VERSION "HINBNNNYNNNNNNNNNNNNNNNNNNNNNNNNNNNYYNNNNN/4>%%%/4/'%**4NNN///"

NS_ :

BS_:

BU_: Traffic Tester CGW ADU
BO_ 2564550625 Functional_Diag_RequestOn_bo: 8 CGW
 SG_ Sig_Functional_Diag_RequestOn_bo : 7|64@0+ (1,0) [0|0] ""  ADU

BO_ 2564481413 FLR_Diag_Tx_E1: 32 ADU
 SG_ Sig_FLR_Diag_Tx_E1 : 7|256@0+ (1,0) [0|0] ""  CGW

BO_ 2564457953 FLR_Diag_Rx_E1: 32 CGW
 SG_ Sig_FLR_Diag_Rx_E1 : 7|256@0+ (1,0) [0|0] ""  ADU

BO_ 2564481412 FRR_Diag_Tx_E1: 32 ADU
 SG_ Sig_FRR_Diag_Tx_E1 : 7|256@0+ (1,0) [0|0] ""  CGW

BO_ 2564457697 FRR_Diag_Rx_E1: 32 CGW
 SG_ Sig_FRR_Diag_Rx_E1 : 7|256@0+ (1,0) [0|0] ""  ADU

BO_ 2564481411 RLR_Diag_Tx_E1: 32 ADU
 SG_ Sig_RLR_Diag_Tx_E1 : 7|256@0+ (1,0) [0|0] ""  CGW

BO_ 2564457441 RLR_Diag_Rx_E1: 32 CGW
 SG_ Sig_RLR_Diag_Rx_E1 : 7|256@0+ (1,0) [0|0] ""  ADU

BO_ 2564481410 RRR_Diag_Tx_E1: 32 ADU
 SG_ Sig_RRR_Diag_Tx_E1 : 7|256@0+ (1,0) [0|0] ""  CGW

BO_ 2564457185 RRR_Diag_Rx_E1: 32 CGW
 SG_ Sig_RRR_Diag_Rx_E1 : 7|256@0+ (1,0) [0|0] ""  ADU

BO_ 2564481397 ADU_Diag_Tx_E1: 32 ADU
 SG_ Sig_ADU_Diag_Tx_E1 : 7|256@0+ (1,0) [0|0] ""  CGW

BO_ 2564453857 ADU_Diag_Rx_E1: 32 CGW
 SG_ Sig_ADU_Diag_Rx_E1 : 7|256@0+ (1,0) [0|0] ""  ADU

BO_ 2564481392 FRD_Diag_Tx_E1: 32 ADU
 SG_ Sig_FRD_Diag_Tx_E1 : 7|256@0+ (1,0) [0|0] ""  CGW

BO_ 2564452577 FRD_Diag_Rx_E1: 32 CGW
 SG_ Sig_FRD_Diag_Rx_E1 : 7|256@0+ (1,0) [0|0] ""  ADU

BO_ 2564550624 Functional_Diag_RequestOff_b: 8 CGW
 SG_ Sig_Functional_Diag_RequestOff_b : 7|64@0+ (1,0) [0|0] ""  ADU

BO_ 2564481157 FLR_Diag_Tx_E0: 32 ADU
 SG_ Sig_FLR_Diag_Tx_E0 : 7|256@0+ (1,0) [0|0] ""  CGW

BO_ 2564457952 FLR_Diag_Rx_E0: 32 CGW
 SG_ Sig_FLR_Diag_Rx_E0 : 7|256@0+ (1,0) [0|0] ""  ADU

BO_ 2564481156 FRR_Diag_Tx_E0: 32 ADU
 SG_ Sig_FRR_Diag_Tx_E0 : 7|256@0+ (1,0) [0|0] ""  CGW

BO_ 2564457696 FRR_Diag_Rx_E0: 32 CGW
 SG_ Sig_FRR_Diag_Rx_E0 : 7|256@0+ (1,0) [0|0] ""  ADU

BO_ 2564481155 RLR_Diag_Tx_E0: 32 ADU
 SG_ Sig_RLR_Diag_Tx_E0 : 7|256@0+ (1,0) [0|0] ""  CGW

BO_ 2564457440 RLR_Diag_Rx_E0: 32 CGW
 SG_ Sig_RLR_Diag_Rx_E0 : 7|256@0+ (1,0) [0|0] ""  ADU

BO_ 2564481154 RRR_Diag_Tx_E0: 32 ADU
 SG_ Sig_RRR_Diag_Tx_E0 : 7|256@0+ (1,0) [0|0] ""  CGW

BO_ 2564457184 RRR_Diag_Rx_E0: 32 CGW
 SG_ Sig_RRR_Diag_Rx_E0 : 7|256@0+ (1,0) [0|0] ""  ADU

BO_ 2564481141 ADU_Diag_Tx_E0: 32 ADU
 SG_ Sig_ADU_Diag_Tx_E0 : 7|256@0+ (1,0) [0|0] ""  CGW

BO_ 2564453856 ADU_Diag_Rx_E0: 32 CGW
 SG_ Sig_ADU_Diag_Rx_E0 : 7|256@0+ (1,0) [0|0] ""  ADU

BO_ 2564481136 FRD_Diag_Tx_E0: 32 ADU
 SG_ Sig_FRD_Diag_Tx_E0 : 7|256@0+ (1,0) [0|0] ""  CGW

BO_ 2564452576 FRD_Diag_Rx_E0: 32 CGW
 SG_ Sig_FRD_Diag_Rx_E0 : 7|256@0+ (1,0) [0|0] ""  ADU

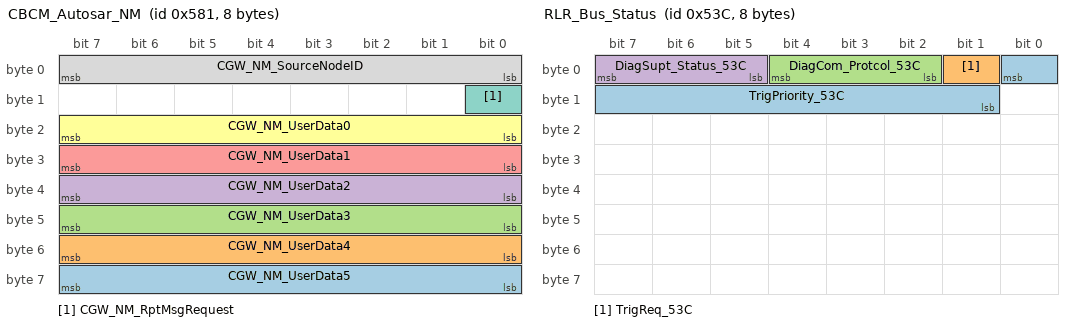
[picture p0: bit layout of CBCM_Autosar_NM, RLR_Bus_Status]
BO_ 1409 CBCM_Autosar_NM: 8 CGW
 SG_ CGW_NM_UserData5 : 63|8@0+ (1,0) [0|255] "" Vector__XXX
 SG_ CGW_NM_UserData4 : 55|8@0+ (1,0) [0|255] "" Vector__XXX
 SG_ CGW_NM_UserData3 : 47|8@0+ (1,0) [0|255] "" Vector__XXX
 SG_ CGW_NM_UserData2 : 39|8@0+ (1,0) [0|255] "" Vector__XXX
 SG_ CGW_NM_UserData1 : 31|8@0+ (1,0) [0|255] "" Vector__XXX
 SG_ CGW_NM_UserData0 : 23|8@0+ (1,0) [0|255] "" Vector__XXX
 SG_ CGW_NM_RptMsgRequest : 8|1@0+ (1,0) [0|1] ""  ADU
 SG_ CGW_NM_SourceNodeID : 7|8@0+ (1,0) [0|255] ""  ADU

BO_ 1340 RLR_Bus_Status: 8 ADU
 SG_ TrigPriority_53C : 0|8@0+ (1,0) [0|255] "HEX"  CGW
 SG_ TrigReq_53C : 1|1@0+ (1,0) [0|0] ""  CGW
 SG_ DiagCom_Protcol_53C : 4|3@0+ (1,0) [0|0] ""  CGW
 SG_ DiagSupt_Status_53C : 7|3@0+ (1,0) [0|0] ""  CGW

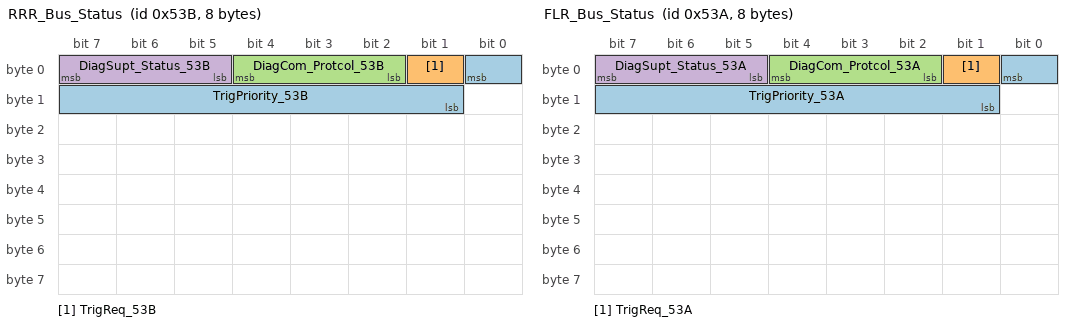
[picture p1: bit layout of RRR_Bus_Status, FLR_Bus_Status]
BO_ 1339 RRR_Bus_Status: 8 ADU
 SG_ TrigPriority_53B : 0|8@0+ (1,0) [0|255] "HEX"  CGW
 SG_ TrigReq_53B : 1|1@0+ (1,0) [0|0] ""  CGW
 SG_ DiagCom_Protcol_53B : 4|3@0+ (1,0) [0|0] ""  CGW
 SG_ DiagSupt_Status_53B : 7|3@0+ (1,0) [0|0] ""  CGW

BO_ 1338 FLR_Bus_Status: 8 ADU
 SG_ TrigPriority_53A : 0|8@0+ (1,0) [0|255] "HEX"  CGW
 SG_ TrigReq_53A : 1|1@0+ (1,0) [0|0] ""  CGW
 SG_ DiagCom_Protcol_53A : 4|3@0+ (1,0) [0|0] ""  CGW
 SG_ DiagSupt_Status_53A : 7|3@0+ (1,0) [0|0] ""  CGW

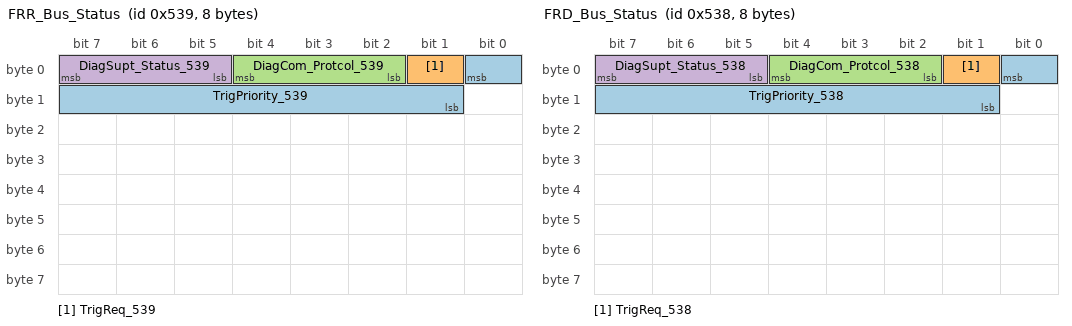
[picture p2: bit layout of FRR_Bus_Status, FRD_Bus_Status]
BO_ 1337 FRR_Bus_Status: 8 ADU
 SG_ TrigPriority_539 : 0|8@0+ (1,0) [0|255] "HEX"  CGW
 SG_ TrigReq_539 : 1|1@0+ (1,0) [0|0] ""  CGW
 SG_ DiagCom_Protcol_539 : 4|3@0+ (1,0) [0|0] ""  CGW
 SG_ DiagSupt_Status_539 : 7|3@0+ (1,0) [0|0] ""  CGW

BO_ 1336 FRD_Bus_Status: 8 ADU
 SG_ TrigPriority_538 : 0|8@0+ (1,0) [0|255] "HEX"  CGW
 SG_ TrigReq_538 : 1|1@0+ (1,0) [0|0] ""  CGW
 SG_ DiagCom_Protcol_538 : 4|3@0+ (1,0) [0|0] ""  CGW
 SG_ DiagSupt_Status_538 : 7|3@0+ (1,0) [0|0] ""  CGW

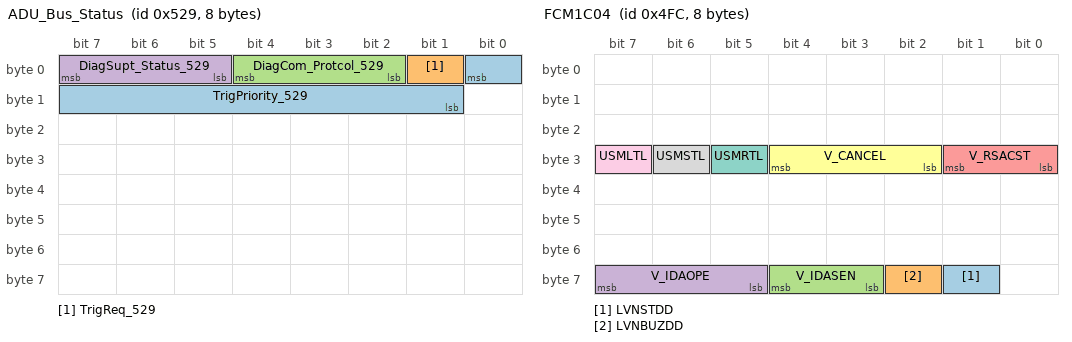
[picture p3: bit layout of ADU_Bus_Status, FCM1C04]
BO_ 1321 ADU_Bus_Status: 8 ADU
 SG_ TrigPriority_529 : 0|8@0+ (1,0) [0|255] "HEX"  CGW
 SG_ TrigReq_529 : 1|1@0+ (1,0) [0|0] ""  CGW
 SG_ DiagCom_Protcol_529 : 4|3@0+ (1,0) [0|0] ""  CGW
 SG_ DiagSupt_Status_529 : 7|3@0+ (1,0) [0|0] ""  CGW

BO_ 1276 FCM1C04: 8 ADU
 SG_ LVNSTDD : 57|1@0+ (1,0) [0|1] ""  CGW
 SG_ LVNBUZDD : 58|1@0+ (1,0) [0|1] ""  CGW
 SG_ V_IDASEN : 60|2@0+ (1,0) [0|0] ""  CGW
 SG_ V_IDAOPE : 63|3@0+ (1,0) [0|0] ""  CGW
 SG_ V_RSACST : 25|2@0+ (1,0) [0|3] ""  CGW
 SG_ V_CANCEL : 28|3@0+ (1,0) [0|7] ""  CGW
 SG_ USMRTL : 29|1@0+ (1,0) [0|0] ""  CGW
 SG_ USMSTL : 30|1@0+ (1,0) [0|0] ""  CGW
 SG_ USMLTL : 31|1@0+ (1,0) [0|0] ""  CGW

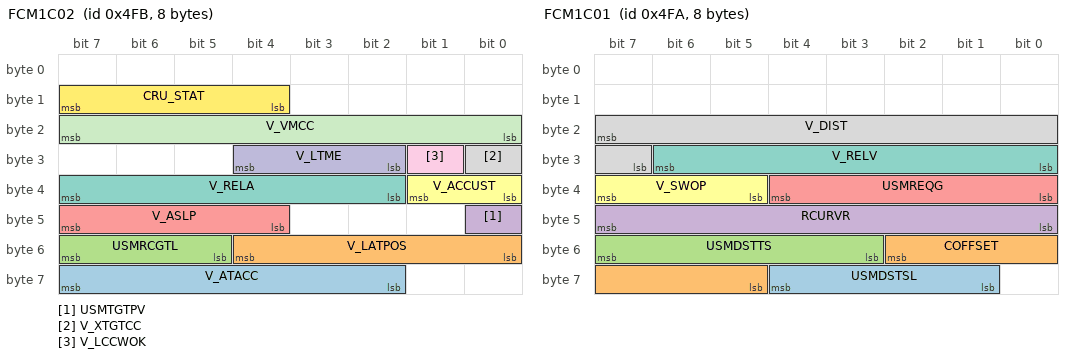
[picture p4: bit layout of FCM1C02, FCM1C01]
BO_ 1275 FCM1C02: 8 ADU
 SG_ V_ATACC : 63|6@0- (0.2,0) [-6.4|6.2] "m/s^2"  CGW
 SG_ V_LATPOS : 52|5@0- (0.4,0) [-6.4|6] "m/s2"  CGW
 SG_ USMRCGTL : 55|3@0+ (1,0) [0|0] ""  CGW
 SG_ USMTGTPV : 40|1@0+ (1,0) [0|0] ""  CGW
 SG_ V_ASLP : 47|4@0- (1,0) [-8|7] "deg"  CGW
 SG_ V_ACCUST : 33|2@0+ (1,0) [0|3] ""  CGW
 SG_ V_RELA : 39|6@0- (0.4,0) [-12.8|12.4] "m/s2"  CGW
 SG_ V_XTGTCC : 24|1@0+ (1,0) [0|1] ""  CGW
 SG_ V_LCCWOK : 25|1@0+ (1,0) [0|1] ""  CGW
 SG_ V_LTME : 28|3@0+ (1,0) [0|7] ""  CGW
 SG_ V_VMCC : 23|8@0+ (1,0) [0|255] "km/h"  CGW
 SG_ CRU_STAT : 15|4@0+ (1,0) [0|15] ""  CGW

BO_ 1274 FCM1C01: 8 ADU
 SG_ USMDSTSL : 60|4@0+ (4,0) [0|60] "m"  CGW
 SG_ COFFSET : 50|6@0- (0.03,0) [-0.96|0.93] "m"  CGW
 SG_ USMDSTTS : 55|5@0+ (5,0) [0|155] "m"  CGW
 SG_ RCURVR : 47|8@0- (10,0) [-1280|1270] "m"  CGW
 SG_ USMREQG : 36|5@0+ (0.1,-3.1) [-3.1|0] "m/s^2"  CGW
 SG_ V_SWOP : 39|3@0+ (1,0) [0|7] ""  CGW
 SG_ V_RELV : 30|7@0- (0.2,0) [-12.8|12.4] "m/s"  CGW
 SG_ V_DIST : 23|9@0+ (0.5,0) [0|255.5] "m"  CGW

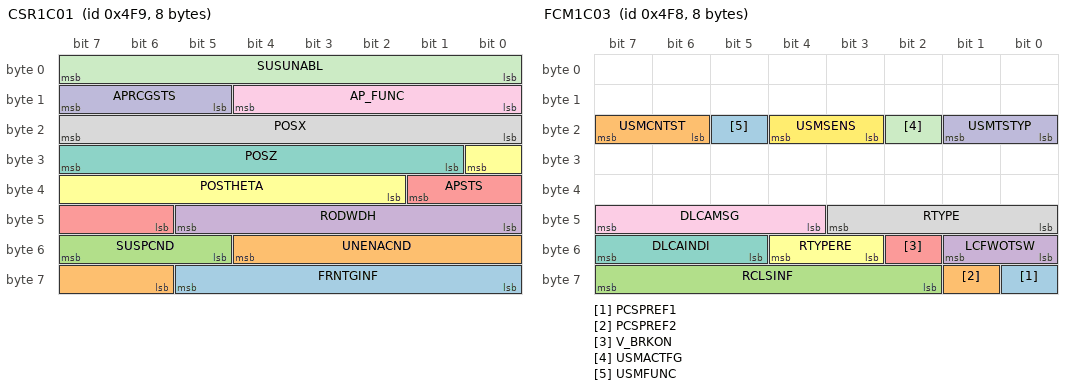
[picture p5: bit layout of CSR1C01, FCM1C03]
BO_ 1273 CSR1C01: 8 ADU
 SG_ FRNTGINF : 61|6@0+ (0.2,0) [0|12.6] "m"  CGW
 SG_ UNENACND : 52|7@0+ (1,0) [0|127] ""  CGW
 SG_ SUSPCND : 55|3@0+ (1,0) [0|7] ""  CGW
 SG_ RODWDH : 45|6@0+ (0.2,0) [0|12.6] "m"  CGW
 SG_ APSTS : 33|4@0+ (1,0) [0|15] ""  CGW
 SG_ POSTHETA : 24|7@0- (1.5,90) [-6|184.5] "deg"  CGW
 SG_ POSZ : 31|7@0- (0.1,5) [-1.4|11.3] "m"  CGW
 SG_ POSX : 23|8@0- (0.1,0) [-12.8|12.6] "m"  CGW
 SG_ AP_FUNC : 12|5@0+ (1,0) [0|31] ""  CGW
 SG_ APRCGSTS : 15|3@0+ (1,0) [0|7] ""  CGW
 SG_ SUSUNABL : 7|8@0+ (1,0) [0|255] ""  CGW

BO_ 1272 FCM1C03: 8 ADU
 SG_ PCSPREF1 : 56|1@0+ (1,0) [0|1] ""  CGW
 SG_ PCSPREF2 : 57|1@0+ (1,0) [0|1] ""  CGW
 SG_ RCLSINF : 63|6@0+ (1,0) [0|63] ""  CGW
 SG_ LCFWOTSW : 49|2@0+ (1,0) [0|3] ""  CGW
 SG_ V_BRKON : 50|1@0+ (1,0) [0|1] ""  CGW
 SG_ RTYPERE : 52|2@0+ (1,0) [0|3] ""  CGW
 SG_ DLCAINDI : 55|3@0+ (1,0) [0|7] ""  CGW
 SG_ RTYPE : 43|4@0+ (1,0) [0|15] ""  CGW
 SG_ DLCAMSG : 47|4@0+ (1,0) [0|15] ""  CGW
 SG_ USMTSTYP : 17|2@0+ (1,0) [0|0] ""  CGW
 SG_ USMACTFG : 18|1@0+ (1,0) [0|0] ""  CGW
 SG_ USMSENS : 20|2@0+ (1,0) [0|0] ""  CGW
 SG_ USMFUNC : 21|1@0+ (1,0) [0|0] ""  CGW
 SG_ USMCNTST : 23|2@0+ (1,0) [0|0] ""  CGW

BO_ 1269 CSR1D80: 32 ADU
 SG_ EDRAP : 250|3@0+ (1,0) [0|7] ""  CGW
 SG_ EDRRCP : 253|3@0+ (1,0) [0|7] ""  CGW

BO_ 1268 ADU1N01: 8 ADU
 SG_ ADUREV : 7|8@0+ (1,0) [0|255] ""  CGW

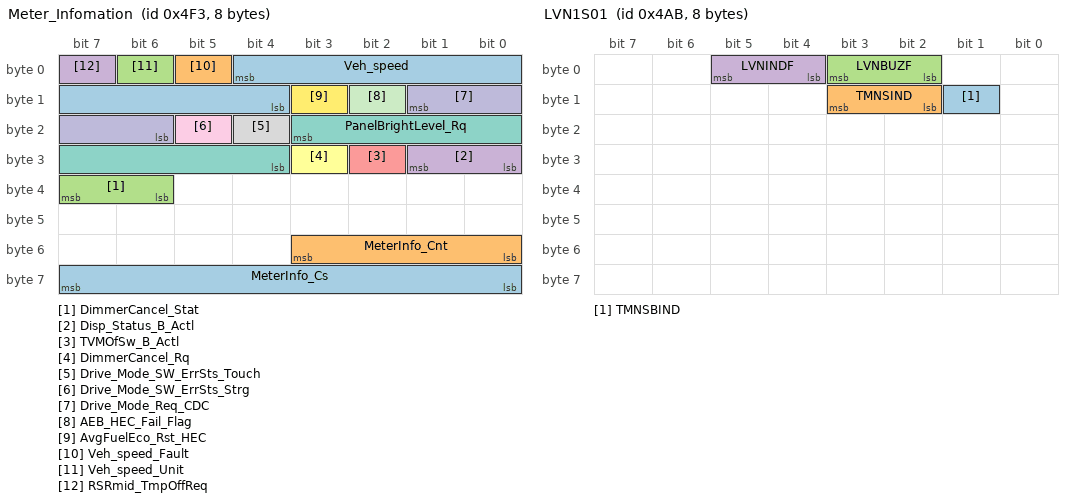
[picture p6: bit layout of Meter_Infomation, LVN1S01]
BO_ 1267 Meter_Infomation: 8 CGW
 SG_ MeterInfo_Cs : 63|8@0+ (1,0) [0|255] ""  ADU
 SG_ MeterInfo_Cnt : 51|4@0+ (1,0) [0|15] ""  ADU
 SG_ DimmerCancel_Stat : 39|2@0+ (1,0) [0|0] "" Vector__XXX
 SG_ Disp_Status_B_Actl : 25|2@0+ (1,0) [0|0] ""  ADU
 SG_ TVMOfSw_B_Actl : 26|1@0+ (1,0) [0|0] ""  ADU
 SG_ DimmerCancel_Rq : 27|1@0+ (1,0) [0|0] "" Vector__XXX
 SG_ PanelBrightLevel_Rq : 19|8@0+ (1,0) [0|100] "%" Vector__XXX
 SG_ Drive_Mode_SW_ErrSts_Touch : 20|1@0+ (1,0) [0|0] "" Vector__XXX
 SG_ Drive_Mode_SW_ErrSts_Strg : 21|1@0+ (1,0) [0|0] "" Vector__XXX
 SG_ Drive_Mode_Req_CDC : 9|4@0+ (1,0) [0|0] "" Vector__XXX
 SG_ AEB_HEC_Fail_Flag : 10|1@0+ (1,0) [0|0] ""  ADU
 SG_ AvgFuelEco_Rst_HEC : 11|1@0+ (1,0) [0|0] "" Vector__XXX
 SG_ Veh_speed : 4|9@0+ (1,0) [0|511] ""  ADU
 SG_ Veh_speed_Fault : 5|1@0+ (1,0) [0|0] ""  ADU
 SG_ Veh_speed_Unit : 6|1@0+ (1,0) [0|0] ""  ADU
 SG_ RSRmid_TmpOffReq : 7|1@0+ (1,0) [0|0] "" Vector__XXX

BO_ 1259 DS11S40: 8 ADU
 SG_ CTACANC : 19|1@0+ (1,0) [0|1] ""  CGW

BO_ 1258 DS11S27: 8 ADU
 SG_ HELPREQ : 43|1@0+ (1,0) [0|0] ""  CGW

BO_ 1256 RSE1S02: 8 CGW
 SG_ RSCYCL16 : 63|8@0+ (1,0) [0|255] ""  ADU
 SG_ RSCYCL15 : 55|8@0+ (1,0) [0|255] ""  ADU

BO_ 1195 LVN1S01: 8 ADU
 SG_ TMNSBIND : 9|1@0+ (1,0) [0|1] ""  CGW
 SG_ TMNSIND : 11|2@0+ (1,0) [0|3] ""  CGW
 SG_ LVNBUZF : 3|2@0+ (1,0) [0|3] ""  CGW
 SG_ LVNINDF : 5|2@0+ (1,0) [0|3] ""  CGW

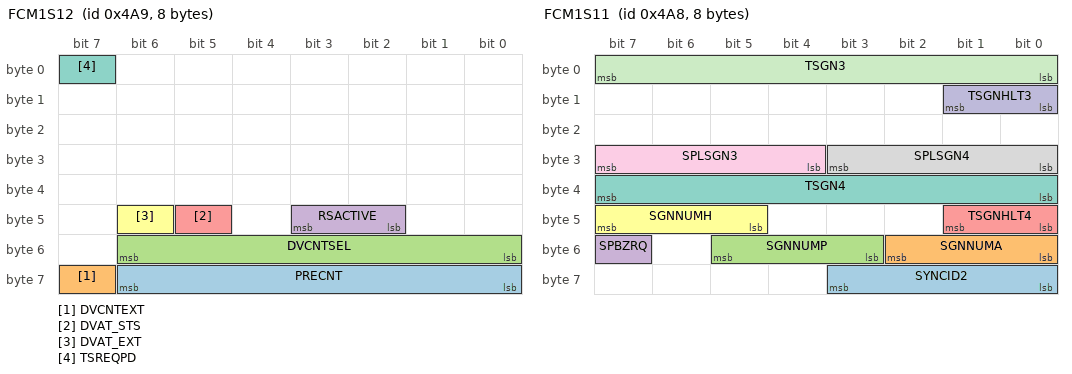
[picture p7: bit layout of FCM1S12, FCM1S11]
BO_ 1193 FCM1S12: 8 ADU
 SG_ PRECNT : 62|7@0+ (1,0) [0|127] ""  CGW
 SG_ DVCNTEXT : 63|1@0+ (1,0) [0|1] ""  CGW
 SG_ DVCNTSEL : 54|7@0+ (1,0) [0|127] ""  CGW
 SG_ RSACTIVE : 43|2@0+ (1,0) [0|3] ""  CGW
 SG_ DVAT_STS : 45|1@0+ (1,0) [0|1] ""  CGW
 SG_ DVAT_EXT : 46|1@0+ (1,0) [0|1] ""  CGW
 SG_ TSREQPD : 7|1@0+ (1,0) [0|1] ""  CGW

BO_ 1192 FCM1S11: 8 ADU
 SG_ SYNCID2 : 59|4@0+ (1,0) [0|15] ""  CGW
 SG_ SGNNUMA : 50|3@0+ (1,0) [0|7] ""  CGW
 SG_ SGNNUMP : 53|3@0+ (1,0) [0|7] ""  CGW
 SG_ SPBZRQ : 55|1@0+ (1,0) [0|1] ""  CGW
 SG_ TSGNHLT4 : 41|2@0+ (1,0) [0|3] ""  CGW
 SG_ SGNNUMH : 47|3@0+ (1,0) [0|7] ""  CGW
 SG_ TSGN4 : 39|8@0+ (1,0) [0|255] ""  CGW
 SG_ SPLSGN4 : 27|4@0+ (1,0) [0|15] ""  CGW
 SG_ SPLSGN3 : 31|4@0+ (1,0) [0|15] ""  CGW
 SG_ TSGNHLT3 : 9|2@0+ (1,0) [0|3] ""  CGW
 SG_ TSGN3 : 7|8@0+ (1,0) [0|255] ""  CGW

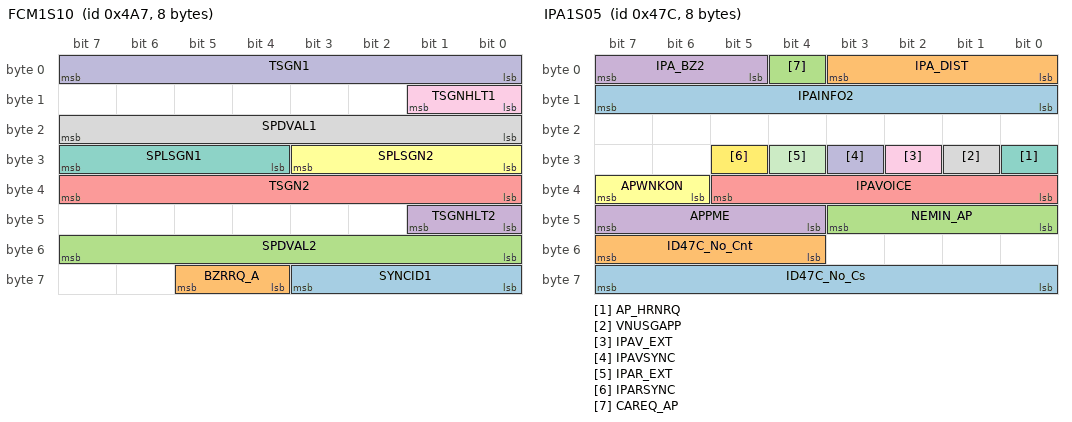
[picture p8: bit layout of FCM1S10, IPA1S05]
BO_ 1191 FCM1S10: 8 ADU
 SG_ SYNCID1 : 59|4@0+ (1,0) [0|15] ""  CGW
 SG_ BZRRQ_A : 61|2@0+ (1,0) [0|3] ""  CGW
 SG_ SPDVAL2 : 55|8@0+ (1,0) [0|255] ""  CGW
 SG_ TSGNHLT2 : 41|2@0+ (1,0) [0|3] ""  CGW
 SG_ TSGN2 : 39|8@0+ (1,0) [0|255] ""  CGW
 SG_ SPLSGN2 : 27|4@0+ (1,0) [0|15] ""  CGW
 SG_ SPLSGN1 : 31|4@0+ (1,0) [0|15] ""  CGW
 SG_ SPDVAL1 : 23|8@0+ (1,0) [0|255] ""  CGW
 SG_ TSGNHLT1 : 9|2@0+ (1,0) [0|3] ""  CGW
 SG_ TSGN1 : 7|8@0+ (1,0) [0|255] ""  CGW

BO_ 1182 ADU_Customize_Status_GUI_01: 32 ADU
 SG_ CstmzStat_RCD_ONOFF_GUI : 229|2@0+ (1,0) [0|0] ""  CGW
 SG_ CstmzStat_TAP_ALERT_ONOFF_GUI : 231|2@0+ (1,0) [0|0] ""  CGW
 SG_ CstmzStat_APS_RPC_DISTANCE_GUI : 217|2@0+ (1,0) [0|0] ""  CGW
 SG_ CstmzStat_PK_TrvB_EndP_GUI : 223|2@0+ (1,0) [0|0] ""  CGW
 SG_ CstmzStat_PK_TrvF_EndP_GUI : 209|2@0+ (1,0) [0|0] ""  CGW
 SG_ CstmzStat_PK_VehBLen_GUI : 211|2@0+ (1,0) [0|0] ""  CGW
 SG_ CstmzStat_PKout_View_GUI : 213|2@0+ (1,0) [0|0] ""  CGW
 SG_ CstmzStat_PKin_View_GUI : 215|2@0+ (1,0) [0|0] ""  CGW
 SG_ CstmzStat_PKout_PallalelDir_GUI : 201|2@0+ (1,0) [0|0] ""  CGW
 SG_ CstmzStat_PKout_CrossDir_GUI : 203|2@0+ (1,0) [0|0] ""  CGW
 SG_ CstmzStat_PK_Rd_Wid_GUI : 205|2@0+ (1,0) [0|0] ""  CGW
 SG_ CstmzStat_PK_Trv_Line_GUI : 207|2@0+ (1,0) [0|0] ""  CGW
 SG_ CstmzStat_PK_Veh_Dir_GUI : 193|2@0+ (1,0) [0|0] ""  CGW
 SG_ CstmzStat_APVSPD_LVL_GUI : 195|2@0+ (1,0) [0|0] ""  CGW
 SG_ CstmzStat_GUIDE_ONOFF_GUI : 197|2@0+ (1,0) [0|0] ""  CGW
 SG_ CstmzStat_RPC_ONOFF_GUI : 199|2@0+ (1,0) [0|0] ""  CGW
 SG_ CstmzStat_ACC_GDMS_ONOFF_GUI : 173|2@0+ (1,0) [0|0] ""  CGW
 SG_ CstmzStat_ACC_ACCL_Sens_GUI : 175|2@0+ (1,0) [0|0] ""  CGW
 SG_ CstmzStat_ACC_CURVE_Sens_GUI : 161|2@0+ (1,0) [0|0] ""  CGW
 SG_ CstmzStat_ACC_OVTK_ONOFF_GUI : 163|2@0+ (1,0) [0|0] ""  CGW
 SG_ CstmzStat_TMN_LV_Sens_GUI : 165|2@0+ (1,0) [0|0] ""  CGW
 SG_ CstmzStat_TMN_TS_Sens_GUI : 167|2@0+ (1,0) [0|0] ""  CGW
 SG_ CstmzStat_LCA_ONOFF_GUI : 157|2@0+ (1,0) [0|0] ""  CGW
 SG_ CstmzStat_HOF_REC_ONOFF_GUI : 159|2@0+ (1,0) [0|0] ""  CGW
 SG_ CstmzStat_HOF_ONOFF_GUI : 145|2@0+ (1,0) [0|0] ""  CGW
 SG_ CstmzStat_ESA_AES_ONOFF_GUI : 147|2@0+ (1,0) [0|0] ""  CGW
 SG_ CstmzStat_PDA_Sens_GUI : 149|2@0+ (1,0) [0|0] ""  CGW
 SG_ CstmzStat_PDA_ONOFF_GUI : 151|2@0+ (1,0) [0|0] ""  CGW
 SG_ CstmzStat_TVM_MOAAuto_ONOFF_GUI : 139|2@0+ (1,0) [0|0] ""  CGW
 SG_ CstmzStat_TVM_MOA_ONOFF_GUI : 141|2@0+ (1,0) [0|0] ""  CGW
 SG_ CstmzStat_TVM_AutoOFF_ONOFF_GUI : 143|2@0+ (1,0) [0|0] ""  CGW
 SG_ CstmzStat_TVM_PASRear_Sens_GUI : 131|2@0+ (1,0) [0|0] ""  CGW
 SG_ CstmzStat_TVM_PASFront_Sens_GUI : 133|2@0+ (1,0) [0|0] ""  CGW
 SG_ CstmzStat_TVM_PAS_ONOFF_GUI : 135|2@0+ (1,0) [0|0] ""  CGW
 SG_ CstmzStat_PAS_Vol_GUI : 111|2@0+ (1,0) [0|0] ""  CGW
 SG_ CstmzStat_PAS_ONOFF_GUI : 99|2@0+ (1,0) [0|0] ""  CGW
 SG_ CstmzStat_EDA_ONOFF_GUI : 101|2@0+ (1,0) [0|0] ""  CGW
 SG_ CstmzStat_EDA_Sleep_ONOFF_GUI : 103|2@0+ (1,0) [0|0] ""  CGW
 SG_ CstmzStat_DM_ONOFF_GUI : 89|2@0+ (1,0) [0|0] ""  CGW
 SG_ CstmzStat_OCP_ONOFF_GUI : 91|2@0+ (1,0) [0|0] ""  CGW
 SG_ CstmzStat_BSP_ONOFF_GUI : 93|2@0+ (1,0) [0|0] ""  CGW
 SG_ CstmzStat_RDP_ONOFF_GUI : 95|2@0+ (1,0) [0|0] ""  CGW
 SG_ CstmzStat_ELK_ONOFF_GUI : 81|2@0+ (1,0) [0|0] ""  CGW
 SG_ CstmzStat_RAEB_ONOFF_GUI : 87|2@0+ (1,0) [0|0] ""  CGW
 SG_ CstmzStat_HeadOn_ONOFF_GUI : 73|2@0+ (1,0) [0|0] ""  CGW
 SG_ CstmzStat_TAP_ONOFF_GUI : 75|2@0+ (1,0) [0|0] ""  CGW
 SG_ CstmzStat_CTB_ONOFF_GUI : 77|2@0+ (1,0) [0|0] ""  CGW
 SG_ CstmzStat_AEB_Vol_GUI : 79|2@0+ (1,0) [0|0] ""  CGW
 SG_ CstmzStat_FAEB_ONOFF_GUI : 65|2@0+ (1,0) [0|0] ""  CGW
 SG_ CstmzStat_LDP_ONOFF_GUI : 67|2@0+ (1,0) [0|0] ""  CGW
 SG_ CstmzStat_CBDA_Sens_GUI : 69|2@0+ (1,0) [0|0] ""  CGW
 SG_ CstmzStat_CBDA_ONOFF_GUI : 71|2@0+ (1,0) [0|0] ""  CGW
 SG_ CstmzStat_TSR_Warn_GUI_SignBz : 63|2@0+ (1,0) [0|0] ""  CGW
 SG_ CstmzStat_TSR_Warn_GUI_Sign : 49|2@0+ (1,0) [0|0] ""  CGW
 SG_ CstmzStat_TSR_Warn_GUI_OFF : 51|2@0+ (1,0) [0|0] ""  CGW
 SG_ CstmzStat_LDW_ELK_Warn_GUI : 53|2@0+ (1,0) [0|0] ""  CGW
 SG_ CstmzStat_BSM_Sens_GUI : 55|2@0+ (1,0) [0|0] ""  CGW
 SG_ CstmzStat_BSM_ONOFF_GUI : 41|2@0+ (1,0) [0|0] ""  CGW
 SG_ CstmzStat_LDW_ONOFF_GUI : 43|2@0+ (1,0) [0|0] ""  CGW
 SG_ CstmzStat_RCTA_ONOFF_GUI : 45|2@0+ (1,0) [0|0] ""  CGW
 SG_ CstmzStat_FCTA_Sens_GUI : 47|2@0+ (1,0) [0|0] ""  CGW
 SG_ CstmzStat_FCTA_ONOFF_GUI : 33|2@0+ (1,0) [0|0] ""  CGW
 SG_ CstmzStat_TSRWarnThres_GUI_10 : 31|2@0+ (1,0) [0|0] ""  CGW
 SG_ CstmzStat_TSRWarnThres_GUI_5 : 17|2@0+ (1,0) [0|0] ""  CGW
 SG_ CstmzStat_TSRWarnThres_GUI_3 : 19|2@0+ (1,0) [0|0] ""  CGW
 SG_ CstmzStat_TSRWarnThres_GUI_0 : 21|2@0+ (1,0) [0|0] ""  CGW
 SG_ CstmzStat_TSR_Change_GUI : 9|2@0+ (1,0) [0|0] ""  CGW
 SG_ CstmzStat_TSR_NextInfo_GUI : 11|2@0+ (1,0) [0|0] ""  CGW
 SG_ CstmzStat_TSR_ONOFF_GUI : 13|2@0+ (1,0) [0|0] ""  CGW
 SG_ CstmzStat_ISA_TSR_ADJST_GUI : 15|2@0+ (1,0) [0|0] ""  CGW
 SG_ CstmzStat_IACC_TSR_ADJST_GUI : 1|2@0+ (1,0) [0|0] ""  CGW
 SG_ CstmzStat_MRCC_TSR_Mode_GUI : 3|2@0+ (1,0) [0|0] ""  CGW
 SG_ CstmzStat_MRCC_ASC_Mode_GUI : 5|2@0+ (1,0) [0|0] ""  CGW

BO_ 1170 ADU_Customize_Status_01: 32 ADU
 SG_ CstmzStat_RCD_ONOFF : 247|2@0+ (1,0) [0|0] ""  CGW
 SG_ CstmzStat_TAP_ALERT_ONOFF : 233|2@0+ (1,0) [0|0] ""  CGW
 SG_ CstmzStat_APS_RPC_DISTANCE : 235|2@0+ (1,0) [0|0] ""  CGW
 SG_ CstmzStat_PK_TrvB_EndP : 225|4@0+ (1,0) [0|0] ""  CGW
 SG_ CstmzStat_PK_TrvF_EndP : 229|4@0+ (1,0) [0|0] ""  CGW
 SG_ CstmzStat_PK_VehBLen : 217|4@0+ (1,0) [0|0] ""  CGW
 SG_ CstmzStat_PKout_View : 219|2@0+ (1,0) [0|0] ""  CGW
 SG_ CstmzStat_PKin_View : 221|2@0+ (1,0) [0|0] ""  CGW
 SG_ CstmzStat_PKout_PallalelDir : 223|2@0+ (1,0) [0|0] ""  CGW
 SG_ CstmzStat_PKout_CrossDir : 209|2@0+ (1,0) [0|0] ""  CGW
 SG_ CstmzStat_PK_Rd_Wid : 211|2@0+ (1,0) [0|0] ""  CGW
 SG_ CstmzStat_PK_Trv_Line : 215|4@0+ (1,0) [0|0] ""  CGW
 SG_ CstmzStat_PK_Veh_Dir : 201|2@0+ (1,0) [0|0] ""  CGW
 SG_ CstmzStat_APVSPD_LVL : 203|2@0+ (1,0) [0|0] ""  CGW
 SG_ CstmzStat_GUIDE_ONOFF : 205|2@0+ (1,0) [0|0] ""  CGW
 SG_ CstmzStat_RPC_ONOFF : 207|2@0+ (1,0) [0|0] ""  CGW
 SG_ CstmzStat_ACC_GCR_ONOFF : 190|2@0+ (1,0) [0|0] ""  CGW
 SG_ CstmzStat_ACC_ACCL_Sens : 177|3@0+ (1,0) [0|0] ""  CGW
 SG_ CstmzStat_ACC_CURVE_Sens : 180|3@0+ (1,0) [0|0] ""  CGW
 SG_ CstmzStat_ACC_OVTK_ONOFF : 182|2@0+ (1,0) [0|0] ""  CGW
 SG_ CstmzStat_TMN_LV_Sens : 169|3@0+ (1,0) [0|0] ""  CGW
 SG_ CstmzStat_TMN_TS_Sens : 172|3@0+ (1,0) [0|0] ""  CGW
 SG_ CstmzStat_LCA_ONOFF : 162|2@0+ (1,0) [0|0] ""  CGW
 SG_ CstmzStat_HOF_REC_ONOFF : 164|2@0+ (1,0) [0|0] ""  CGW
 SG_ CstmzStat_HOF_ONOFF : 166|2@0+ (1,0) [0|0] ""  CGW
 SG_ CstmzStat_ESA_AES_ONOFF : 152|2@0+ (1,0) [0|0] ""  CGW
 SG_ CstmzStat_PDA_Sens : 155|3@0+ (1,0) [0|0] ""  CGW
 SG_ CstmzStat_PDA_ONOFF : 157|2@0+ (1,0) [0|0] ""  CGW
 SG_ CstmzStat_TVM_MOAAuto_ONOFF : 145|2@0+ (1,0) [0|0] ""  CGW
 SG_ CstmzStat_TVM_MOA_ONOFF : 147|2@0+ (1,0) [0|0] ""  CGW
 SG_ CstmzStat_TVM_AutoOFF_ONOFF : 149|2@0+ (1,0) [0|0] ""  CGW
 SG_ CstmzStat_TVM_PASRear_Sens : 139|2@0+ (1,0) [0|0] ""  CGW
 SG_ CstmzStat_TVM_PASFront_Sens : 141|2@0+ (1,0) [0|0] ""  CGW
 SG_ CstmzStat_TVM_PAS_ONOFF : 143|2@0+ (1,0) [0|0] ""  CGW
 SG_ PrsnlSys_Switch_ID_ADU_Res : 120|1@0+ (1,0) [0|0] ""  CGW
 SG_ CstmzStat_PAS_Vol : 119|3@0+ (1,0) [0|0] ""  CGW
 SG_ CstmzStat_PAS_ONOFF : 107|2@0+ (1,0) [0|0] ""  CGW
 SG_ CstmzStat_EDA_ONOFF : 109|2@0+ (1,0) [0|0] ""  CGW
 SG_ CstmzStat_EDA_Sleep_ONOFF : 111|2@0+ (1,0) [0|0] ""  CGW
 SG_ CstmzStat_DM_ONOFF : 97|2@0+ (1,0) [0|0] ""  CGW
 SG_ CstmzStat_OCP_ONOFF : 99|2@0+ (1,0) [0|0] ""  CGW
 SG_ CstmzStat_BSP_ONOFF : 101|2@0+ (1,0) [0|0] ""  CGW
 SG_ CstmzStat_RDP_ONOFF : 103|2@0+ (1,0) [0|0] ""  CGW
 SG_ CstmzStat_ELK_ONOFF : 89|2@0+ (1,0) [0|0] ""  CGW
 SG_ CstmzStat_RAEB_ONOFF : 95|2@0+ (1,0) [0|0] ""  CGW
 SG_ CstmzStat_HeadOn_ONOFF : 81|2@0+ (1,0) [0|0] ""  CGW
 SG_ CstmzStat_TAP_ONOFF : 83|2@0+ (1,0) [0|0] ""  CGW
 SG_ CstmzStat_CTB_ONOFF : 85|2@0+ (1,0) [0|0] ""  CGW
 SG_ CstmzStat_AEB_Vol : 87|2@0+ (1,0) [0|0] ""  CGW
 SG_ CstmzStat_FAEB_ONOFF : 73|2@0+ (1,0) [0|0] ""  CGW
 SG_ CstmzStat_LDP_ONOFF : 75|2@0+ (1,0) [0|0] ""  CGW
 SG_ CstmzStat_CBDA_Sens : 77|2@0+ (1,0) [0|0] ""  CGW
 SG_ CstmzStat_CBDA_ONOFF : 79|2@0+ (1,0) [0|0] ""  CGW
 SG_ CstmzStat_LDW_ELK_Warn : 48|3@0+ (1,0) [0|0] ""  CGW
 SG_ CstmzStat_BSM_Sens : 50|2@0+ (1,0) [0|0] ""  CGW
 SG_ CstmzStat_BSM_ONOFF : 53|3@0+ (1,0) [0|0] ""  CGW
 SG_ CstmzStat_LDW_ONOFF : 55|2@0+ (1,0) [0|0] ""  CGW
 SG_ CstmzStat_RCTA_ONOFF : 41|2@0+ (1,0) [0|0] ""  CGW
 SG_ CstmzStat_FCTA_Sens : 43|2@0+ (1,0) [0|0] ""  CGW
 SG_ CstmzStat_FCTA_ONOFF : 45|2@0+ (1,0) [0|0] ""  CGW
 SG_ CstmzStat_TSRWarnThres : 39|3@0+ (1,0) [0|0] ""  CGW
 SG_ CstmzStat_TSR_Warn : 25|2@0+ (1,0) [0|0] ""  CGW
 SG_ CstmzStat_TSR_Change : 27|2@0+ (1,0) [0|0] ""  CGW
 SG_ CstmzStat_TSR_NextInfo : 29|2@0+ (1,0) [0|0] ""  CGW
 SG_ CstmzStat_TSR_ONOFF : 31|2@0+ (1,0) [0|0] ""  CGW
 SG_ CstmzStat_ISA_TSR_ADJST : 20|5@0+ (1,0) [0|0] ""  CGW
 SG_ CstmzStat_IACC_TSR_ADJST : 9|5@0+ (1,0) [0|0] ""  CGW
 SG_ CstmzStat_MRCC_TSR_Mode : 11|2@0+ (1,0) [0|0] ""  CGW
 SG_ CstmzStat_MRCC_ASC_Mode : 13|2@0+ (1,0) [0|0] ""  CGW

BO_ 1169 ADU_Customize_Response_01: 32 ADU
 SG_ CstmzRsp_RCD_ONOFF : 247|2@0+ (1,0) [0|0] ""  CGW
 SG_ CstmzRsp_TAP_ALERT_ONOFF : 233|2@0+ (1,0) [0|0] ""  CGW
 SG_ CstmzRsp_APS_RPC_DISTANCE : 235|2@0+ (1,0) [0|0] ""  CGW
 SG_ CstmzRsp_PK_TrvB_EndP : 225|4@0+ (1,0) [0|0] ""  CGW
 SG_ CstmzRsp_PK_TrvF_EndP : 229|4@0+ (1,0) [0|0] ""  CGW
 SG_ CstmzRsp_PK_VehBLen : 217|4@0+ (1,0) [0|0] ""  CGW
 SG_ CstmzRsp_PKout_View : 219|2@0+ (1,0) [0|0] ""  CGW
 SG_ CstmzRsp_PKin_View : 221|2@0+ (1,0) [0|0] ""  CGW
 SG_ CstmzRsp_PKout_PallalelDir : 223|2@0+ (1,0) [0|0] ""  CGW
 SG_ CstmzRsp_PKout_CrossDir : 209|2@0+ (1,0) [0|0] ""  CGW
 SG_ CstmzRsp_PK_Rd_Wid : 211|2@0+ (1,0) [0|0] ""  CGW
 SG_ CstmzRsp_PK_Trv_Line : 215|4@0+ (1,0) [0|0] ""  CGW
 SG_ CstmzRsp_PK_Veh_Dir : 201|2@0+ (1,0) [0|0] ""  CGW
 SG_ CstmzRsp_APVSPD_LVL : 203|2@0+ (1,0) [0|0] ""  CGW
 SG_ CstmzRsp_GUIDE_ONOFF : 205|2@0+ (1,0) [0|0] ""  CGW
 SG_ CstmzRsp_RPC_ONOFF : 207|2@0+ (1,0) [0|0] ""  CGW
 SG_ CstmzRsp_Status_VRsp04 : 193|2@0+ (1,0) [0|0] ""  CGW
 SG_ CstmzRsp_Contents_VRsp04 : 195|2@0+ (1,0) [0|0] ""  CGW
 SG_ CstmzRsp_ACC_GCR_ONOFF : 190|2@0+ (1,0) [0|0] ""  CGW
 SG_ CstmzRsp_ACC_ACCL_Sens : 177|3@0+ (1,0) [0|0] ""  CGW
 SG_ CstmzRsp_ACC_CURVE_Sens : 180|3@0+ (1,0) [0|0] ""  CGW
 SG_ CstmzRsp_ACC_OVTK_ONOFF : 182|2@0+ (1,0) [0|0] ""  CGW
 SG_ CstmzRsp_TMN_LV_Sens : 169|3@0+ (1,0) [0|0] ""  CGW
 SG_ CstmzRsp_TMN_TS_Sens : 172|3@0+ (1,0) [0|0] ""  CGW
 SG_ CstmzRsp_LCA_ONOFF : 162|2@0+ (1,0) [0|0] ""  CGW
 SG_ CstmzRsp_HOF_REC_ONOFF : 164|2@0+ (1,0) [0|0] ""  CGW
 SG_ CstmzRsp_HOF_ONOFF : 166|2@0+ (1,0) [0|0] ""  CGW
 SG_ CstmzRsp_ESA_AES_ONOFF : 152|2@0+ (1,0) [0|0] ""  CGW
 SG_ CstmzRsp_PDA_Sens : 155|3@0+ (1,0) [0|0] ""  CGW
 SG_ CstmzRsp_PDA_ONOFF : 157|2@0+ (1,0) [0|0] ""  CGW
 SG_ CstmzRsp_TVM_MOAAuto_ONOFF : 145|2@0+ (1,0) [0|0] ""  CGW
 SG_ CstmzRsp_TVM_MOA_ONOFF : 147|2@0+ (1,0) [0|0] ""  CGW
 SG_ CstmzRsp_TVM_AutoOFF_ONOFF : 149|2@0+ (1,0) [0|0] ""  CGW
 SG_ CstmzRsp_TVM_PASRear_Sens : 139|2@0+ (1,0) [0|0] ""  CGW
 SG_ CstmzRsp_TVM_PASFront_Sens : 141|2@0+ (1,0) [0|0] ""  CGW
 SG_ CstmzRsp_TVM_PAS_ONOFF : 143|2@0+ (1,0) [0|0] ""  CGW
 SG_ CstmzRsp_Status_VRsp03 : 129|2@0+ (1,0) [0|0] ""  CGW
 SG_ CstmzRsp_Contents_VRsp03 : 131|2@0+ (1,0) [0|0] ""  CGW
 SG_ CstmzRsp_Init_ALL_ADAS_Prsnl : 124|5@0+ (1,0) [0|0] ""  CGW
 SG_ CstmzRsp_PAS_Vol : 119|3@0+ (1,0) [0|0] ""  CGW
 SG_ CstmzRsp_PAS_ONOFF : 107|2@0+ (1,0) [0|0] ""  CGW
 SG_ CstmzRsp_EDA_ONOFF : 109|2@0+ (1,0) [0|0] ""  CGW
 SG_ CstmzRsp_EDA_Sleep_ONOFF : 111|2@0+ (1,0) [0|0] ""  CGW
 SG_ CstmzRsp_DM_ONOFF : 97|2@0+ (1,0) [0|0] ""  CGW
 SG_ CstmzRsp_OCP_ONOFF : 99|2@0+ (1,0) [0|0] ""  CGW
 SG_ CstmzRsp_BSP_ONOFF : 101|2@0+ (1,0) [0|0] ""  CGW
 SG_ CstmzRsp_RDP_ONOFF : 103|2@0+ (1,0) [0|0] ""  CGW
 SG_ CstmzRsp_ELK_ONOFF : 89|2@0+ (1,0) [0|0] ""  CGW
 SG_ CstmzRsp_RAEB_ONOFF : 95|2@0+ (1,0) [0|0] ""  CGW
 SG_ CstmzRsp_HeadOn_ONOFF : 81|2@0+ (1,0) [0|0] ""  CGW
 SG_ CstmzRsp_TAP_ONOFF : 83|2@0+ (1,0) [0|0] ""  CGW
 SG_ CstmzRsp_CTB_ONOFF : 85|2@0+ (1,0) [0|0] ""  CGW
 SG_ CstmzRsp_AEB_Vol : 87|2@0+ (1,0) [0|0] ""  CGW
 SG_ CstmzRsp_FAEB_ONOFF : 73|2@0+ (1,0) [0|0] ""  CGW
 SG_ CstmzRsp_LDP_ONOFF : 75|2@0+ (1,0) [0|0] ""  CGW
 SG_ CstmzRsp_CBDA_Sens : 77|2@0+ (1,0) [0|0] ""  CGW
 SG_ CstmzRsp_CBDA_ONOFF : 79|2@0+ (1,0) [0|0] ""  CGW
 SG_ CstmzRsp_Status_VRsp02 : 65|2@0+ (1,0) [0|0] ""  CGW
 SG_ CstmzRsp_Contents_VRsp02 : 67|2@0+ (1,0) [0|0] ""  CGW
 SG_ CstmzRsp_Init_ALL_ADAS : 57|2@0+ (1,0) [0|0] ""  CGW
 SG_ CstmzRsp_LDW_ELK_Warn : 48|3@0+ (1,0) [0|0] ""  CGW
 SG_ CstmzRsp_BSM_Sens : 50|2@0+ (1,0) [0|0] ""  CGW
 SG_ CstmzRsp_BSM_ONOFF : 53|3@0+ (1,0) [0|0] ""  CGW
 SG_ CstmzRsp_LDW_ONOFF : 55|2@0+ (1,0) [0|0] ""  CGW
 SG_ CstmzRsp_RCTA_ONOFF : 41|2@0+ (1,0) [0|0] ""  CGW
 SG_ CstmzRsp_FCTA_Sens : 43|2@0+ (1,0) [0|0] ""  CGW
 SG_ CstmzRsp_FCTA_ONOFF : 45|2@0+ (1,0) [0|0] ""  CGW
 SG_ CstmzRsp_TSRWarnThres : 39|3@0+ (1,0) [0|0] ""  CGW
 SG_ CstmzRsp_TSR_Warn : 25|2@0+ (1,0) [0|0] ""  CGW
 SG_ CstmzRsp_TSR_Change : 27|2@0+ (1,0) [0|0] ""  CGW
 SG_ CstmzRsp_TSR_NextInfo : 29|2@0+ (1,0) [0|0] ""  CGW
 SG_ CstmzRsp_TSR_ONOFF : 31|2@0+ (1,0) [0|0] ""  CGW
 SG_ CstmzRsp_ISA_TSR_ADJST : 20|5@0+ (1,0) [0|0] ""  CGW
 SG_ CstmzRsp_IACC_TSR_ADJST : 9|5@0+ (1,0) [0|0] ""  CGW
 SG_ CstmzRsp_MRCC_TSR_Mode : 11|2@0+ (1,0) [0|0] ""  CGW
 SG_ CstmzRsp_MRCC_ASC_Mode : 13|2@0+ (1,0) [0|0] ""  CGW
 SG_ CstmzRsp_Status_VRsp01 : 1|2@0+ (1,0) [0|0] ""  CGW
 SG_ CstmzRsp_Contents_VRsp01 : 3|2@0+ (1,0) [0|0] ""  CGW

BO_ 1168 ADU_Customize_Request_01: 32 CGW
 SG_ CstmzRq_RCD_ONOFF : 247|2@0+ (1,0) [0|0] ""  ADU
 SG_ CstmzRq_TAP_ALERT_ONOFF : 233|2@0+ (1,0) [0|0] ""  ADU
 SG_ CstmzRq_APS_RPC_DISTANCE : 235|2@0+ (1,0) [0|0] ""  ADU
 SG_ CstmzRq_PK_TrvB_EndP : 225|4@0+ (1,0) [0|0] ""  ADU
 SG_ CstmzRq_PK_TrvF_EndP : 229|4@0+ (1,0) [0|0] ""  ADU
 SG_ CstmzRq_PK_VehBLen : 217|4@0+ (1,0) [0|0] ""  ADU
 SG_ CstmzRq_PKout_View : 219|2@0+ (1,0) [0|0] ""  ADU
 SG_ CstmzRq_PKin_View : 221|2@0+ (1,0) [0|0] ""  ADU
 SG_ CstmzRq_PKout_PallalelDir : 223|2@0+ (1,0) [0|0] ""  ADU
 SG_ CstmzRq_PKout_CrossDir : 209|2@0+ (1,0) [0|0] ""  ADU
 SG_ CstmzRq_PK_Rd_Wid : 211|2@0+ (1,0) [0|0] ""  ADU
 SG_ CstmzRq_PK_Trv_Line : 215|4@0+ (1,0) [0|0] ""  ADU
 SG_ CstmzRq_PK_Veh_Dir : 201|2@0+ (1,0) [0|0] ""  ADU
 SG_ CstmzRq_APVSPD_LVL : 203|2@0+ (1,0) [0|0] ""  ADU
 SG_ CstmzRq_GUIDE_ONOFF : 205|2@0+ (1,0) [0|0] ""  ADU
 SG_ CstmzRq_RPC_ONOFF : 207|2@0+ (1,0) [0|0] ""  ADU
 SG_ CstmzRq_Contents_VRq04 : 195|2@0+ (1,0) [0|0] ""  ADU
 SG_ CstmzRq_ACC_GCR_ONOFF : 190|2@0+ (1,0) [0|0] ""  ADU
 SG_ CstmzRq_ACC_ACCL_Sens : 177|3@0+ (1,0) [0|0] ""  ADU
 SG_ CstmzRq_ACC_CURVE_Sens : 180|3@0+ (1,0) [0|0] ""  ADU
 SG_ CstmzRq_ACC_OVTK_ONOFF : 182|2@0+ (1,0) [0|0] ""  ADU
 SG_ CstmzRq_TMN_LV_Sens : 169|3@0+ (1,0) [0|0] ""  ADU
 SG_ CstmzRq_TMN_TS_Sens : 172|3@0+ (1,0) [0|0] ""  ADU
 SG_ CstmzRq_LCA_ONOFF : 162|2@0+ (1,0) [0|0] ""  ADU
 SG_ CstmzRq_HOF_REC_ONOFF : 164|2@0+ (1,0) [0|0] ""  ADU
 SG_ CstmzRq_HOF_ONOFF : 166|2@0+ (1,0) [0|0] ""  ADU
 SG_ CstmzRq_ESA_AES_ONOFF : 152|2@0+ (1,0) [0|0] ""  ADU
 SG_ CstmzRq_PDA_Sens : 155|3@0+ (1,0) [0|0] ""  ADU
 SG_ CstmzRq_PDA_ONOFF : 157|2@0+ (1,0) [0|0] ""  ADU
 SG_ CstmzRq_TVM_MOAAuto_ONOFF : 145|2@0+ (1,0) [0|0] ""  ADU
 SG_ CstmzRq_TVM_MOA_ONOFF : 147|2@0+ (1,0) [0|0] ""  ADU
 SG_ CstmzRq_TVM_AutoOFF_ONOFF : 149|2@0+ (1,0) [0|0] ""  ADU
 SG_ CstmzRq_TVM_PASRear_Sens : 139|2@0+ (1,0) [0|0] ""  ADU
 SG_ CstmzRq_TVM_PASFront_Sens : 141|2@0+ (1,0) [0|0] ""  ADU
 SG_ CstmzRq_TVM_PAS_ONOFF : 143|2@0+ (1,0) [0|0] ""  ADU
 SG_ CstmzRq_Contents_VRq03 : 131|2@0+ (1,0) [0|0] ""  ADU
 SG_ CstmzRq_Init_ALL_ADAS_Prsnl : 124|5@0+ (1,0) [0|0] ""  ADU
 SG_ CstmzRq_PAS_Vol : 119|3@0+ (1,0) [0|0] ""  ADU
 SG_ CstmzRq_PAS_ONOFF : 107|2@0+ (1,0) [0|0] ""  ADU
 SG_ CstmzRq_EDA_ONOFF : 109|2@0+ (1,0) [0|0] ""  ADU
 SG_ CstmzRq_EDA_Sleep_ONOFF : 111|2@0+ (1,0) [0|0] ""  ADU
 SG_ CstmzRq_DM_ONOFF : 97|2@0+ (1,0) [0|0] ""  ADU
 SG_ CstmzRq_OCP_ONOFF : 99|2@0+ (1,0) [0|0] ""  ADU
 SG_ CstmzRq_BSP_ONOFF : 101|2@0+ (1,0) [0|0] ""  ADU
 SG_ CstmzRq_RDP_ONOFF : 103|2@0+ (1,0) [0|0] ""  ADU
 SG_ CstmzRq_ELK_ONOFF : 89|2@0+ (1,0) [0|0] ""  ADU
 SG_ CstmzRq_RAEB_ONOFF : 95|2@0+ (1,0) [0|0] ""  ADU
 SG_ CstmzRq_HeadOn_ONOFF : 81|2@0+ (1,0) [0|0] ""  ADU
 SG_ CstmzRq_TAP_ONOFF : 83|2@0+ (1,0) [0|0] ""  ADU
 SG_ CstmzRq_CTB_ONOFF : 85|2@0+ (1,0) [0|0] ""  ADU
 SG_ CstmzRq_AEB_Vol : 87|2@0+ (1,0) [0|0] ""  ADU
 SG_ CstmzRq_FAEB_ONOFF : 73|2@0+ (1,0) [0|0] ""  ADU
 SG_ CstmzRq_LDP_ONOFF : 75|2@0+ (1,0) [0|0] ""  ADU
 SG_ CstmzRq_CBDA_Sens : 77|2@0+ (1,0) [0|0] ""  ADU
 SG_ CstmzRq_CBDA_ONOFF : 79|2@0+ (1,0) [0|0] ""  ADU
 SG_ CstmzRq_Contents_VRq02 : 67|2@0+ (1,0) [0|0] ""  ADU
 SG_ CstmzRq_Init_ALL_ADAS : 57|2@0+ (1,0) [0|0] ""  ADU
 SG_ CstmzRq_LDW_ELK_Warn : 49|3@0+ (1,0) [0|0] ""  ADU
 SG_ CstmzRq_BSM_Sens : 51|2@0+ (1,0) [0|0] ""  ADU
 SG_ CstmzRq_BSM_ONOFF : 54|3@0+ (1,0) [0|0] ""  ADU
 SG_ CstmzRq_LDW_ONOFF : 40|2@0+ (1,0) [0|0] ""  ADU
 SG_ CstmzRq_RCTA_ONOFF : 42|2@0+ (1,0) [0|0] ""  ADU
 SG_ CstmzRq_FCTA_Sens : 44|2@0+ (1,0) [0|0] ""  ADU
 SG_ CstmzRq_FCTA_ONOFF : 46|2@0+ (1,0) [0|0] ""  ADU
 SG_ CstmzRq_TSRWarnThres : 24|3@0+ (1,0) [0|0] ""  ADU
 SG_ CstmzRq_TSR_Warn : 26|2@0+ (1,0) [0|0] ""  ADU
 SG_ CstmzRq_TSR_Change : 28|2@0+ (1,0) [0|0] ""  ADU
 SG_ CstmzRq_TSR_NextInfo : 30|2@0+ (1,0) [0|0] ""  ADU
 SG_ CstmzRq_TSR_ONOFF : 16|2@0+ (1,0) [0|0] ""  ADU
 SG_ CstmzRq_ISA_TSR_ADJST : 21|5@0+ (1,0) [0|0] ""  ADU
 SG_ CstmzRq_IACC_TSR_ADJST : 10|5@0+ (1,0) [0|0] ""  ADU
 SG_ CstmzRq_MRCC_TSR_Mode : 12|2@0+ (1,0) [0|0] ""  ADU
 SG_ CstmzRq_MRCC_ASC_Mode : 14|2@0+ (1,0) [0|0] ""  ADU
 SG_ CstmzRq_Contents_VRq01 : 5|2@0+ (1,0) [0|0] ""  ADU

BO_ 1166 PrsnlSys_BCM_Status_Comm: 8 CGW
 SG_ Delete_KeyfobDpos_State : 50|2@0+ (1,0) [0|0] "" Vector__XXX
 SG_ Record_KeyfobDpos_State : 52|2@0+ (1,0) [0|0] "" Vector__XXX
 SG_ PrsnlDpos_StorageState : 53|1@0+ (1,0) [0|0] "" Vector__XXX
 SG_ KeyfobDpos_StorageState : 54|1@0+ (1,0) [0|0] "" Vector__XXX
 SG_ Mem2Dpos_StorageState : 55|1@0+ (1,0) [0|0] "" Vector__XXX
 SG_ Mem1Dpos_StorageState : 40|1@0+ (1,0) [0|0] "" Vector__XXX
 SG_ PrsnlSys_Switch_ID_ADU_Req : 41|1@0+ (1,0) [0|0] ""  ADU
 SG_ PrsnlSys_State3 : 45|4@0+ (1,0) [0|0] ""  ADU
 SG_ PrsnlSys_IDDB_State : 32|3@0+ (1,0) [0|0] "" Vector__XXX
 SG_ Recall_Dpos_State : 35|3@0+ (1,0) [0|0] "" Vector__XXX
 SG_ AutoDpos_State : 38|3@0+ (1,0) [0|0] "" Vector__XXX
 SG_ Key_Variants : 25|3@0+ (1,0) [0|0] ""  ADU
 SG_ PrsnlSys_Transition_Prohibit : 26|1@0+ (1,0) [0|0] "" Vector__XXX
 SG_ PrsnlSys_Switch_ID_CDC_Req : 27|1@0+ (1,0) [0|0] "" Vector__XXX
 SG_ PrsnlSys_ID_State : 31|4@0+ (1,0) [0|0] ""  ADU
 SG_ PrsnlSys_ID6_Regist_State : 18|3@0+ (1,0) [0|0] "" Vector__XXX
 SG_ PrsnlSys_ID5_Regist_State : 21|3@0+ (1,0) [0|0] "" Vector__XXX
 SG_ PrsnlSys_ID4_Regist_State : 8|3@0+ (1,0) [0|0] "" Vector__XXX
 SG_ PrsnlSys_ID3_Regist_State : 11|3@0+ (1,0) [0|0] "" Vector__XXX
 SG_ PrsnlSys_ID2_Regist_State : 14|3@0+ (1,0) [0|0] "" Vector__XXX
 SG_ PrsnlSys_ID1_Regist_State : 1|3@0+ (1,0) [0|0] "" Vector__XXX
 SG_ PrsnlSys_State2 : 4|3@0+ (1,0) [0|0] ""  ADU
 SG_ PrsnlSys_State1 : 7|3@0+ (1,0) [0|0] ""  ADU

BO_ 1157 BCM_Customize_Status_02: 32 CGW
 SG_ TotalISTime : 224|24@0+ (1,0) [0|16777215] "second" Vector__XXX
 SG_ Drv1IstpTm : 209|17@0+ (1,0) [0|131071] "second" Vector__XXX
 SG_ Set_Prsnl_DriverNo : 212|3@0+ (1,0) [0|0] "" Vector__XXX
 SG_ Set_Prsnl_Enable : 215|3@0+ (1,0) [0|0] "" Vector__XXX
 SG_ Set_TPMSUnit : 202|3@0+ (1,0) [0|0] "" Vector__XXX
 SG_ Set_FuelUnit : 205|3@0+ (1,0) [0|0] "" Vector__XXX
 SG_ Set_DistncUnit : 207|2@0+ (1,0) [0|0] ""  ADU
 SG_ Set_TempUnit : 193|2@0+ (1,0) [0|0] "" Vector__XXX
 SG_ Set_DispChrt : 199|6@0+ (1,0) [0|0] "" Vector__XXX

BO_ 1154 BCM_Customize_Status_01: 32 CGW
 SG_ CstmzStat_DimmerCancel : 177|2@0+ (1,0) [0|0] "" Vector__XXX
 SG_ CstmzStat_PanelBrightLevel : 181|4@0+ (1,0) [0|0] "" Vector__XXX
 SG_ CstmzStat_Facial_Iden_OnOff : 183|2@0+ (1,0) [0|0] ""  ADU
 SG_ CstmzStat_Towing_Wt : 170|3@0+ (1,0) [0|0] "" Vector__XXX
 SG_ CstmzStat_AirCon_Auto_AImode_CO2 : 172|2@0+ (1,0) [0|0] "" Vector__XXX
 SG_ CstmzStat_AirCon_Auto_AImode : 174|2@0+ (1,0) [0|0] "" Vector__XXX
 SG_ CstmzStat_AirCon_Auto_BlwLv : 160|2@0+ (1,0) [0|0] "" Vector__XXX
 SG_ CstmzStat_AC_Auto_wStrHeatLv : 162|2@0+ (1,0) [0|0] "" Vector__XXX
 SG_ CstmzStat_AC_Auto_wSeatVentLv_Ps : 164|2@0+ (1,0) [0|0] "" Vector__XXX
 SG_ CstmzStat_AC_Auto_wSeatHeatLv_Ps : 166|2@0+ (1,0) [0|0] "" Vector__XXX
 SG_ CstmzStat_AC_Auto_wSeatVentLv_Dr : 152|2@0+ (1,0) [0|0] "" Vector__XXX
 SG_ CstmzStat_AC_Auto_wSeatHeatLv_Dr : 154|2@0+ (1,0) [0|0] "" Vector__XXX
 SG_ CstmzStat_RSRmid_GUI_InandEx : 156|2@0+ (1,0) [0|0] "" Vector__XXX
 SG_ CstmzStat_RSRmid_GUI_In : 158|2@0+ (1,0) [0|0] "" Vector__XXX
 SG_ CstmzStat_RSRmid_GUI_Off : 144|2@0+ (1,0) [0|0] "" Vector__XXX
 SG_ CstmzStat_RSRmid : 146|2@0+ (1,0) [0|0] "" Vector__XXX
 SG_ CstmzStat_Regen_Select_Rq : 148|2@0+ (1,0) [0|0] "" Vector__XXX
 SG_ CstmzStat_Charge_TgtSoc_Rq : 136|4@0+ (1,0) [0|0] "" Vector__XXX
 SG_ CstmzStat_Ev_Default_Rq : 138|2@0+ (1,0) [0|0] "" Vector__XXX
 SG_ CstmzStat_FullSOC_AC : 142|4@0+ (1,0) [0|0] "" Vector__XXX
 SG_ CstmzStat_FullSOC_QBC : 130|4@0+ (1,0) [0|0] "" Vector__XXX
 SG_ CstmzStat_SupplyStopSOC : 134|4@0+ (1,0) [0|0] "" Vector__XXX
 SG_ CstmzStat_ConnectorLockReq : 120|2@0+ (1,0) [0|0] "" Vector__XXX
 SG_ CstmzStat_BatHeat_AutoSW : 122|2@0+ (1,0) [0|0] "" Vector__XXX
 SG_ CstmzStat_AirCon_Auto_wStrHeat : 124|2@0+ (1,0) [0|0] "" Vector__XXX
 SG_ CstmzStat_AirCon_Auto_wSeat_Ps : 126|2@0+ (1,0) [0|0] "" Vector__XXX
 SG_ CstmzStat_AirCon_Auto_wSeat_Dr : 112|2@0+ (1,0) [0|0] "" Vector__XXX
 SG_ CstmzStat_Prsnl_OnOff : 114|2@0+ (1,0) [0|0] "" Vector__XXX
 SG_ CstmzStat_CHG_W_FreqShiftOnOff : 116|2@0+ (1,0) [0|0] "" Vector__XXX
 SG_ CstmzStat_CHG_W_OnOff : 118|2@0+ (1,0) [0|0] "" Vector__XXX
 SG_ CstmzStat_Hud_RotatLvl : 107|5@0+ (1,0) [0|0] "" Vector__XXX
 SG_ CstmzStat_Hud_TiltLvl : 96|5@0+ (1,0) [0|0] "" Vector__XXX
 SG_ CstmzStat_Hud_OnOff : 98|2@0+ (1,0) [0|0] "" Vector__XXX
 SG_ CstmzStat_ALH_ONOFF_GUI_ON_w_M : 100|2@0+ (1,0) [0|0] "" Vector__XXX
 SG_ CstmzStat_Paddle_Mde : 103|3@0+ (1,0) [0|0] "" Vector__XXX
 SG_ CstmzStat_PLG_Handsfree_OnOff : 89|2@0+ (1,0) [0|0] "" Vector__XXX
 SG_ CstmzStat_PLG_Open_Keylock_Mde : 92|3@0+ (1,0) [0|0] "" Vector__XXX
 SG_ CstmzStat_FuelLckDelay_T : 95|3@0+ (1,0) [0|0] "" Vector__XXX
 SG_ CstmzStat_Ind_Clr_OnOff : 81|2@0+ (1,0) [0|0] "" Vector__XXX
 SG_ CstmzStat_Trip_Rst_Mde : 83|2@0+ (1,0) [0|0] "" Vector__XXX
 SG_ CstmzStat_PedalWarning : 85|2@0+ (1,0) [0|0] "" Vector__XXX
 SG_ CstmzStat_RidePos_Lvl : 87|2@0+ (1,0) [0|0] "" Vector__XXX
 SG_ CstmzStat_DrvPos_OnOff : 73|2@0+ (1,0) [0|0] "" Vector__XXX
 SG_ CstmzStat_Indrctillmntin_Lvl : 76|3@0+ (1,0) [0|0] "" Vector__XXX
 SG_ CstmzStat_RmLmpOffDrClose_T : 79|3@0+ (1,0) [0|0] "" Vector__XXX
 SG_ CstmzStat_LHL_OnOff : 65|2@0+ (1,0) [0|0] "" Vector__XXX
 SG_ CstmzStat_CHL_T : 68|3@0+ (1,0) [0|0] "" Vector__XXX
 SG_ CstmzStat_LightLeveling : 56|4@0+ (1,0) [0|0] "" Vector__XXX
 SG_ CstmzStat_AFS_ONOFF : 58|2@0+ (1,0) [0|0] "" Vector__XXX
 SG_ CstmzStat_HBC_ONOFF : 60|2@0+ (1,0) [0|0] "" Vector__XXX
 SG_ CstmzStat_ALH_ONOFF : 62|2@0+ (1,0) [0|0] "" Vector__XXX
 SG_ CstmzStat_DRL_OnOff : 48|2@0+ (1,0) [0|0] "" Vector__XXX
 SG_ CstmzStat_AtLtOff_T : 51|3@0+ (1,0) [0|0] "" Vector__XXX
 SG_ CstmzStat_AutoLight_Sens : 54|3@0+ (1,0) [0|0] "" Vector__XXX
 SG_ CstmzStat_AB_R_OnOff : 40|2@0+ (1,0) [0|0] "" Vector__XXX
 SG_ CstmzStat_AB_P_OnOff : 42|2@0+ (1,0) [0|0] "" Vector__XXX
 SG_ CstmzStat_AirCon_Cooperation : 44|2@0+ (1,0) [0|0] "" Vector__XXX
 SG_ CstmzStat_RearDef_T : 46|2@0+ (1,0) [0|0] "" Vector__XXX
 SG_ CstmzStat_SmtTrn_OnOff : 32|2@0+ (1,0) [0|0] "" Vector__XXX
 SG_ CstmzStat_AtStorageMirror_OnOff : 34|2@0+ (1,0) [0|0] "" Vector__XXX
 SG_ CstmzStat_AtWpr_OnOff : 36|2@0+ (1,0) [0|0] "" Vector__XXX
 SG_ CstmzStat_KylssChm_Vol : 39|3@0+ (1,0) [0|0] "" Vector__XXX
 SG_ CstmzStat_KylssWal_OnOff : 25|2@0+ (1,0) [0|0] "" Vector__XXX
 SG_ CstmzStat_KylssUnlck_Mde : 27|2@0+ (1,0) [0|0] "" Vector__XXX
 SG_ CstmzStat_KylssAtLck_T : 29|2@0+ (1,0) [0|0] "" Vector__XXX
 SG_ CstmzStat_AtDrLck_Mde_MT : 31|2@0+ (1,0) [0|0] "" Vector__XXX
 SG_ CstmzStat_AtDrLck_Mde_AT : 18|3@0+ (1,0) [0|0] "" Vector__XXX
 SG_ CstmzStat_Prsnl_DriverNo : 21|3@0+ (1,0) [0|0] "" Vector__XXX
 SG_ CstmzStat_Prsnl_Enable : 23|2@0+ (1,0) [0|0] "" Vector__XXX
 SG_ CstmzStat_TPMSUnit : 10|3@0+ (1,0) [0|0] "" Vector__XXX
 SG_ CstmzStat_FuelUnit : 13|3@0+ (1,0) [0|0] "" Vector__XXX
 SG_ CstmzStat_DistncUnit : 15|2@0+ (1,0) [0|0] "" Vector__XXX
 SG_ CstmzStat_TempUnit : 1|2@0+ (1,0) [0|0] "" Vector__XXX
 SG_ CstmzStat_DispChrt : 7|6@0+ (1,0) [0|0] "" Vector__XXX

BO_ 1148 IPA1S05: 8 ADU
 SG_ ID47C_No_Cs : 63|8@0+ (1,0) [0|255] ""  CGW
 SG_ ID47C_No_Cnt : 55|4@0+ (1,0) [0|15] "counter"  CGW
 SG_ NEMIN_AP : 43|4@0+ (50,400) [400|1150] "rpm"  CGW
 SG_ APPME : 47|4@0+ (1,0) [0|15] ""  CGW
 SG_ IPAVOICE : 37|6@0+ (1,0) [0|0] ""  CGW
 SG_ APWNKON : 39|2@0+ (1,0) [0|3] ""  CGW
 SG_ AP_HRNRQ : 24|1@0+ (1,0) [0|1] ""  CGW
 SG_ VNUSGAPP : 25|1@0+ (1,0) [0|1] ""  CGW
 SG_ IPAV_EXT : 26|1@0+ (1,0) [0|1] ""  CGW
 SG_ IPAVSYNC : 27|1@0+ (1,0) [0|1] ""  CGW
 SG_ IPAR_EXT : 28|1@0+ (1,0) [0|0] ""  CGW
 SG_ IPARSYNC : 29|1@0+ (1,0) [0|1] ""  CGW
 SG_ IPAINFO2 : 15|8@0+ (1,0) [0|255] ""  CGW
 SG_ IPA_DIST : 3|4@0+ (1,0) [0|15] ""  CGW
 SG_ CAREQ_AP : 4|1@0+ (1,0) [0|1] ""  CGW
 SG_ IPA_BZ2 : 7|3@0+ (1,0) [0|7] ""  CGW

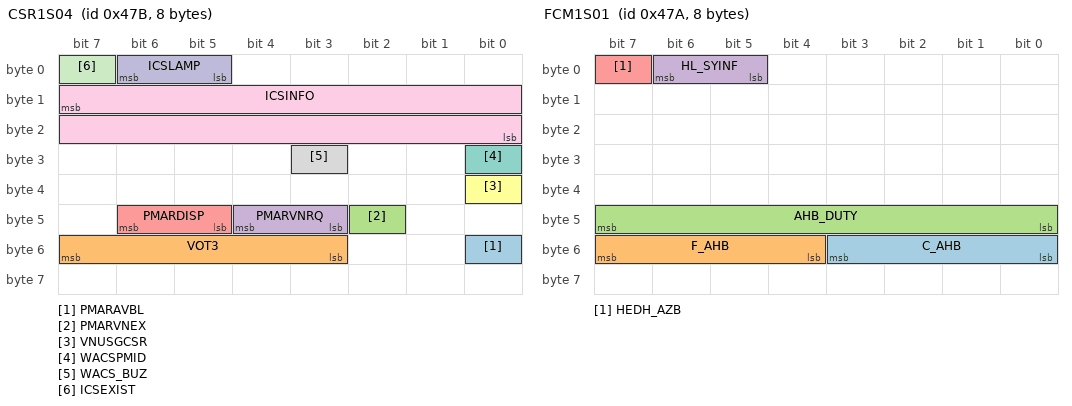
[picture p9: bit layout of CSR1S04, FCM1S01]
BO_ 1147 CSR1S04: 8 ADU
 SG_ PMARAVBL : 48|1@0+ (1,0) [0|1] ""  CGW
 SG_ VOT3 : 55|5@0+ (1,0) [0|31] ""  CGW
 SG_ PMARVNEX : 42|1@0+ (1,0) [0|1] ""  CGW
 SG_ PMARVNRQ : 44|2@0+ (1,0) [0|3] ""  CGW
 SG_ PMARDISP : 46|2@0+ (1,0) [0|3] ""  CGW
 SG_ VNUSGCSR : 32|1@0+ (1,0) [0|1] ""  CGW
 SG_ WACSPMID : 24|1@0+ (1,0) [0|1] ""  CGW
 SG_ WACS_BUZ : 27|1@0+ (1,0) [0|1] ""  CGW
 SG_ ICSINFO : 15|16@0+ (1,0) [0|65535] ""  CGW
 SG_ ICSLAMP : 6|2@0+ (1,0) [0|3] ""  CGW
 SG_ ICSEXIST : 7|1@0+ (1,0) [0|1] ""  CGW

BO_ 1146 FCM1S01: 8 ADU
 SG_ C_AHB : 51|4@0+ (1,0) [0|15] ""  CGW
 SG_ F_AHB : 55|4@0+ (1,0) [0|15] ""  CGW
 SG_ AHB_DUTY : 47|8@0+ (0.5,0) [0|127.5] "%"  CGW
 SG_ HL_SYINF : 6|2@0+ (1,0) [0|3] ""  CGW
 SG_ HEDH_AZB : 7|1@0+ (1,0) [0|1] ""  CGW

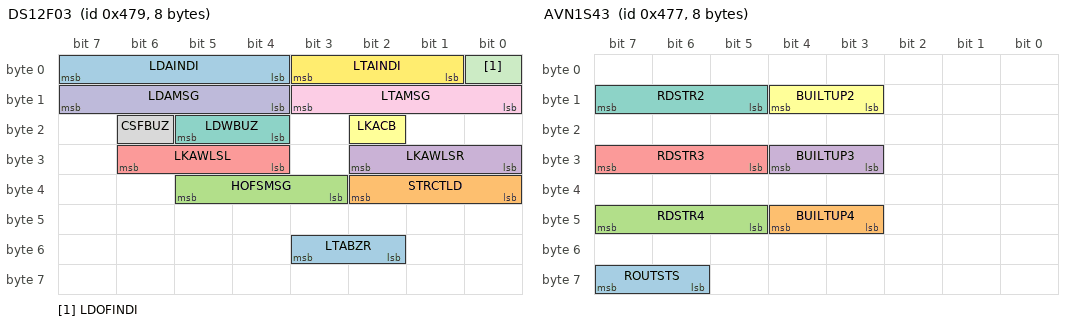
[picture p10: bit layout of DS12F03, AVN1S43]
BO_ 1145 DS12F03: 8 ADU
 SG_ LTABZR : 51|2@0+ (1,0) [0|3] ""  CGW
 SG_ STRCTLD : 34|3@0+ (1,0) [0|7] ""  CGW
 SG_ HOFSMSG : 37|3@0+ (1,0) [0|7] ""  CGW
 SG_ LKAWLSR : 26|3@0+ (1,0) [0|7] ""  CGW
 SG_ LKAWLSL : 30|3@0+ (1,0) [0|7] ""  CGW
 SG_ LKACB : 18|1@0+ (1,0) [0|1] ""  CGW
 SG_ LDWBUZ : 21|2@0+ (1,0) [0|3] ""  CGW
 SG_ CSFBUZ : 22|1@0+ (1,0) [0|1] ""  CGW
 SG_ LTAMSG : 11|4@0+ (1,0) [0|15] ""  CGW
 SG_ LDAMSG : 15|4@0+ (1,0) [0|15] ""  CGW
 SG_ LDOFINDI : 0|1@0+ (1,0) [0|1] ""  CGW
 SG_ LTAINDI : 3|3@0+ (1,0) [0|7] ""  CGW
 SG_ LDAINDI : 7|4@0+ (1,0) [0|15] ""  CGW

BO_ 1144 DS12F02: 8 ADU
 SG_ PCSSWM : 56|1@0+ (1,0) [0|1] ""  CGW
 SG_ PCSRTWM : 58|2@0+ (1,0) [0|3] ""  CGW
 SG_ PCSBDM : 59|1@0+ (1,0) [0|1] ""  CGW
 SG_ FSSINFO : 62|3@0+ (1,0) [0|7] ""  CGW
 SG_ PCSPWUCT : 63|1@0+ (1,0) [0|1] ""  CGW
 SG_ PCSCAUST : 48|1@0+ (1,0) [0|1] ""  CGW
 SG_ TSS_TS : 49|1@0+ (1,0) [0|1] ""  CGW
 SG_ PCSTUNA2 : 50|1@0+ (1,0) [0|1] ""  CGW
 SG_ PCSDUST2 : 41|1@0+ (1,0) [0|1] ""  CGW
 SG_ PCTEMP2 : 42|1@0+ (1,0) [0|1] ""  CGW
 SG_ PCSLCCK : 33|2@0+ (1,0) [0|3] ""  CGW
 SG_ PCSDUST : 34|1@0+ (1,0) [0|1] ""  CGW
 SG_ PCSTEMP : 35|1@0+ (1,0) [0|1] ""  CGW
 SG_ PCSDSRF : 36|1@0+ (1,0) [0|1] ""  CGW
 SG_ PCSDW : 39|3@0+ (1,0) [0|7] ""  CGW
 SG_ PCSMTBZ2 : 27|4@0+ (1,0) [0|15] ""  CGW
 SG_ PCSWD : 9|2@0+ (1,0) [0|3] ""  CGW
 SG_ PCSWDUCT : 11|1@0+ (1,0) [0|1] ""  CGW
 SG_ PCSTUNA : 12|1@0+ (1,0) [0|1] ""  CGW
 SG_ PBTUCT : 14|1@0+ (1,0) [0|1] ""  CGW
 SG_ DS1LCCK : 1|2@0+ (1,0) [0|3] ""  CGW
 SG_ PCSTUCT : 2|1@0+ (1,0) [0|1] ""  CGW
 SG_ PCSFCT : 3|1@0+ (1,0) [0|1] ""  CGW
 SG_ PCSWM : 5|2@0+ (1,0) [0|3] ""  CGW
 SG_ PCSINDI : 7|2@0+ (1,0) [0|3] ""  CGW

BO_ 1143 AVN1S43: 8 CGW
 SG_ ROUTSTS : 63|2@0+ (1,0) [0|3] ""  ADU
 SG_ BUILTUP4 : 44|2@0+ (1,0) [0|3] ""  ADU
 SG_ RDSTR4 : 47|3@0+ (1,0) [0|7] ""  ADU
 SG_ BUILTUP3 : 28|2@0+ (1,0) [0|3] ""  ADU
 SG_ RDSTR3 : 31|3@0+ (1,0) [0|7] ""  ADU
 SG_ BUILTUP2 : 12|2@0+ (1,0) [0|3] ""  ADU
 SG_ RDSTR2 : 15|3@0+ (1,0) [0|7] ""  ADU

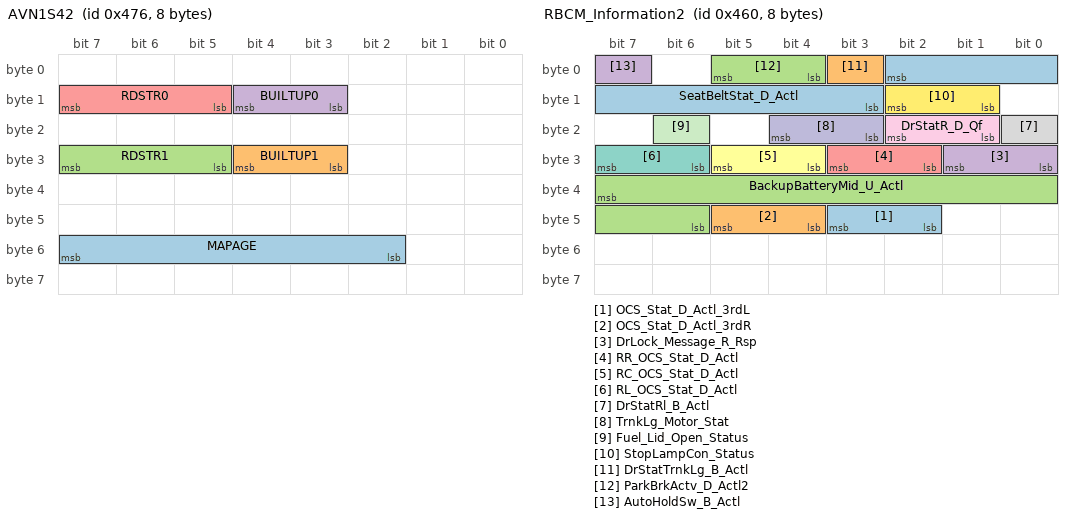
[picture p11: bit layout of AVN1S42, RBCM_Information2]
BO_ 1142 AVN1S42: 8 CGW
 SG_ MAPAGE : 55|6@0+ (1,2000) [2000|2063] "Year"  ADU
 SG_ BUILTUP1 : 28|2@0+ (1,0) [0|3] ""  ADU
 SG_ RDSTR1 : 31|3@0+ (1,0) [0|7] ""  ADU
 SG_ BUILTUP0 : 12|2@0+ (1,0) [0|3] ""  ADU
 SG_ RDSTR0 : 15|3@0+ (1,0) [0|7] ""  ADU

BO_ 1130 TSR_Market_Data5: 32 ADU
 SG_ Spd_Cntrl_on_time : 71|32@0+ (1,0) [0|4294967295] "sec"  CGW
 SG_ Spd_Cntrl_onoff_cnt : 30|16@0+ (1,0) [0|65535] "cnt"  CGW
 SG_ Spd_Cntrl_Warn_dist : 7|25@0+ (0.02,0) [0|671088.62] "km"  CGW

BO_ 1129 TSR_Market_Data1: 32 ADU
 SG_ Over_Ride_dist : 222|25@0+ (0.02,0) [0|671088.62] "km"  CGW
 SG_ Spd_Cntrl_off_dist : 199|25@0+ (0.02,0) [0|671088.62] "km"  CGW
 SG_ TSR_Total_IGON_time : 167|32@0+ (1,0) [0|4294967295] "sec"  CGW
 SG_ Sound_Warn_on_time : 135|32@0+ (1,0) [0|4294967295] "sec"  CGW
 SG_ Sound_Warn_onoff_cnt : 94|16@0+ (1,0) [0|65535] "cnt"  CGW
 SG_ Sound_Warn_dist : 71|25@0+ (0.02,0) [0|671088.62] "km"  CGW
 SG_ Disp_Warn_dist : 30|25@0+ (0.02,0) [0|671088.62] "km"  CGW
 SG_ Sound_Warn_off_dist : 7|25@0+ (0.02,0) [0|671088.62] "km"  CGW

BO_ 1125 LocateTime_Info: 8 CGW
 SG_ GMT_Second_ByGPS m3 : 55|8@0+ (1,0) [0|60] "Second"  ADU
 SG_ GMT_Minutes_ByGPS m3 : 47|8@0+ (1,0) [0|60] "Minute"  ADU
 SG_ GMT_Hour_ByGPS m3 : 39|8@0+ (1,0) [0|24] "Hour"  ADU
 SG_ GMT_Date_ByGPS m3 : 31|8@0+ (1,0) [1|31] "day"  ADU
 SG_ GMT_Month_ByGPS m3 : 23|8@0+ (1,0) [1|12] "month"  ADU
 SG_ GMT_Year_ByGPS m3 : 15|8@0+ (1,2018) [2018|2272] "year"  ADU
 SG_ HorizonByGPS m2 : 15|32@0+ (0.01,-10000) [-10000|10000] "meter"  ADU
 SG_ Curnt_Second_ByGPS m1 : 63|8@0+ (1,0) [0|60] "Second"  ADU
 SG_ Curnt_Minutes_ByGPS m1 : 55|8@0+ (1,0) [0|60] "Minute"  ADU
 SG_ Curnt_Hour_ByGPS m1 : 47|8@0+ (1,0) [0|24] "Hour"  ADU
 SG_ LongitudeByGPS m1 : 15|32@0+ (0.0000001,-180) [-180|180] "degree"  ADU
 SG_ Curnt_Date_ByGPS m0 : 63|8@0+ (1,0) [1|31] "day"  ADU
 SG_ Curnt_Month_ByGPS m0 : 55|8@0+ (1,0) [1|12] "month"  ADU
 SG_ Curnt_Year_ByGPS m0 : 47|8@0+ (1,2018) [2018|2272] "year"  ADU
 SG_ LatitudeByGPS m0 : 15|32@0+ (0.0000001,-90) [-90|90] "degree"  ADU
 SG_ LocateTime_Info_Data_Number M : 7|8@0+ (1,0) [0|0] ""  ADU

BO_ 1120 RBCM_Information2: 8 CGW
 SG_ OCS_Stat_D_Actl_3rdL : 43|2@0+ (1,0) [0|0] "" Vector__XXX
 SG_ OCS_Stat_D_Actl_3rdR : 45|2@0+ (1,0) [0|0] "" Vector__XXX
 SG_ BackupBatteryMid_U_Actl : 39|10@0+ (0.02,0) [0|20.44] "V" Vector__XXX
 SG_ DrLock_Message_R_Rsp : 25|2@0+ (1,0) [0|0] "" Vector__XXX
 SG_ RR_OCS_Stat_D_Actl : 27|2@0+ (1,0) [0|0] "" Vector__XXX
 SG_ RC_OCS_Stat_D_Actl : 29|2@0+ (1,0) [0|0] "" Vector__XXX
 SG_ RL_OCS_Stat_D_Actl : 31|2@0+ (1,0) [0|0] "" Vector__XXX
 SG_ DrStatRl_B_Actl : 16|1@0+ (1,0) [0|0] ""  ADU
 SG_ DrStatR_D_Qf : 18|2@0+ (1,0) [0|0] ""  ADU
 SG_ TrnkLg_Motor_Stat : 20|2@0+ (1,0) [0|0] "" Vector__XXX
 SG_ Fuel_Lid_Open_Status : 22|1@0+ (1,0) [0|0] "" Vector__XXX
 SG_ StopLampCon_Status : 10|2@0+ (1,0) [0|0] ""  ADU
 SG_ SeatBeltStat_D_Actl : 2|8@0+ (1,0) [0|255] "" Vector__XXX
 SG_ DrStatTrnkLg_B_Actl : 3|1@0+ (1,0) [0|0] ""  ADU
 SG_ ParkBrkActv_D_Actl2 : 5|2@0+ (1,0) [0|0] ""  ADU
 SG_ AutoHoldSw_B_Actl : 7|1@0+ (1,0) [0|0] "" Vector__XXX

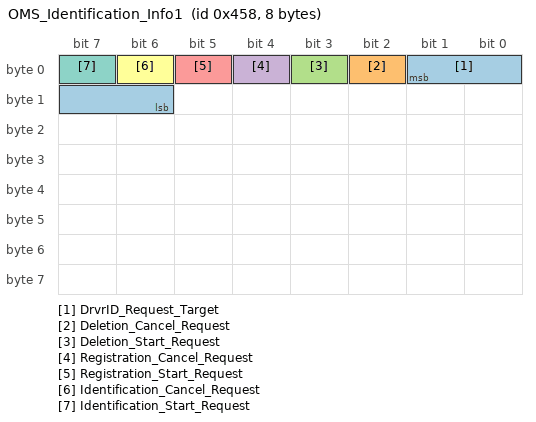
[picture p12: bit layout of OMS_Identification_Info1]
BO_ 1112 OMS_Identification_Info1: 8 CGW
 SG_ DrvrID_Request_Target : 1|4@0+ (1,0) [0|0] ""  ADU
 SG_ Deletion_Cancel_Request : 2|1@0+ (1,0) [0|0] ""  ADU
 SG_ Deletion_Start_Request : 3|1@0+ (1,0) [0|0] ""  ADU
 SG_ Registration_Cancel_Request : 4|1@0+ (1,0) [0|0] ""  ADU
 SG_ Registration_Start_Request : 5|1@0+ (1,0) [0|0] ""  ADU
 SG_ Identification_Cancel_Request : 6|1@0+ (1,0) [0|0] ""  ADU
 SG_ Identification_Start_Request : 7|1@0+ (1,0) [0|0] ""  ADU

BO_ 1109 ADU_HMI_Information_8: 32 ADU
 SG_ VCU_rear : 119|6@0+ (1,0) [0|0] ""  CGW
 SG_ VCU_rearside : 109|6@0+ (1,0) [0|0] ""  CGW
 SG_ VCU_side : 99|6@0+ (1,0) [0|0] ""  CGW
 SG_ VCU_frontside : 89|6@0+ (1,0) [0|0] ""  CGW
 SG_ VCU_front : 95|6@0+ (1,0) [0|0] ""  CGW
 SG_ VCU_state : 85|6@0+ (1,0) [0|0] ""  CGW
 SG_ VCU_mute_State : 77|4@0+ (1,0) [0|0] ""  CGW
 SG_ DAS_state : 65|4@0+ (1,0) [0|0] ""  CGW
 SG_ OMC_Sensing_State : 71|4@0+ (1,0) [0|0] ""  CGW
 SG_ OMC_state : 59|4@0+ (1,0) [0|0] ""  CGW
 SG_ AMAP_state : 63|4@0+ (1,0) [0|0] ""  CGW
 SG_ V2X_state : 51|4@0+ (1,0) [0|0] ""  CGW
 SG_ VMC4_state : 52|1@0+ (1,0) [0|0] ""  CGW
 SG_ VMC3_state : 53|1@0+ (1,0) [0|0] ""  CGW
 SG_ VMC2_state : 54|1@0+ (1,0) [0|0] ""  CGW
 SG_ VMC1_state : 55|1@0+ (1,0) [0|0] ""  CGW
 SG_ VMC_state : 43|4@0+ (1,0) [0|0] ""  CGW
 SG_ SONAR_state12 : 46|1@0+ (1,0) [0|0] ""  CGW
 SG_ SONAR_state11 : 47|1@0+ (1,0) [0|0] ""  CGW
 SG_ SONAR_state10 : 32|1@0+ (1,0) [0|0] ""  CGW
 SG_ SONAR_state9 : 33|1@0+ (1,0) [0|0] ""  CGW
 SG_ SONAR_state8 : 34|1@0+ (1,0) [0|0] ""  CGW
 SG_ SONAR_state7 : 35|1@0+ (1,0) [0|0] ""  CGW
 SG_ SONAR_state6 : 36|1@0+ (1,0) [0|0] ""  CGW
 SG_ SONAR_state5 : 37|1@0+ (1,0) [0|0] ""  CGW
 SG_ SONAR_state4 : 38|1@0+ (1,0) [0|0] ""  CGW
 SG_ SONAR_state3 : 39|1@0+ (1,0) [0|0] ""  CGW
 SG_ SONAR_state2 : 24|1@0+ (1,0) [0|0] ""  CGW
 SG_ SONAR_state1 : 25|1@0+ (1,0) [0|0] ""  CGW
 SG_ SONAR_state : 29|4@0+ (1,0) [0|0] ""  CGW
 SG_ RSRDR_state : 19|4@0+ (1,0) [0|0] ""  CGW
 SG_ FSRDR_state : 23|4@0+ (1,0) [0|0] ""  CGW
 SG_ FRDR_state : 11|4@0+ (1,0) [0|0] ""  CGW
 SG_ FSC_state : 1|4@0+ (1,0) [0|0] ""  CGW
 SG_ REDKEY_state : 7|4@0+ (1,0) [0|0] ""  CGW

BO_ 1108 ADU_HMI_Information_7N: 32 ADU
 SG_ LKA_handsfree : 254|5@0+ (1,0) [0|0] ""  CGW
 SG_ RMF_CMU_disp_select : 242|4@0+ (1,0) [0|0] ""  CGW
 SG_ EDA_cancel_timer : 247|5@0+ (1,0) [0|0] ""  CGW
 SG_ LKA_EV_RMF_cancel : 232|1@0+ (1,0) [0|0] ""  CGW
 SG_ EDA_EV_cancel : 233|1@0+ (1,0) [0|0] ""  CGW
 SG_ EDA_state : 238|5@0+ (1,0) [0|0] ""  CGW
 SG_ TVM_state : 218|4@0+ (1,0) [0|0] ""  CGW
 SG_ APS_RPC_state : 222|4@0+ (1,0) [0|0] ""  CGW
 SG_ HBC_high : 204|2@0+ (1,0) [0|0] ""  CGW
 SG_ HBC_state : 192|4@0+ (1,0) [0|0] ""  CGW
 SG_ ALH_high : 189|2@0+ (1,0) [0|0] ""  CGW
 SG_ ALH_state : 177|4@0+ (1,0) [0|0] ""  CGW
 SG_ DAA_state : 181|4@0+ (1,0) [0|0] ""  CGW
 SG_ DM_EV_time_intrvl_drowsy : 162|1@0+ (1,0) [0|0] ""  CGW
 SG_ DM_EV_engage_awake : 163|1@0+ (1,0) [0|0] ""  CGW
 SG_ DM_state : 167|4@0+ (1,0) [0|0] ""  CGW
 SG_ PAOBJ_BSM_rear_R_side_rel : 143|8@0+ (1,0) [0|255] "Unitless"  CGW
 SG_ PAOBJ_BSM_rear_R_side_Y : 135|8@0+ (0.2,-12.6) [-12.6|12.6] "Unitless"  CGW
 SG_ PAOBJ_BSM_rear_R_side_X : 127|8@0+ (1,0) [0|255] "Unitless"  CGW
 SG_ PAOBJ_BSM_R_side_rel : 103|8@0+ (1,0) [0|255] "Unitless"  CGW
 SG_ PAOBJ_BSM_R_side_Y : 95|8@0+ (0.2,-12.6) [-12.6|12.6] "Unitless"  CGW
 SG_ PAOBJ_BSM_R_side_X : 87|8@0+ (1,0) [0|255] "Unitless"  CGW
 SG_ PAOBJ_BSM_rear_L_side_rel : 63|8@0+ (1,0) [0|255] "Unitless"  CGW
 SG_ PAOBJ_BSM_rear_L_side_Y : 55|8@0+ (0.2,-12.6) [-12.6|12.6] "Unitless"  CGW
 SG_ PAOBJ_BSM_rear_L_side_X : 47|8@0+ (1,0) [0|255] "Unitless"  CGW
 SG_ PAOBJ_BSM_L_side_rel : 23|8@0+ (1,0) [0|255] "Unitless"  CGW
 SG_ PAOBJ_BSM_L_side_Y : 15|8@0+ (0.2,-12.6) [-12.6|12.6] "Unitless"  CGW
 SG_ PAOBJ_BSM_L_side_X : 7|8@0+ (1,0) [0|255] "Unitless"  CGW

BO_ 1107 ADU_HMI_Information_7J: 32 ADU
 SG_ PAOBJ_LCA_rear_R_side_rel : 229|8@0+ (1,0) [0|255] "Unitless"  CGW
 SG_ PAOBJ_LCA_rear_R_side_Y : 221|8@0+ (0.2,-12.6) [-12.6|12.6] "Unitless"  CGW
 SG_ PAOBJ_LCA_rear_R_side_X : 213|8@0+ (1,0) [0|255] "Unitless"  CGW
 SG_ PAOBJ_LCA_R_side_rel : 191|8@0+ (1,0) [0|255] "Unitless"  CGW
 SG_ PAOBJ_LCA_R_side_Y : 183|8@0+ (0.2,-12.6) [-12.6|12.6] "Unitless"  CGW
 SG_ PAOBJ_LCA_R_side_X : 175|8@0+ (1,0) [0|255] "Unitless"  CGW
 SG_ PAOBJ_LCA_rear_L_side_rel : 137|8@0+ (1,0) [0|255] "Unitless"  CGW
 SG_ PAOBJ_LCA_rear_L_side_Y : 129|8@0+ (0.2,-12.6) [-12.6|12.6] "Unitless"  CGW
 SG_ PAOBJ_LCA_rear_L_side_X : 121|8@0+ (1,0) [0|255] "Unitless"  CGW
 SG_ PAOBJ_LCA_L_side_rel : 99|8@0+ (1,0) [0|255] "Unitless"  CGW
 SG_ PAOBJ_LCA_L_side_Y : 91|8@0+ (0.2,-12.6) [-12.6|12.6] "Unitless"  CGW
 SG_ PAOBJ_LCA_L_side_X : 83|8@0+ (1,0) [0|255] "Unitless"  CGW
 SG_ PAOBJ_LCA_rear_rel : 61|8@0+ (1,0) [0|255] "Unitless"  CGW
 SG_ PAOBJ_LCA_rear_Y : 53|8@0+ (0.2,-12.6) [-12.6|12.6] "Unitless"  CGW
 SG_ PAOBJ_LCA_rear_X : 45|8@0+ (1,0) [0|255] "Unitless"  CGW
 SG_ PAOBJ_LCA_front_rel : 23|8@0+ (1,0) [0|255] "Unitless"  CGW
 SG_ PAOBJ_LCA_front_Y : 15|8@0+ (0.2,-12.6) [-12.6|12.6] "Unitless"  CGW
 SG_ PAOBJ_LCA_front_X : 7|8@0+ (1,0) [0|255] "Unitless"  CGW

BO_ 1106 ADU_HMI_Information_7F: 32 ADU
 SG_ PALNMID2 : 243|2@0+ (1,0) [0|0] ""  CGW
 SG_ PALDAL : 244|1@0+ (1,0) [0|0] ""  CGW
 SG_ PALNTYL : 246|2@0+ (1,0) [0|0] ""  CGW
 SG_ PALN2Y7 : 237|7@0+ (0.2,-12.6) [-12.6|12.6] "Unitless"  CGW
 SG_ PALN2Y6 : 228|7@0+ (0.2,-12.6) [-12.6|12.6] "Unitless"  CGW
 SG_ PALN2Y5 : 219|7@0+ (0.2,-12.6) [-12.6|12.6] "Unitless"  CGW
 SG_ PALN2Y4 : 210|7@0+ (0.2,-12.6) [-12.6|12.6] "Unitless"  CGW
 SG_ PALN2Y3 : 201|7@0+ (0.2,-12.6) [-12.6|12.6] "Unitless"  CGW
 SG_ PALN2Y2 : 192|7@0+ (0.2,-12.6) [-12.6|12.6] "Unitless"  CGW
 SG_ PALN2Y1 : 199|7@0+ (0.2,-12.6) [-12.6|12.6] "Unitless"  CGW
 SG_ PALNMID1 : 179|2@0+ (1,0) [0|0] ""  CGW
 SG_ PALDAR : 180|1@0+ (1,0) [0|0] ""  CGW
 SG_ PALNTYR : 182|2@0+ (1,0) [0|0] ""  CGW
 SG_ PALN1Y7 : 173|7@0+ (0.2,-12.6) [-12.6|12.6] "Unitless"  CGW
 SG_ PALN1Y6 : 164|7@0+ (0.2,-12.6) [-12.6|12.6] "Unitless"  CGW
 SG_ PALN1Y5 : 155|7@0+ (0.2,-12.6) [-12.6|12.6] "Unitless"  CGW
 SG_ PALN1Y4 : 146|7@0+ (0.2,-12.6) [-12.6|12.6] "Unitless"  CGW
 SG_ PALN1Y3 : 137|7@0+ (0.2,-12.6) [-12.6|12.6] "Unitless"  CGW
 SG_ PALN1Y2 : 128|7@0+ (0.2,-12.6) [-12.6|12.6] "Unitless"  CGW
 SG_ PALN1Y1 : 135|7@0+ (0.2,-12.6) [-12.6|12.6] "Unitless"  CGW
 SG_ PALDAY : 110|6@0+ (0.2,-6.2) [-6.2|6.2] "Unitless"  CGW
 SG_ PALNMKST : 96|2@0+ (1,0) [0|0] ""  CGW
 SG_ PATGTST : 99|3@0+ (1,0) [0|0] ""  CGW
 SG_ PATGTYA : 88|5@0+ (1,-15) [-15|15] "Unitless"  CGW
 SG_ PATGTY : 95|7@0+ (0.2,-12.6) [-12.6|12.6] "Unitless"  CGW
 SG_ PATGTX : 86|7@0+ (1,-20) [-20|107] "Unitless"  CGW
 SG_ PATRJY : 77|7@0+ (0.2,-12.6) [-12.6|12.6] "Unitless"  CGW
 SG_ PATRJX : 68|7@0+ (1,-20) [-20|107] "Unitless"  CGW
 SG_ PATRJSPD : 71|3@0+ (1,0) [0|0] ""  CGW
 SG_ PARSRCGR : 53|1@0+ (1,0) [0|0] ""  CGW
 SG_ PARSRCGL : 54|1@0+ (1,0) [0|0] ""  CGW
 SG_ PAVLOST : 40|2@0+ (1,0) [0|0] ""  CGW
 SG_ PAMODE : 42|2@0+ (1,0) [0|0] ""  CGW
 SG_ PARDSTL : 43|1@0+ (1,0) [0|0] ""  CGW
 SG_ PARDSTR : 44|1@0+ (1,0) [0|0] ""  CGW
 SG_ PAALNTYL : 46|2@0+ (1,0) [0|0] ""  CGW
 SG_ PAALNTYR : 32|2@0+ (1,0) [0|0] ""  CGW
 SG_ PAAMBST : 17|3@0+ (1,0) [0|0] ""  CGW
 SG_ PALCY3 : 23|6@0+ (0.2,-6.2) [-6.2|6.2] ""  CGW
 SG_ PALCY2 : 13|6@0+ (0.2,-6.2) [-6.2|6.2] ""  CGW
 SG_ PALCY1 : 3|6@0+ (0.2,-6.2) [-6.2|6.2] ""  CGW
 SG_ PALCTRJ : 4|1@0+ (1,0) [0|0] ""  CGW
 SG_ PALCSP : 5|1@0+ (1,0) [0|0] ""  CGW
 SG_ PABSML : 6|1@0+ (1,0) [0|0] ""  CGW
 SG_ PABSMR : 7|1@0+ (1,0) [0|0] ""  CGW

BO_ 1105 ADU_HMI_Information_7B: 32 ADU
 SG_ PAOBJST6 : 240|3@0+ (1,0) [0|0] ""  CGW
 SG_ PAOBJTY6 : 243|3@0+ (1,0) [0|0] ""  CGW
 SG_ PAOBJYA6 : 232|5@0+ (1,-15) [-15|15] "Unitless"  CGW
 SG_ PAOBJY6 : 239|7@0+ (0.2,-12.6) [-12.6|12.6] "Unitless"  CGW
 SG_ PAOBJX6 : 230|7@0+ (1,-20) [-20|107] "Unitless"  CGW
 SG_ PAOBJID6 : 208|10@0+ (1,0) [0|1023] "Unitless"  CGW
 SG_ PAOBJST5 : 203|3@0+ (1,0) [0|0] ""  CGW
 SG_ PAOBJTY5 : 206|3@0+ (1,0) [0|0] ""  CGW
 SG_ PAOBJYA5 : 195|5@0+ (1,-15) [-15|15] "Unitless"  CGW
 SG_ PAOBJY5 : 186|7@0+ (0.2,-12.6) [-12.6|12.6] "Unitless"  CGW
 SG_ PAOBJX5 : 177|7@0+ (1,-20) [-20|107] "Unitless"  CGW
 SG_ PAOBJID5 : 171|10@0+ (1,0) [0|1023] "Unitless"  CGW
 SG_ PAOBJST4 : 166|3@0+ (1,0) [0|0] ""  CGW
 SG_ PAOBJTY4 : 153|3@0+ (1,0) [0|0] ""  CGW
 SG_ PAOBJYA4 : 158|5@0+ (1,-15) [-15|15] "Unitless"  CGW
 SG_ PAOBJY4 : 149|7@0+ (0.2,-12.6) [-12.6|12.6] "Unitless"  CGW
 SG_ PAOBJX4 : 140|7@0+ (1,-20) [-20|107] "Unitless"  CGW
 SG_ PAOBJID4 : 134|10@0+ (1,0) [0|1023] "Unitless"  CGW
 SG_ PAOBJST3 : 113|3@0+ (1,0) [0|0] ""  CGW
 SG_ PAOBJTY3 : 116|3@0+ (1,0) [0|0] ""  CGW
 SG_ PAOBJYA3 : 105|5@0+ (1,-15) [-15|15] "Unitless"  CGW
 SG_ PAOBJY3 : 96|7@0+ (0.2,-12.6) [-12.6|12.6] "Unitless"  CGW
 SG_ PAOBJX3 : 103|7@0+ (1,-20) [-20|107] "Unitless"  CGW
 SG_ PAOBJID3 : 81|10@0+ (1,0) [0|1023] "Unitless"  CGW
 SG_ PAOBJST2 : 76|3@0+ (1,0) [0|0] ""  CGW
 SG_ PAOBJTY2 : 79|3@0+ (1,0) [0|0] ""  CGW
 SG_ PAOBJYA2 : 68|5@0+ (1,-15) [-15|15] "Unitless"  CGW
 SG_ PAOBJY2 : 59|7@0+ (0.2,-12.6) [-12.6|12.6] "Unitless"  CGW
 SG_ PAOBJX2 : 50|7@0+ (1,-20) [-20|107] "Unitless"  CGW
 SG_ PAOBJID2 : 44|10@0+ (1,0) [0|1023] "Unitless"  CGW
 SG_ PAOBJST1 : 39|3@0+ (1,0) [0|0] ""  CGW
 SG_ PAOBJTY1 : 26|3@0+ (1,0) [0|0] ""  CGW
 SG_ PAOBJYA1 : 31|5@0+ (1,-15) [-15|15] "Unitless"  CGW
 SG_ PAOBJY1 : 22|7@0+ (0.2,-12.6) [-12.6|12.6] "Unitless"  CGW
 SG_ PAOBJX1 : 13|7@0+ (1,-20) [-20|107] "Unitless"  CGW
 SG_ PAOBJID1 : 7|10@0+ (1,0) [0|1023] "Unitless"  CGW

BO_ 1104 ADU_HMI_Information_5: 32 ADU
 SG_ FRC_WRN : 232|2@0+ (1,0) [0|0] ""  CGW
 SG_ FLC_WRN : 234|2@0+ (1,0) [0|0] ""  CGW
 SG_ FR_WRN : 236|2@0+ (1,0) [0|0] ""  CGW
 SG_ FL_WRN : 238|2@0+ (1,0) [0|0] ""  CGW
 SG_ FRC_POS : 228|6@0+ (1,0) [0|0] ""  CGW
 SG_ FLC_POS : 218|6@0+ (1,0) [0|0] ""  CGW
 SG_ FR_POS : 208|6@0+ (1,0) [0|0] ""  CGW
 SG_ FL_POS : 214|6@0+ (1,0) [0|0] ""  CGW
 SG_ RRC_WRN : 204|2@0+ (1,0) [0|0] ""  CGW
 SG_ RLC_WRN : 206|2@0+ (1,0) [0|0] ""  CGW
 SG_ RR_WRN : 192|2@0+ (1,0) [0|0] ""  CGW
 SG_ RL_WRN : 194|2@0+ (1,0) [0|0] ""  CGW
 SG_ RRC_POS : 184|6@0+ (1,0) [0|0] ""  CGW
 SG_ RLC_POS : 190|6@0+ (1,0) [0|0] ""  CGW
 SG_ RR_POS : 180|6@0+ (1,0) [0|0] ""  CGW
 SG_ RL_POS : 170|6@0+ (1,0) [0|0] ""  CGW
 SG_ CSRDISP1 : 164|1@0+ (1,0) [0|0] ""  CGW
 SG_ CSMUTESW : 166|2@0+ (1,0) [0|0] ""  CGW
 SG_ PAS_EV_silent : 167|1@0+ (1,0) [0|0] ""  CGW
 SG_ PAS_state : 155|4@0+ (1,0) [0|0] ""  CGW
 SG_ TSR_gray : 137|2@0+ (1,0) [0|3] "Unitless"  CGW
 SG_ TSR_sub_sup_value : 142|5@0+ (1,0) [0|31] "Unitless"  CGW
 SG_ TSR_sub_value : 132|6@0+ (1,0) [0|63] "Unitless"  CGW
 SG_ TSR_sub_speed : 122|6@0+ (5,0) [0|250] "Unitless"  CGW
 SG_ TSR_EV_tmp_failure : 123|1@0+ (1,0) [0|0] ""  CGW
 SG_ TSR_EV_fallback : 124|1@0+ (1,0) [0|0] ""  CGW
 SG_ TSR_fallback : 126|2@0+ (1,0) [0|0] ""  CGW
 SG_ TSR_next_distance : 111|5@0+ (1,0) [0|31] "Unitless"  CGW
 SG_ TSR_next_value : 97|2@0+ (1,0) [0|3] "Unitless"  CGW
 SG_ TSR_sound : 98|1@0+ (1,0) [0|0] ""  CGW
 SG_ TSR_EV_change : 99|1@0+ (1,0) [0|0] ""  CGW
 SG_ TSR_main_sup_value : 88|5@0+ (1,0) [0|31] "Unitless"  CGW
 SG_ TSR_main_value : 94|6@0+ (1,0) [0|63] "Unitless"  CGW
 SG_ TSR_next_speed : 84|6@0+ (5,0) [0|250] "Unitless"  CGW
 SG_ TSR_main_speed : 74|6@0+ (5,0) [0|250] "Unitless"  CGW
 SG_ TSR_EV_failure : 75|1@0+ (1,0) [0|0] ""  CGW
 SG_ TSR_EV_notification : 76|1@0+ (1,0) [0|0] ""  CGW
 SG_ TSR_warning : 78|2@0+ (1,0) [0|0] ""  CGW
 SG_ TSR_state : 66|4@0+ (1,0) [0|0] ""  CGW
 SG_ LCA_EV_warn_approach_rh : 69|1@0+ (1,0) [0|0] ""  CGW
 SG_ LCA_EV_warn_approach_lh : 70|1@0+ (1,0) [0|0] ""  CGW
 SG_ LCA_EV_auto_standby : 71|1@0+ (1,0) [0|0] ""  CGW
 SG_ LCA_EV_calcel_lka_off : 56|1@0+ (1,0) [0|0] ""  CGW
 SG_ LCA_EV_calcel_lka_on : 57|1@0+ (1,0) [0|0] ""  CGW
 SG_ LCA_state_lh : 62|5@0+ (1,0) [0|0] ""  CGW
 SG_ LCA_state_rh : 51|5@0+ (1,0) [0|0] ""  CGW
 SG_ LCA_state : 40|5@0+ (1,0) [0|0] ""  CGW
 SG_ HoF_handson_request_mute : 36|2@0+ (1,0) [0|0] ""  CGW
 SG_ HOF_approval_rec_state : 38|2@0+ (1,0) [0|0] ""  CGW
 SG_ HOF_rec_state : 24|2@0+ (1,0) [0|0] ""  CGW
 SG_ HOF_state : 29|5@0+ (1,0) [0|0] ""  CGW
 SG_ LKA_controllimit : 2|4@0+ (1,0) [0|0] ""  CGW
 SG_ LKA_state : 7|5@0+ (1,0) [0|0] ""  CGW

BA_DEF_  "BusType" STRING ;
BA_DEF_ BU_  "DiagNode" ENUM  "No","Yes";
BA_DEF_REL_ BU_SG_REL_  "SC_Verification" ENUM  "No","Yes";
BA_DEF_ BO_  "SCP_FreshnessValueTxLength" INT 0 512;
BA_DEF_ BO_  "SCP_FreshnessValueLength" INT 0 512;
BA_DEF_ BO_  "SCP_DataId" INT 0 65535;
BA_DEF_ BO_  "SCP_AuthInfoTxLength" INT 0 512;
BA_DEF_ BO_  "SC_Message" ENUM  "No","Yes";
BA_DEF_ BO_  "CANFD_BRS" ENUM  "0","1";
BA_DEF_ BO_  "VFrameFormat" ENUM  "StandardCAN","ExtendedCAN","reserved","reserved","reserved","reserved","reserved","reserved","reserved","reserved","reserved","reserved","reserved","reserved","StandardCAN_FD","ExtendedCAN_FD";
BA_DEF_ BO_  "DiagRequest" ENUM  "No","Yes";
BA_DEF_ BO_  "DiagResponse" ENUM  "No","Yes";
BA_DEF_ BO_  "DiagState" ENUM  "No","Yes";
BA_DEF_ BO_  "DiagConnection" INT 0 65535;
BA_DEF_ BU_  "EOL_SB_Flash" ENUM  "No","Yes";
BA_DEF_ BU_  "GatewayECU" ENUM  "No","Yes";
BA_DEF_ BO_  "GenMsgCycleTime" INT 0 10000;
BA_DEF_ BO_  "GenMsgCycleTimeFast" INT 0 100000;
BA_DEF_ BO_  "GenMsgDelayTime" INT 0 1000;
BA_DEF_ BO_  "GenMsgILSupport" ENUM  "No","Yes";
BA_DEF_ BO_  "GenMsgNrOfRepetition" INT 0 100;
BA_DEF_ BO_  "GenMsgSendType" ENUM  "FixedPeriodic","Event","EnabledPeriodic","NotUsed","NotUsed","EventPeriodic","NotUsed","NotUsed","NoMsgSendType";
BA_DEF_ SG_  "GenSigSendType" ENUM  "Cyclic","OnWrite","OnWriteWithRepetition","OnChange","OnChangeWithRepetition","IfActive","IfActiveWithRepetition","NoSigSendType";
BA_DEF_ SG_  "GenSigStartValue" FLOAT 0 1E+011;
BA_DEF_ SG_  "GenSigTimeoutTime_CGW" INT 0 100000;
BA_DEF_ SG_  "GenSigTimeoutTime_ADU" INT 0 100000;
BA_DEF_  "Manufacturer" STRING ;
BA_DEF_ BO_  "NetworkInitialization" ENUM  "No","Yes";
BA_DEF_ BU_  "NetworkType" ENUM  "Powertrain","Bodybus","Infotainment";
BA_DEF_  "NmBaseAddress" HEX 0 1280;
BA_DEF_ BU_  "NmCAN" INT 1 2;
BA_DEF_  "NmMessageCount" INT 0 128;
BA_DEF_  "NmType" STRING ;
BA_DEF_ BU_  "NodeLayerModules" STRING ;
BA_DEF_ BU_  "PowerType" ENUM  "Ignition Switched","Secondary Switched","Sleep";
BA_DEF_ BU_  "TransceiverType" ENUM  "Unknown","TJA1050","TJA1040","TJA1041","82C250","TLE6250","MC33989","CS251";
BA_DEF_ BU_  "Version_Ccl" STRING ;
BA_DEF_ BU_  "Version_Diag_CANdesc" STRING ;
BA_DEF_ BU_  "Version_DrvCan" STRING ;
BA_DEF_ BU_  "Version_GW_ILGateway" STRING ;
BA_DEF_ BU_  "Version_IL_NI_Ford" STRING ;
BA_DEF_ BU_  "Version_IL_Vector" STRING ;
BA_DEF_ BU_  "Version_NM_DirOsek" STRING ;
BA_DEF_ BU_  "Version_NM_Junior" STRING ;
BA_DEF_ BU_  "Version_Tp_Iso15765" STRING ;
BA_DEF_  "VersionDay" INT 0 31;
BA_DEF_  "VersionMonth" INT 0 12;
BA_DEF_  "VersionNumber" INT 0 100;
BA_DEF_  "VersionYear" INT 2000 2100;
BA_DEF_ SG_  "GenSigEnvVarType" ENUM  "int","float","undef";
BA_DEF_ SG_  "NWM-WakeupAllowed" ENUM  "No","Yes";
BA_DEF_ BU_  "NmAsrNode" ENUM  "No","Yes";
BA_DEF_  "NmAsrTimeoutTime" INT 1 65535;
BA_DEF_  "NmAsrWaitBusSleepTime" INT 0 65535;
BA_DEF_  "NmAsrRepeatMessageTime" INT 0 65535;
BA_DEF_ BO_  "NmAsrMessage" ENUM  "No","Yes";
BA_DEF_  "NmAsrMessageCount" INT 1 256;
BA_DEF_  "NmAsrBaseAddress" HEX 0 2047;
BA_DEF_ BU_  "NmAsrNodeIdentifier" HEX 0 255;
BA_DEF_  "NmAsrCanMsgCycleTime" INT 1 65535;
BA_DEF_ BU_  "NmAsrCanMsgReducedTime" INT 1 65535;
BA_DEF_ BO_  "GenMsgTxConditionAccOn" ENUM  "No","Yes";
BA_DEF_ BO_  "GenMsgTxConditionIg1On" ENUM  "No","Yes";
BA_DEF_ BO_  "GenMsgTxConditionPlusBOn" ENUM  "No","Yes";
BA_DEF_ SG_  "GenSigInvalidValue" INT 0 10000000000;
BA_DEF_ BU_  "CANoeNodTxTimingIgnitionSwitched" ENUM  "AccOn","IG1On","IG2On","NoNodTxTiming";
BA_DEF_ BO_  "CANoeMsgTxTimingIgnitionSwitched" ENUM  "AccOn","IG1On","IG2On","NoMsgTxTiming";
BA_DEF_  "NM_Active" ENUM  "Active","NotActive";
BA_DEF_DEF_REL_ "SC_Verification" "Yes";
BA_DEF_DEF_  "SCP_FreshnessValueTxLength" 4;
BA_DEF_DEF_  "SCP_FreshnessValueLength" 48;
BA_DEF_DEF_  "SCP_DataId" 0;
BA_DEF_DEF_  "SCP_AuthInfoTxLength" 28;
BA_DEF_DEF_  "SC_Message" "No";
BA_DEF_DEF_  "CANFD_BRS" "1";
BA_DEF_DEF_  "VFrameFormat" "ExtendedCAN_FD";
BA_DEF_DEF_  "BusType" "CAN";
BA_DEF_DEF_  "DiagNode" "Yes";
BA_DEF_DEF_  "DiagRequest" "No";
BA_DEF_DEF_  "DiagResponse" "No";
BA_DEF_DEF_  "DiagState" "No";
BA_DEF_DEF_  "DiagConnection" 0;
BA_DEF_DEF_  "EOL_SB_Flash" "Yes";
BA_DEF_DEF_  "GatewayECU" "No";
BA_DEF_DEF_  "GenMsgCycleTime" 0;
BA_DEF_DEF_  "GenMsgCycleTimeFast" 0;
BA_DEF_DEF_  "GenMsgDelayTime" 20;
BA_DEF_DEF_  "GenMsgILSupport" "Yes";
BA_DEF_DEF_  "GenMsgNrOfRepetition" 0;
BA_DEF_DEF_  "GenMsgSendType" "NoMsgSendType";
BA_DEF_DEF_  "GenSigSendType" "NoSigSendType";
BA_DEF_DEF_  "GenSigStartValue" 0;
BA_DEF_DEF_  "GenSigTimeoutTime_CGW" 5000;
BA_DEF_DEF_  "GenSigTimeoutTime_ADU" 5000;
BA_DEF_DEF_  "Manufacturer" "Ford";
BA_DEF_DEF_  "NetworkInitialization" "No";
BA_DEF_DEF_  "NetworkType" "Powertrain";
BA_DEF_DEF_  "NmBaseAddress" 1280;
BA_DEF_DEF_  "NmCAN" 1;
BA_DEF_DEF_  "NmMessageCount" 128;
BA_DEF_DEF_  "NmType" "Ford-OSEK";
BA_DEF_DEF_  "NodeLayerModules" "";
BA_DEF_DEF_  "PowerType" "Ignition Switched";
BA_DEF_DEF_  "TransceiverType" "Unknown";
BA_DEF_DEF_  "Version_Ccl" "00.00.00";
BA_DEF_DEF_  "Version_Diag_CANdesc" "00.00.00";
BA_DEF_DEF_  "Version_DrvCan" "00.00.00";
BA_DEF_DEF_  "Version_GW_ILGateway" "00.00.00";
BA_DEF_DEF_  "Version_IL_NI_Ford" "00.00.00";
BA_DEF_DEF_  "Version_IL_Vector" "00.00.00";
BA_DEF_DEF_  "Version_NM_DirOsek" "00.00.00";
BA_DEF_DEF_  "Version_NM_Junior" "00.00.00";
BA_DEF_DEF_  "Version_Tp_Iso15765" "00.00.00";
BA_DEF_DEF_  "VersionDay" 1;
BA_DEF_DEF_  "VersionMonth" 1;
BA_DEF_DEF_  "VersionNumber" 1;
BA_DEF_DEF_  "VersionYear" 2005;
BA_DEF_DEF_  "GenSigEnvVarType" "undef";
BA_DEF_DEF_  "NWM-WakeupAllowed" "No";
BA_DEF_DEF_  "NmAsrNode" "No";
BA_DEF_DEF_  "NmAsrTimeoutTime" 1000;
BA_DEF_DEF_  "NmAsrWaitBusSleepTime" 750;
BA_DEF_DEF_  "NmAsrRepeatMessageTime" 400;
BA_DEF_DEF_  "NmAsrMessage" "No";
BA_DEF_DEF_  "NmAsrMessageCount" 128;
BA_DEF_DEF_  "NmAsrBaseAddress" 1408;
BA_DEF_DEF_  "NmAsrNodeIdentifier" 0;
BA_DEF_DEF_  "NmAsrCanMsgCycleTime" 100;
BA_DEF_DEF_  "NmAsrCanMsgReducedTime" 50;
BA_DEF_DEF_  "GenMsgTxConditionAccOn" "No";
BA_DEF_DEF_  "GenMsgTxConditionIg1On" "No";
BA_DEF_DEF_  "GenMsgTxConditionPlusBOn" "No";
BA_DEF_DEF_  "GenSigInvalidValue" 0;
BA_DEF_DEF_  "CANoeNodTxTimingIgnitionSwitched" "NoNodTxTiming";
BA_DEF_DEF_  "CANoeMsgTxTimingIgnitionSwitched" "NoMsgTxTiming";
BA_DEF_DEF_  "NM_Active" "NotActive";
BA_ "BusType" "CAN FD";
BA_ "VersionNumber" 0;
BA_ "VersionDay" 30;
BA_ "VersionMonth" 5;
BA_ "VersionYear" 2024;
BA_ "NmType" "NmAsr";
BA_ "NmAsrTimeoutTime" 3000;
BA_ "NmAsrWaitBusSleepTime" 1500;
BA_ "NmAsrRepeatMessageTime" 5000;
BA_ "NmAsrCanMsgCycleTime" 1000;
BA_ "GenMsgSendType" BO_ 2564550625 1;
BA_ "DiagState" BO_ 2564550625 1;
BA_ "DiagConnection" BO_ 2564550625 57600;
BA_ "GenMsgILSupport" BO_ 2564550625 0;
BA_ "VFrameFormat" BO_ 2564550625 1;
BA_ "CANFD_BRS" BO_ 2564550625 0;
BA_ "GenMsgSendType" BO_ 2564481413 1;
BA_ "GenMsgDelayTime" BO_ 2564481413 0;
BA_ "DiagResponse" BO_ 2564481413 1;
BA_ "DiagConnection" BO_ 2564481413 57733;
BA_ "GenMsgILSupport" BO_ 2564481413 0;
BA_ "GenMsgSendType" BO_ 2564457953 1;
BA_ "DiagRequest" BO_ 2564457953 1;
BA_ "DiagConnection" BO_ 2564457953 57733;
BA_ "GenMsgILSupport" BO_ 2564457953 0;
BA_ "GenMsgSendType" BO_ 2564481412 1;
BA_ "GenMsgDelayTime" BO_ 2564481412 0;
BA_ "DiagResponse" BO_ 2564481412 1;
BA_ "DiagConnection" BO_ 2564481412 57732;
BA_ "GenMsgILSupport" BO_ 2564481412 0;
BA_ "GenMsgSendType" BO_ 2564457697 1;
BA_ "DiagRequest" BO_ 2564457697 1;
BA_ "DiagConnection" BO_ 2564457697 57732;
BA_ "GenMsgILSupport" BO_ 2564457697 0;
BA_ "GenMsgSendType" BO_ 2564481411 1;
BA_ "GenMsgDelayTime" BO_ 2564481411 0;
BA_ "DiagResponse" BO_ 2564481411 1;
BA_ "DiagConnection" BO_ 2564481411 57731;
BA_ "GenMsgILSupport" BO_ 2564481411 0;
BA_ "GenMsgSendType" BO_ 2564457441 1;
BA_ "DiagRequest" BO_ 2564457441 1;
BA_ "DiagConnection" BO_ 2564457441 57731;
BA_ "GenMsgILSupport" BO_ 2564457441 0;
BA_ "GenMsgSendType" BO_ 2564481410 1;
BA_ "GenMsgDelayTime" BO_ 2564481410 0;
BA_ "DiagResponse" BO_ 2564481410 1;
BA_ "DiagConnection" BO_ 2564481410 57730;
BA_ "GenMsgILSupport" BO_ 2564481410 0;
BA_ "GenMsgSendType" BO_ 2564457185 1;
BA_ "DiagRequest" BO_ 2564457185 1;
BA_ "DiagConnection" BO_ 2564457185 57730;
BA_ "GenMsgILSupport" BO_ 2564457185 0;
BA_ "GenMsgSendType" BO_ 2564481397 1;
BA_ "GenMsgDelayTime" BO_ 2564481397 0;
BA_ "DiagResponse" BO_ 2564481397 1;
BA_ "DiagConnection" BO_ 2564481397 57717;
BA_ "GenMsgILSupport" BO_ 2564481397 0;
BA_ "GenMsgSendType" BO_ 2564453857 1;
BA_ "DiagRequest" BO_ 2564453857 1;
BA_ "DiagConnection" BO_ 2564453857 57717;
BA_ "GenMsgILSupport" BO_ 2564453857 0;
BA_ "GenMsgSendType" BO_ 2564481392 1;
BA_ "GenMsgDelayTime" BO_ 2564481392 0;
BA_ "DiagResponse" BO_ 2564481392 1;
BA_ "DiagConnection" BO_ 2564481392 57712;
BA_ "GenMsgILSupport" BO_ 2564481392 0;
BA_ "GenMsgSendType" BO_ 2564452577 1;
BA_ "DiagRequest" BO_ 2564452577 1;
BA_ "DiagConnection" BO_ 2564452577 57712;
BA_ "GenMsgILSupport" BO_ 2564452577 0;
BA_ "GenMsgSendType" BO_ 2564550624 1;
BA_ "DiagState" BO_ 2564550624 1;
BA_ "DiagConnection" BO_ 2564550624 57344;
BA_ "GenMsgILSupport" BO_ 2564550624 0;
BA_ "VFrameFormat" BO_ 2564550624 1;
BA_ "CANFD_BRS" BO_ 2564550624 0;
BA_ "GenMsgSendType" BO_ 2564481157 1;
BA_ "GenMsgDelayTime" BO_ 2564481157 0;
BA_ "DiagResponse" BO_ 2564481157 1;
BA_ "DiagConnection" BO_ 2564481157 57477;
BA_ "GenMsgILSupport" BO_ 2564481157 0;
BA_ "GenMsgSendType" BO_ 2564457952 1;
BA_ "DiagRequest" BO_ 2564457952 1;
BA_ "DiagConnection" BO_ 2564457952 57477;
BA_ "GenMsgILSupport" BO_ 2564457952 0;
BA_ "GenMsgSendType" BO_ 2564481156 1;
BA_ "GenMsgDelayTime" BO_ 2564481156 0;
BA_ "DiagResponse" BO_ 2564481156 1;
BA_ "DiagConnection" BO_ 2564481156 57476;
BA_ "GenMsgILSupport" BO_ 2564481156 0;
BA_ "GenMsgSendType" BO_ 2564457696 1;
BA_ "DiagRequest" BO_ 2564457696 1;
BA_ "DiagConnection" BO_ 2564457696 57476;
BA_ "GenMsgILSupport" BO_ 2564457696 0;
BA_ "GenMsgSendType" BO_ 2564481155 1;
BA_ "GenMsgDelayTime" BO_ 2564481155 0;
BA_ "DiagResponse" BO_ 2564481155 1;
BA_ "DiagConnection" BO_ 2564481155 57475;
BA_ "GenMsgILSupport" BO_ 2564481155 0;
BA_ "GenMsgSendType" BO_ 2564457440 1;
BA_ "DiagRequest" BO_ 2564457440 1;
BA_ "DiagConnection" BO_ 2564457440 57475;
BA_ "GenMsgILSupport" BO_ 2564457440 0;
BA_ "GenMsgSendType" BO_ 2564481154 1;
BA_ "GenMsgDelayTime" BO_ 2564481154 0;
BA_ "DiagResponse" BO_ 2564481154 1;
BA_ "DiagConnection" BO_ 2564481154 57474;
BA_ "GenMsgILSupport" BO_ 2564481154 0;
BA_ "GenMsgSendType" BO_ 2564457184 1;
BA_ "DiagRequest" BO_ 2564457184 1;
BA_ "DiagConnection" BO_ 2564457184 57474;
BA_ "GenMsgILSupport" BO_ 2564457184 0;
BA_ "GenMsgSendType" BO_ 2564481141 1;
BA_ "GenMsgDelayTime" BO_ 2564481141 0;
BA_ "DiagResponse" BO_ 2564481141 1;
BA_ "DiagConnection" BO_ 2564481141 57461;
BA_ "GenMsgILSupport" BO_ 2564481141 0;
BA_ "GenMsgSendType" BO_ 2564453856 1;
BA_ "DiagRequest" BO_ 2564453856 1;
BA_ "DiagConnection" BO_ 2564453856 57461;
BA_ "GenMsgILSupport" BO_ 2564453856 0;
BA_ "GenMsgSendType" BO_ 2564481136 1;
BA_ "GenMsgDelayTime" BO_ 2564481136 0;
BA_ "DiagResponse" BO_ 2564481136 1;
BA_ "DiagConnection" BO_ 2564481136 57456;
BA_ "GenMsgILSupport" BO_ 2564481136 0;
BA_ "GenMsgSendType" BO_ 2564452576 1;
BA_ "DiagRequest" BO_ 2564452576 1;
BA_ "DiagConnection" BO_ 2564452576 57456;
BA_ "GenMsgILSupport" BO_ 2564452576 0;
BA_ "GenSigSendType" SG_ 2564550625 Sig_Functional_Diag_RequestOn_bo 3;
BA_ "GenSigSendType" SG_ 2564481413 Sig_FLR_Diag_Tx_E1 3;
BA_ "GenSigSendType" SG_ 2564457953 Sig_FLR_Diag_Rx_E1 3;
BA_ "GenSigSendType" SG_ 2564481412 Sig_FRR_Diag_Tx_E1 3;
BA_ "GenSigSendType" SG_ 2564457697 Sig_FRR_Diag_Rx_E1 3;
BA_ "GenSigSendType" SG_ 2564481411 Sig_RLR_Diag_Tx_E1 3;
BA_ "GenSigSendType" SG_ 2564457441 Sig_RLR_Diag_Rx_E1 3;
BA_ "GenSigSendType" SG_ 2564481410 Sig_RRR_Diag_Tx_E1 3;
BA_ "GenSigSendType" SG_ 2564457185 Sig_RRR_Diag_Rx_E1 3;
BA_ "GenSigSendType" SG_ 2564481397 Sig_ADU_Diag_Tx_E1 3;
BA_ "GenSigSendType" SG_ 2564453857 Sig_ADU_Diag_Rx_E1 3;
BA_ "GenSigSendType" SG_ 2564481392 Sig_FRD_Diag_Tx_E1 3;
BA_ "GenSigSendType" SG_ 2564452577 Sig_FRD_Diag_Rx_E1 3;
BA_ "GenSigSendType" SG_ 2564550624 Sig_Functional_Diag_RequestOff_b 3;
BA_ "GenSigSendType" SG_ 2564481157 Sig_FLR_Diag_Tx_E0 3;
BA_ "GenSigSendType" SG_ 2564457952 Sig_FLR_Diag_Rx_E0 3;
BA_ "GenSigSendType" SG_ 2564481156 Sig_FRR_Diag_Tx_E0 3;
BA_ "GenSigSendType" SG_ 2564457696 Sig_FRR_Diag_Rx_E0 3;
BA_ "GenSigSendType" SG_ 2564481155 Sig_RLR_Diag_Tx_E0 3;
BA_ "GenSigSendType" SG_ 2564457440 Sig_RLR_Diag_Rx_E0 3;
BA_ "GenSigSendType" SG_ 2564481154 Sig_RRR_Diag_Tx_E0 3;
BA_ "GenSigSendType" SG_ 2564457184 Sig_RRR_Diag_Rx_E0 3;
BA_ "GenSigSendType" SG_ 2564481141 Sig_ADU_Diag_Tx_E0 3;
BA_ "GenSigSendType" SG_ 2564453856 Sig_ADU_Diag_Rx_E0 3;
BA_ "GenSigSendType" SG_ 2564481136 Sig_FRD_Diag_Tx_E0 3;
BA_ "GenSigSendType" SG_ 2564452576 Sig_FRD_Diag_Rx_E0 3;
BA_ "GenMsgSendType" BO_ 1409 1;
BA_ "NmAsrMessage" BO_ 1409 1;
BA_ "GenMsgILSupport" BO_ 1409 0;
BA_ "VFrameFormat" BO_ 1409 14;
BA_ "GenMsgSendType" BO_ 1340 0;
BA_ "GenMsgCycleTime" BO_ 1340 500;
BA_ "VFrameFormat" BO_ 1340 14;
BA_ "GenMsgSendType" BO_ 1339 0;
BA_ "GenMsgCycleTime" BO_ 1339 500;
BA_ "VFrameFormat" BO_ 1339 14;
BA_ "GenMsgSendType" BO_ 1338 0;
BA_ "GenMsgCycleTime" BO_ 1338 500;
BA_ "VFrameFormat" BO_ 1338 14;
BA_ "GenMsgSendType" BO_ 1337 0;
BA_ "GenMsgCycleTime" BO_ 1337 500;
BA_ "VFrameFormat" BO_ 1337 14;
BA_ "GenMsgSendType" BO_ 1336 0;
BA_ "GenMsgCycleTime" BO_ 1336 500;
BA_ "VFrameFormat" BO_ 1336 14;
BA_ "GenMsgSendType" BO_ 1321 0;
BA_ "GenMsgCycleTime" BO_ 1321 500;
BA_ "VFrameFormat" BO_ 1321 14;
BA_ "GenMsgSendType" BO_ 1276 0;
BA_ "GenMsgCycleTime" BO_ 1276 1000;
BA_ "VFrameFormat" BO_ 1276 14;
BA_ "GenMsgSendType" BO_ 1275 0;
BA_ "GenMsgCycleTime" BO_ 1275 1000;
BA_ "VFrameFormat" BO_ 1275 14;
BA_ "GenMsgSendType" BO_ 1274 0;
BA_ "GenMsgCycleTime" BO_ 1274 500;
BA_ "VFrameFormat" BO_ 1274 14;
BA_ "GenMsgSendType" BO_ 1273 0;
BA_ "GenMsgCycleTime" BO_ 1273 1000;
BA_ "VFrameFormat" BO_ 1273 14;
BA_ "GenMsgSendType" BO_ 1272 0;
BA_ "GenMsgCycleTime" BO_ 1272 1000;
BA_ "VFrameFormat" BO_ 1272 14;
BA_ "GenMsgSendType" BO_ 1269 5;
BA_ "GenMsgCycleTime" BO_ 1269 200;
BA_ "VFrameFormat" BO_ 1269 14;
BA_ "GenMsgSendType" BO_ 1268 1;
BA_ "VFrameFormat" BO_ 1268 14;
BA_ "GenMsgSendType" BO_ 1267 5;
BA_ "GenMsgCycleTime" BO_ 1267 100;
BA_ "VFrameFormat" BO_ 1267 14;
BA_ "GenMsgSendType" BO_ 1259 5;
BA_ "GenMsgCycleTime" BO_ 1259 1000;
BA_ "VFrameFormat" BO_ 1259 14;
BA_ "GenMsgSendType" BO_ 1258 0;
BA_ "GenMsgCycleTime" BO_ 1258 1000;
BA_ "VFrameFormat" BO_ 1258 14;
BA_ "GenMsgSendType" BO_ 1256 5;
BA_ "GenMsgCycleTime" BO_ 1256 1000;
BA_ "VFrameFormat" BO_ 1256 14;
BA_ "GenMsgSendType" BO_ 1195 5;
BA_ "GenMsgCycleTime" BO_ 1195 1000;
BA_ "VFrameFormat" BO_ 1195 14;
BA_ "GenMsgSendType" BO_ 1193 5;
BA_ "GenMsgCycleTime" BO_ 1193 1000;
BA_ "VFrameFormat" BO_ 1193 14;
BA_ "GenMsgSendType" BO_ 1192 5;
BA_ "GenMsgCycleTime" BO_ 1192 1000;
BA_ "VFrameFormat" BO_ 1192 14;
BA_ "GenMsgSendType" BO_ 1191 5;
BA_ "GenMsgCycleTime" BO_ 1191 1000;
BA_ "VFrameFormat" BO_ 1191 14;
BA_ "GenMsgSendType" BO_ 1182 5;
BA_ "GenMsgCycleTime" BO_ 1182 500;
BA_ "VFrameFormat" BO_ 1182 14;
BA_ "GenMsgSendType" BO_ 1170 5;
BA_ "GenMsgCycleTime" BO_ 1170 500;
BA_ "VFrameFormat" BO_ 1170 14;
BA_ "GenMsgSendType" BO_ 1169 1;
BA_ "VFrameFormat" BO_ 1169 14;
BA_ "GenMsgSendType" BO_ 1168 1;
BA_ "VFrameFormat" BO_ 1168 14;
BA_ "GenMsgSendType" BO_ 1166 5;
BA_ "GenMsgCycleTime" BO_ 1166 500;
BA_ "VFrameFormat" BO_ 1166 14;
BA_ "GenMsgSendType" BO_ 1157 5;
BA_ "GenMsgCycleTime" BO_ 1157 500;
BA_ "VFrameFormat" BO_ 1157 14;
BA_ "GenMsgSendType" BO_ 1154 5;
BA_ "GenMsgCycleTime" BO_ 1154 500;
BA_ "VFrameFormat" BO_ 1154 14;
BA_ "GenMsgSendType" BO_ 1148 5;
BA_ "GenMsgCycleTime" BO_ 1148 1000;
BA_ "VFrameFormat" BO_ 1148 14;
BA_ "GenMsgSendType" BO_ 1147 5;
BA_ "GenMsgCycleTime" BO_ 1147 1000;
BA_ "VFrameFormat" BO_ 1147 14;
BA_ "GenMsgSendType" BO_ 1146 5;
BA_ "GenMsgCycleTime" BO_ 1146 1000;
BA_ "VFrameFormat" BO_ 1146 14;
BA_ "GenMsgSendType" BO_ 1145 5;
BA_ "GenMsgCycleTime" BO_ 1145 1000;
BA_ "VFrameFormat" BO_ 1145 14;
BA_ "GenMsgSendType" BO_ 1144 5;
BA_ "GenMsgCycleTime" BO_ 1144 1000;
BA_ "VFrameFormat" BO_ 1144 14;
BA_ "GenMsgSendType" BO_ 1143 0;
BA_ "GenMsgCycleTime" BO_ 1143 500;
BA_ "VFrameFormat" BO_ 1143 14;
BA_ "GenMsgSendType" BO_ 1142 0;
BA_ "GenMsgCycleTime" BO_ 1142 500;
BA_ "VFrameFormat" BO_ 1142 14;
BA_ "GenMsgSendType" BO_ 1130 0;
BA_ "GenMsgCycleTime" BO_ 1130 1000;
BA_ "VFrameFormat" BO_ 1130 14;
BA_ "GenMsgSendType" BO_ 1129 0;
BA_ "GenMsgCycleTime" BO_ 1129 1000;
BA_ "VFrameFormat" BO_ 1129 14;
BA_ "GenMsgSendType" BO_ 1125 0;
BA_ "GenMsgCycleTime" BO_ 1125 200;
BA_ "VFrameFormat" BO_ 1125 14;
BA_ "GenMsgSendType" BO_ 1120 5;
BA_ "GenMsgCycleTime" BO_ 1120 500;
BA_ "GenMsgCycleTimeFast" BO_ 1120 50;
BA_ "GenMsgNrOfRepetition" BO_ 1120 5;
BA_ "VFrameFormat" BO_ 1120 14;
BA_ "GenMsgSendType" BO_ 1112 5;
BA_ "GenMsgCycleTime" BO_ 1112 500;
BA_ "VFrameFormat" BO_ 1112 14;
BA_ "GenMsgSendType" BO_ 1109 5;
BA_ "GenMsgCycleTime" BO_ 1109 100;
BA_ "VFrameFormat" BO_ 1109 14;
BA_ "GenMsgSendType" BO_ 1108 5;
BA_ "GenMsgCycleTime" BO_ 1108 100;
BA_ "VFrameFormat" BO_ 1108 14;
BA_ "GenMsgSendType" BO_ 1107 5;
BA_ "GenMsgCycleTime" BO_ 1107 100;
BA_ "VFrameFormat" BO_ 1107 14;
BA_ "GenMsgSendType" BO_ 1106 5;
BA_ "GenMsgCycleTime" BO_ 1106 100;
BA_ "VFrameFormat" BO_ 1106 14;
BA_ "GenMsgSendType" BO_ 1105 5;
BA_ "GenMsgCycleTime" BO_ 1105 100;
BA_ "VFrameFormat" BO_ 1105 14;
BA_ "GenMsgSendType" BO_ 1104 5;
BA_ "GenMsgCycleTime" BO_ 1104 100;
BA_ "VFrameFormat" BO_ 1104 14;
BA_ "GenMsgTxConditionIg1On" BO_ 1340 1;
BA_ "GenMsgTxConditionIg1On" BO_ 1339 1;
BA_ "GenMsgTxConditionIg1On" BO_ 1338 1;
BA_ "GenMsgTxConditionIg1On" BO_ 1337 1;
BA_ "GenMsgTxConditionIg1On" BO_ 1336 1;
BA_ "GenMsgTxConditionIg1On" BO_ 1276 1;
BA_ "GenMsgTxConditionIg1On" BO_ 1275 1;
BA_ "GenMsgTxConditionIg1On" BO_ 1274 1;
BA_ "GenMsgTxConditionIg1On" BO_ 1273 1;
BA_ "GenMsgTxConditionIg1On" BO_ 1272 1;
BA_ "GenMsgTxConditionIg1On" BO_ 1269 1;
BA_ "GenMsgTxConditionIg1On" BO_ 1259 1;
BA_ "GenMsgTxConditionIg1On" BO_ 1258 1;
BA_ "GenMsgTxConditionIg1On" BO_ 1195 1;
BA_ "GenMsgTxConditionIg1On" BO_ 1193 1;
BA_ "GenMsgTxConditionIg1On" BO_ 1192 1;
BA_ "GenMsgTxConditionIg1On" BO_ 1191 1;
BA_ "GenMsgTxConditionIg1On" BO_ 1148 1;
BA_ "GenMsgTxConditionIg1On" BO_ 1147 1;
BA_ "GenMsgTxConditionIg1On" BO_ 1146 1;
BA_ "GenMsgTxConditionIg1On" BO_ 1145 1;
BA_ "GenMsgTxConditionIg1On" BO_ 1144 1;
BA_ "GenMsgTxConditionIg1On" BO_ 1143 1;
BA_ "GenMsgTxConditionIg1On" BO_ 1142 1;
BA_ "GenMsgTxConditionIg1On" BO_ 1130 1;
BA_ "GenMsgTxConditionIg1On" BO_ 1129 1;
BA_ "GenMsgTxConditionIg1On" BO_ 1108 1;
BA_ "GenMsgTxConditionIg1On" BO_ 1107 1;
BA_ "GenMsgTxConditionIg1On" BO_ 1106 1;
BA_ "GenMsgTxConditionIg1On" BO_ 1105 1;
BA_ "GenMsgTxConditionIg1On" BO_ 1104 1;
BA_ "GenMsgTxConditionPlusBOn" BO_ 1321 1;
BA_ "GenMsgTxConditionPlusBOn" BO_ 1268 1;
BA_ "GenMsgTxConditionPlusBOn" BO_ 1267 1;
BA_ "GenMsgTxConditionPlusBOn" BO_ 1256 1;
BA_ "GenMsgTxConditionPlusBOn" BO_ 1182 1;
BA_ "GenMsgTxConditionPlusBOn" BO_ 1170 1;
BA_ "GenMsgTxConditionPlusBOn" BO_ 1169 1;
BA_ "GenMsgTxConditionPlusBOn" BO_ 1168 1;
BA_ "GenMsgTxConditionPlusBOn" BO_ 1166 1;
BA_ "GenMsgTxConditionPlusBOn" BO_ 1157 1;
BA_ "GenMsgTxConditionPlusBOn" BO_ 1154 1;
BA_ "GenMsgTxConditionPlusBOn" BO_ 1125 1;
BA_ "GenMsgTxConditionPlusBOn" BO_ 1120 1;
BA_ "GenMsgTxConditionPlusBOn" BO_ 1112 1;
BA_ "GenMsgTxConditionPlusBOn" BO_ 1109 1;
BA_ "NmAsrNodeIdentifier" BU_ CGW 1;
BA_ "NmAsrCanMsgReducedTime" BU_ CGW 1000;
BA_ "NmAsrNode" BU_ CGW 1;
BA_ "NodeLayerModules" BU_ CGW "AsrNm30.dll";
BA_ "NodeLayerModules" BU_ ADU "AsrNm30.dll";
BA_ "DiagNode" BU_ Traffic 0;
BA_ "DiagNode" BU_ Tester 0;
BA_ "GatewayECU" BU_ CGW 1;
BA_ "PowerType" BU_ CGW 2;
BA_ "PowerType" BU_ ADU 2;
BA_ "NodeLayerModules" BU_ Tester "osek_tp.dll";
BA_ "GenSigStartValue" SG_ 1276 V_IDASEN 2;
BA_ "GenSigStartValue" SG_ 1274 USMDSTSL 15;
BA_ "GenSigStartValue" SG_ 1274 USMDSTTS 31;
BA_ "GenSigStartValue" SG_ 1274 USMREQG 31;
BA_ "GenSigSendType" SG_ 1269 EDRAP 3;
BA_ "GenSigSendType" SG_ 1269 EDRRCP 3;
BA_ "GenSigSendType" SG_ 1268 ADUREV 3;
BA_ "GenSigSendType" SG_ 1267 MeterInfo_Cs 3;
BA_ "GenSigTimeoutTime_ADU" SG_ 1267 MeterInfo_Cs 300;
BA_ "GenSigSendType" SG_ 1267 MeterInfo_Cnt 3;
BA_ "GenSigTimeoutTime_ADU" SG_ 1267 MeterInfo_Cnt 300;
BA_ "GenSigSendType" SG_ 1267 DimmerCancel_Stat 3;
BA_ "GenSigSendType" SG_ 1267 Disp_Status_B_Actl 3;
BA_ "GenSigTimeoutTime_ADU" SG_ 1267 Disp_Status_B_Actl 300;
BA_ "GenSigSendType" SG_ 1267 TVMOfSw_B_Actl 3;
BA_ "GenSigTimeoutTime_ADU" SG_ 1267 TVMOfSw_B_Actl 300;
BA_ "GenSigSendType" SG_ 1267 DimmerCancel_Rq 3;
BA_ "GenSigSendType" SG_ 1267 PanelBrightLevel_Rq 3;
BA_ "GenSigStartValue" SG_ 1267 PanelBrightLevel_Rq 100;
BA_ "GenSigInvalidValue" SG_ 1267 PanelBrightLevel_Rq 255;
BA_ "GenSigSendType" SG_ 1267 Drive_Mode_SW_ErrSts_Touch 3;
BA_ "GenSigSendType" SG_ 1267 Drive_Mode_SW_ErrSts_Strg 3;
BA_ "GenSigSendType" SG_ 1267 Drive_Mode_Req_CDC 3;
BA_ "GenSigSendType" SG_ 1267 AEB_HEC_Fail_Flag 3;
BA_ "GenSigTimeoutTime_ADU" SG_ 1267 AEB_HEC_Fail_Flag 300;
BA_ "GenSigSendType" SG_ 1267 AvgFuelEco_Rst_HEC 3;
BA_ "GenSigTimeoutTime_ADU" SG_ 1267 Veh_speed 300;
BA_ "GenSigTimeoutTime_ADU" SG_ 1267 Veh_speed_Fault 300;
BA_ "GenSigTimeoutTime_ADU" SG_ 1267 Veh_speed_Unit 300;
BA_ "GenSigSendType" SG_ 1267 RSRmid_TmpOffReq 3;
BA_ "GenSigSendType" SG_ 1259 CTACANC 3;
BA_ "GenSigSendType" SG_ 1256 RSCYCL16 3;
BA_ "GenSigSendType" SG_ 1256 RSCYCL15 3;
BA_ "GenSigSendType" SG_ 1195 TMNSBIND 3;
BA_ "GenSigSendType" SG_ 1195 TMNSIND 3;
BA_ "GenSigSendType" SG_ 1195 LVNBUZF 3;
BA_ "GenSigSendType" SG_ 1195 LVNINDF 3;
BA_ "GenSigSendType" SG_ 1193 PRECNT 3;
BA_ "GenSigSendType" SG_ 1193 DVCNTEXT 3;
BA_ "GenSigSendType" SG_ 1193 DVCNTSEL 3;
BA_ "GenSigSendType" SG_ 1193 RSACTIVE 3;
BA_ "GenSigSendType" SG_ 1193 DVAT_STS 3;
BA_ "GenSigSendType" SG_ 1193 DVAT_EXT 3;
BA_ "GenSigSendType" SG_ 1193 TSREQPD 3;
BA_ "GenSigSendType" SG_ 1192 SYNCID2 3;
BA_ "GenSigSendType" SG_ 1192 SGNNUMA 3;
BA_ "GenSigSendType" SG_ 1192 SGNNUMP 3;
BA_ "GenSigSendType" SG_ 1192 SPBZRQ 3;
BA_ "GenSigSendType" SG_ 1192 TSGNHLT4 3;
BA_ "GenSigSendType" SG_ 1192 SGNNUMH 3;
BA_ "GenSigSendType" SG_ 1192 TSGN4 3;
BA_ "GenSigSendType" SG_ 1192 SPLSGN4 3;
BA_ "GenSigSendType" SG_ 1192 SPLSGN3 3;
BA_ "GenSigSendType" SG_ 1192 TSGNHLT3 3;
BA_ "GenSigSendType" SG_ 1192 TSGN3 3;
BA_ "GenSigSendType" SG_ 1191 SYNCID1 3;
BA_ "GenSigSendType" SG_ 1191 BZRRQ_A 3;
BA_ "GenSigSendType" SG_ 1191 SPDVAL2 3;
BA_ "GenSigSendType" SG_ 1191 TSGNHLT2 3;
BA_ "GenSigSendType" SG_ 1191 TSGN2 3;
BA_ "GenSigSendType" SG_ 1191 SPLSGN2 3;
BA_ "GenSigSendType" SG_ 1191 SPLSGN1 3;
BA_ "GenSigSendType" SG_ 1191 SPDVAL1 3;
BA_ "GenSigSendType" SG_ 1191 TSGNHLT1 3;
BA_ "GenSigSendType" SG_ 1191 TSGN1 3;
BA_ "GenSigSendType" SG_ 1182 CstmzStat_RCD_ONOFF_GUI 3;
BA_ "GenSigSendType" SG_ 1182 CstmzStat_TAP_ALERT_ONOFF_GUI 3;
BA_ "GenSigSendType" SG_ 1182 CstmzStat_APS_RPC_DISTANCE_GUI 3;
BA_ "GenSigSendType" SG_ 1182 CstmzStat_PK_TrvB_EndP_GUI 3;
BA_ "GenSigSendType" SG_ 1182 CstmzStat_PK_TrvF_EndP_GUI 3;
BA_ "GenSigSendType" SG_ 1182 CstmzStat_PK_VehBLen_GUI 3;
BA_ "GenSigSendType" SG_ 1182 CstmzStat_PKout_View_GUI 3;
BA_ "GenSigSendType" SG_ 1182 CstmzStat_PKin_View_GUI 3;
BA_ "GenSigSendType" SG_ 1182 CstmzStat_PKout_PallalelDir_GUI 3;
BA_ "GenSigSendType" SG_ 1182 CstmzStat_PKout_CrossDir_GUI 3;
BA_ "GenSigSendType" SG_ 1182 CstmzStat_PK_Rd_Wid_GUI 3;
BA_ "GenSigSendType" SG_ 1182 CstmzStat_PK_Trv_Line_GUI 3;
BA_ "GenSigSendType" SG_ 1182 CstmzStat_PK_Veh_Dir_GUI 3;
BA_ "GenSigSendType" SG_ 1182 CstmzStat_APVSPD_LVL_GUI 3;
BA_ "GenSigSendType" SG_ 1182 CstmzStat_GUIDE_ONOFF_GUI 3;
BA_ "GenSigSendType" SG_ 1182 CstmzStat_RPC_ONOFF_GUI 3;
BA_ "GenSigSendType" SG_ 1182 CstmzStat_ACC_GDMS_ONOFF_GUI 3;
BA_ "GenSigSendType" SG_ 1182 CstmzStat_ACC_ACCL_Sens_GUI 3;
BA_ "GenSigSendType" SG_ 1182 CstmzStat_ACC_CURVE_Sens_GUI 3;
BA_ "GenSigSendType" SG_ 1182 CstmzStat_ACC_OVTK_ONOFF_GUI 3;
BA_ "GenSigSendType" SG_ 1182 CstmzStat_TMN_LV_Sens_GUI 3;
BA_ "GenSigSendType" SG_ 1182 CstmzStat_TMN_TS_Sens_GUI 3;
BA_ "GenSigSendType" SG_ 1182 CstmzStat_LCA_ONOFF_GUI 3;
BA_ "GenSigSendType" SG_ 1182 CstmzStat_HOF_REC_ONOFF_GUI 3;
BA_ "GenSigSendType" SG_ 1182 CstmzStat_HOF_ONOFF_GUI 3;
BA_ "GenSigSendType" SG_ 1182 CstmzStat_ESA_AES_ONOFF_GUI 3;
BA_ "GenSigSendType" SG_ 1182 CstmzStat_PDA_Sens_GUI 3;
BA_ "GenSigSendType" SG_ 1182 CstmzStat_PDA_ONOFF_GUI 3;
BA_ "GenSigSendType" SG_ 1182 CstmzStat_TVM_MOAAuto_ONOFF_GUI 3;
BA_ "GenSigSendType" SG_ 1182 CstmzStat_TVM_MOA_ONOFF_GUI 3;
BA_ "GenSigSendType" SG_ 1182 CstmzStat_TVM_AutoOFF_ONOFF_GUI 3;
BA_ "GenSigSendType" SG_ 1182 CstmzStat_TVM_PASRear_Sens_GUI 3;
BA_ "GenSigSendType" SG_ 1182 CstmzStat_TVM_PASFront_Sens_GUI 3;
BA_ "GenSigSendType" SG_ 1182 CstmzStat_TVM_PAS_ONOFF_GUI 3;
BA_ "GenSigSendType" SG_ 1182 CstmzStat_PAS_Vol_GUI 3;
BA_ "GenSigSendType" SG_ 1182 CstmzStat_PAS_ONOFF_GUI 3;
BA_ "GenSigSendType" SG_ 1182 CstmzStat_EDA_ONOFF_GUI 3;
BA_ "GenSigSendType" SG_ 1182 CstmzStat_EDA_Sleep_ONOFF_GUI 3;
BA_ "GenSigSendType" SG_ 1182 CstmzStat_DM_ONOFF_GUI 3;
BA_ "GenSigSendType" SG_ 1182 CstmzStat_OCP_ONOFF_GUI 3;
BA_ "GenSigSendType" SG_ 1182 CstmzStat_BSP_ONOFF_GUI 3;
BA_ "GenSigSendType" SG_ 1182 CstmzStat_RDP_ONOFF_GUI 3;
BA_ "GenSigSendType" SG_ 1182 CstmzStat_ELK_ONOFF_GUI 3;
BA_ "GenSigSendType" SG_ 1182 CstmzStat_RAEB_ONOFF_GUI 3;
BA_ "GenSigSendType" SG_ 1182 CstmzStat_HeadOn_ONOFF_GUI 3;
BA_ "GenSigSendType" SG_ 1182 CstmzStat_TAP_ONOFF_GUI 3;
BA_ "GenSigSendType" SG_ 1182 CstmzStat_CTB_ONOFF_GUI 3;
BA_ "GenSigSendType" SG_ 1182 CstmzStat_AEB_Vol_GUI 3;
BA_ "GenSigSendType" SG_ 1182 CstmzStat_FAEB_ONOFF_GUI 3;
BA_ "GenSigSendType" SG_ 1182 CstmzStat_LDP_ONOFF_GUI 3;
BA_ "GenSigSendType" SG_ 1182 CstmzStat_CBDA_Sens_GUI 3;
BA_ "GenSigSendType" SG_ 1182 CstmzStat_CBDA_ONOFF_GUI 3;
BA_ "GenSigSendType" SG_ 1182 CstmzStat_TSR_Warn_GUI_SignBz 3;
BA_ "GenSigSendType" SG_ 1182 CstmzStat_TSR_Warn_GUI_Sign 3;
BA_ "GenSigSendType" SG_ 1182 CstmzStat_TSR_Warn_GUI_OFF 3;
BA_ "GenSigSendType" SG_ 1182 CstmzStat_LDW_ELK_Warn_GUI 3;
BA_ "GenSigSendType" SG_ 1182 CstmzStat_BSM_Sens_GUI 3;
BA_ "GenSigSendType" SG_ 1182 CstmzStat_BSM_ONOFF_GUI 3;
BA_ "GenSigSendType" SG_ 1182 CstmzStat_LDW_ONOFF_GUI 3;
BA_ "GenSigSendType" SG_ 1182 CstmzStat_RCTA_ONOFF_GUI 3;
BA_ "GenSigSendType" SG_ 1182 CstmzStat_FCTA_Sens_GUI 3;
BA_ "GenSigSendType" SG_ 1182 CstmzStat_FCTA_ONOFF_GUI 3;
BA_ "GenSigSendType" SG_ 1182 CstmzStat_TSRWarnThres_GUI_10 3;
BA_ "GenSigSendType" SG_ 1182 CstmzStat_TSRWarnThres_GUI_5 3;
BA_ "GenSigSendType" SG_ 1182 CstmzStat_TSRWarnThres_GUI_3 3;
BA_ "GenSigSendType" SG_ 1182 CstmzStat_TSRWarnThres_GUI_0 3;
BA_ "GenSigSendType" SG_ 1182 CstmzStat_TSR_Change_GUI 3;
BA_ "GenSigSendType" SG_ 1182 CstmzStat_TSR_NextInfo_GUI 3;
BA_ "GenSigSendType" SG_ 1182 CstmzStat_TSR_ONOFF_GUI 3;
BA_ "GenSigSendType" SG_ 1182 CstmzStat_ISA_TSR_ADJST_GUI 3;
BA_ "GenSigSendType" SG_ 1182 CstmzStat_IACC_TSR_ADJST_GUI 3;
BA_ "GenSigSendType" SG_ 1182 CstmzStat_MRCC_TSR_Mode_GUI 3;
BA_ "GenSigSendType" SG_ 1182 CstmzStat_MRCC_ASC_Mode_GUI 3;
BA_ "GenSigSendType" SG_ 1170 CstmzStat_RCD_ONOFF 3;
BA_ "GenSigSendType" SG_ 1170 CstmzStat_TAP_ALERT_ONOFF 3;
BA_ "GenSigSendType" SG_ 1170 CstmzStat_APS_RPC_DISTANCE 3;
BA_ "GenSigSendType" SG_ 1170 CstmzStat_PK_TrvB_EndP 3;
BA_ "GenSigSendType" SG_ 1170 CstmzStat_PK_TrvF_EndP 3;
BA_ "GenSigSendType" SG_ 1170 CstmzStat_PK_VehBLen 3;
BA_ "GenSigSendType" SG_ 1170 CstmzStat_PKout_View 3;
BA_ "GenSigSendType" SG_ 1170 CstmzStat_PKin_View 3;
BA_ "GenSigSendType" SG_ 1170 CstmzStat_PKout_PallalelDir 3;
BA_ "GenSigSendType" SG_ 1170 CstmzStat_PKout_CrossDir 3;
BA_ "GenSigSendType" SG_ 1170 CstmzStat_PK_Rd_Wid 3;
BA_ "GenSigSendType" SG_ 1170 CstmzStat_PK_Trv_Line 3;
BA_ "GenSigSendType" SG_ 1170 CstmzStat_PK_Veh_Dir 3;
BA_ "GenSigSendType" SG_ 1170 CstmzStat_APVSPD_LVL 3;
BA_ "GenSigSendType" SG_ 1170 CstmzStat_GUIDE_ONOFF 3;
BA_ "GenSigSendType" SG_ 1170 CstmzStat_RPC_ONOFF 3;
BA_ "GenSigSendType" SG_ 1170 CstmzStat_ACC_GCR_ONOFF 3;
BA_ "GenSigSendType" SG_ 1170 CstmzStat_ACC_ACCL_Sens 3;
BA_ "GenSigSendType" SG_ 1170 CstmzStat_ACC_CURVE_Sens 3;
BA_ "GenSigSendType" SG_ 1170 CstmzStat_ACC_OVTK_ONOFF 3;
BA_ "GenSigSendType" SG_ 1170 CstmzStat_TMN_LV_Sens 3;
BA_ "GenSigSendType" SG_ 1170 CstmzStat_TMN_TS_Sens 3;
BA_ "GenSigSendType" SG_ 1170 CstmzStat_LCA_ONOFF 3;
BA_ "GenSigSendType" SG_ 1170 CstmzStat_HOF_REC_ONOFF 3;
BA_ "GenSigSendType" SG_ 1170 CstmzStat_HOF_ONOFF 3;
BA_ "GenSigSendType" SG_ 1170 CstmzStat_ESA_AES_ONOFF 3;
BA_ "GenSigSendType" SG_ 1170 CstmzStat_PDA_Sens 3;
BA_ "GenSigSendType" SG_ 1170 CstmzStat_PDA_ONOFF 3;
BA_ "GenSigSendType" SG_ 1170 CstmzStat_TVM_MOAAuto_ONOFF 3;
BA_ "GenSigSendType" SG_ 1170 CstmzStat_TVM_MOA_ONOFF 3;
BA_ "GenSigSendType" SG_ 1170 CstmzStat_TVM_AutoOFF_ONOFF 3;
BA_ "GenSigSendType" SG_ 1170 CstmzStat_TVM_PASRear_Sens 3;
BA_ "GenSigSendType" SG_ 1170 CstmzStat_TVM_PASFront_Sens 3;
BA_ "GenSigSendType" SG_ 1170 CstmzStat_TVM_PAS_ONOFF 3;
BA_ "GenSigSendType" SG_ 1170 PrsnlSys_Switch_ID_ADU_Res 3;
BA_ "GenSigSendType" SG_ 1170 CstmzStat_PAS_Vol 3;
BA_ "GenSigSendType" SG_ 1170 CstmzStat_PAS_ONOFF 3;
BA_ "GenSigSendType" SG_ 1170 CstmzStat_EDA_ONOFF 3;
BA_ "GenSigSendType" SG_ 1170 CstmzStat_EDA_Sleep_ONOFF 3;
BA_ "GenSigSendType" SG_ 1170 CstmzStat_DM_ONOFF 3;
BA_ "GenSigSendType" SG_ 1170 CstmzStat_OCP_ONOFF 3;
BA_ "GenSigSendType" SG_ 1170 CstmzStat_BSP_ONOFF 3;
BA_ "GenSigSendType" SG_ 1170 CstmzStat_RDP_ONOFF 3;
BA_ "GenSigSendType" SG_ 1170 CstmzStat_ELK_ONOFF 3;
BA_ "GenSigSendType" SG_ 1170 CstmzStat_RAEB_ONOFF 3;
BA_ "GenSigSendType" SG_ 1170 CstmzStat_HeadOn_ONOFF 3;
BA_ "GenSigSendType" SG_ 1170 CstmzStat_TAP_ONOFF 3;
BA_ "GenSigSendType" SG_ 1170 CstmzStat_CTB_ONOFF 3;
BA_ "GenSigSendType" SG_ 1170 CstmzStat_AEB_Vol 3;
BA_ "GenSigSendType" SG_ 1170 CstmzStat_FAEB_ONOFF 3;
BA_ "GenSigSendType" SG_ 1170 CstmzStat_LDP_ONOFF 3;
BA_ "GenSigSendType" SG_ 1170 CstmzStat_CBDA_Sens 3;
BA_ "GenSigSendType" SG_ 1170 CstmzStat_CBDA_ONOFF 3;
BA_ "GenSigSendType" SG_ 1170 CstmzStat_LDW_ELK_Warn 3;
BA_ "GenSigSendType" SG_ 1170 CstmzStat_BSM_Sens 3;
BA_ "GenSigSendType" SG_ 1170 CstmzStat_BSM_ONOFF 3;
BA_ "GenSigSendType" SG_ 1170 CstmzStat_LDW_ONOFF 3;
BA_ "GenSigSendType" SG_ 1170 CstmzStat_RCTA_ONOFF 3;
BA_ "GenSigSendType" SG_ 1170 CstmzStat_FCTA_Sens 3;
BA_ "GenSigSendType" SG_ 1170 CstmzStat_FCTA_ONOFF 3;
BA_ "GenSigSendType" SG_ 1170 CstmzStat_TSRWarnThres 3;
BA_ "GenSigSendType" SG_ 1170 CstmzStat_TSR_Warn 3;
BA_ "GenSigSendType" SG_ 1170 CstmzStat_TSR_Change 3;
BA_ "GenSigSendType" SG_ 1170 CstmzStat_TSR_NextInfo 3;
BA_ "GenSigSendType" SG_ 1170 CstmzStat_TSR_ONOFF 3;
BA_ "GenSigSendType" SG_ 1170 CstmzStat_ISA_TSR_ADJST 3;
BA_ "GenSigSendType" SG_ 1170 CstmzStat_IACC_TSR_ADJST 3;
BA_ "GenSigSendType" SG_ 1170 CstmzStat_MRCC_TSR_Mode 3;
BA_ "GenSigSendType" SG_ 1170 CstmzStat_MRCC_ASC_Mode 3;
BA_ "GenSigSendType" SG_ 1169 CstmzRsp_RCD_ONOFF 1;
BA_ "GenSigSendType" SG_ 1169 CstmzRsp_TAP_ALERT_ONOFF 1;
BA_ "GenSigSendType" SG_ 1169 CstmzRsp_APS_RPC_DISTANCE 1;
BA_ "GenSigSendType" SG_ 1169 CstmzRsp_PK_TrvB_EndP 1;
BA_ "GenSigSendType" SG_ 1169 CstmzRsp_PK_TrvF_EndP 1;
BA_ "GenSigSendType" SG_ 1169 CstmzRsp_PK_VehBLen 1;
BA_ "GenSigSendType" SG_ 1169 CstmzRsp_PKout_View 1;
BA_ "GenSigSendType" SG_ 1169 CstmzRsp_PKin_View 1;
BA_ "GenSigSendType" SG_ 1169 CstmzRsp_PKout_PallalelDir 1;
BA_ "GenSigSendType" SG_ 1169 CstmzRsp_PKout_CrossDir 1;
BA_ "GenSigSendType" SG_ 1169 CstmzRsp_PK_Rd_Wid 1;
BA_ "GenSigSendType" SG_ 1169 CstmzRsp_PK_Trv_Line 1;
BA_ "GenSigSendType" SG_ 1169 CstmzRsp_PK_Veh_Dir 1;
BA_ "GenSigSendType" SG_ 1169 CstmzRsp_APVSPD_LVL 1;
BA_ "GenSigSendType" SG_ 1169 CstmzRsp_GUIDE_ONOFF 1;
BA_ "GenSigSendType" SG_ 1169 CstmzRsp_RPC_ONOFF 1;
BA_ "GenSigSendType" SG_ 1169 CstmzRsp_Status_VRsp04 1;
BA_ "GenSigSendType" SG_ 1169 CstmzRsp_Contents_VRsp04 1;
BA_ "GenSigSendType" SG_ 1169 CstmzRsp_ACC_GCR_ONOFF 1;
BA_ "GenSigSendType" SG_ 1169 CstmzRsp_ACC_ACCL_Sens 1;
BA_ "GenSigSendType" SG_ 1169 CstmzRsp_ACC_CURVE_Sens 1;
BA_ "GenSigSendType" SG_ 1169 CstmzRsp_ACC_OVTK_ONOFF 1;
BA_ "GenSigSendType" SG_ 1169 CstmzRsp_TMN_LV_Sens 1;
BA_ "GenSigSendType" SG_ 1169 CstmzRsp_TMN_TS_Sens 1;
BA_ "GenSigSendType" SG_ 1169 CstmzRsp_LCA_ONOFF 1;
BA_ "GenSigSendType" SG_ 1169 CstmzRsp_HOF_REC_ONOFF 1;
BA_ "GenSigSendType" SG_ 1169 CstmzRsp_HOF_ONOFF 1;
BA_ "GenSigSendType" SG_ 1169 CstmzRsp_ESA_AES_ONOFF 1;
BA_ "GenSigSendType" SG_ 1169 CstmzRsp_PDA_Sens 1;
BA_ "GenSigSendType" SG_ 1169 CstmzRsp_PDA_ONOFF 1;
BA_ "GenSigSendType" SG_ 1169 CstmzRsp_TVM_MOAAuto_ONOFF 1;
BA_ "GenSigSendType" SG_ 1169 CstmzRsp_TVM_MOA_ONOFF 1;
BA_ "GenSigSendType" SG_ 1169 CstmzRsp_TVM_AutoOFF_ONOFF 1;
BA_ "GenSigSendType" SG_ 1169 CstmzRsp_TVM_PASRear_Sens 1;
BA_ "GenSigSendType" SG_ 1169 CstmzRsp_TVM_PASFront_Sens 1;
BA_ "GenSigSendType" SG_ 1169 CstmzRsp_TVM_PAS_ONOFF 1;
BA_ "GenSigSendType" SG_ 1169 CstmzRsp_Status_VRsp03 1;
BA_ "GenSigSendType" SG_ 1169 CstmzRsp_Contents_VRsp03 1;
BA_ "GenSigSendType" SG_ 1169 CstmzRsp_Init_ALL_ADAS_Prsnl 1;
BA_ "GenSigSendType" SG_ 1169 CstmzRsp_PAS_Vol 1;
BA_ "GenSigSendType" SG_ 1169 CstmzRsp_PAS_ONOFF 1;
BA_ "GenSigSendType" SG_ 1169 CstmzRsp_EDA_ONOFF 1;
BA_ "GenSigSendType" SG_ 1169 CstmzRsp_EDA_Sleep_ONOFF 1;
BA_ "GenSigSendType" SG_ 1169 CstmzRsp_DM_ONOFF 1;
BA_ "GenSigSendType" SG_ 1169 CstmzRsp_OCP_ONOFF 1;
BA_ "GenSigSendType" SG_ 1169 CstmzRsp_BSP_ONOFF 1;
BA_ "GenSigSendType" SG_ 1169 CstmzRsp_RDP_ONOFF 1;
BA_ "GenSigSendType" SG_ 1169 CstmzRsp_ELK_ONOFF 1;
BA_ "GenSigSendType" SG_ 1169 CstmzRsp_RAEB_ONOFF 1;
BA_ "GenSigSendType" SG_ 1169 CstmzRsp_HeadOn_ONOFF 1;
BA_ "GenSigSendType" SG_ 1169 CstmzRsp_TAP_ONOFF 1;
BA_ "GenSigSendType" SG_ 1169 CstmzRsp_CTB_ONOFF 1;
BA_ "GenSigSendType" SG_ 1169 CstmzRsp_AEB_Vol 1;
BA_ "GenSigSendType" SG_ 1169 CstmzRsp_FAEB_ONOFF 1;
BA_ "GenSigSendType" SG_ 1169 CstmzRsp_LDP_ONOFF 1;
BA_ "GenSigSendType" SG_ 1169 CstmzRsp_CBDA_Sens 1;
BA_ "GenSigSendType" SG_ 1169 CstmzRsp_CBDA_ONOFF 1;
BA_ "GenSigSendType" SG_ 1169 CstmzRsp_Status_VRsp02 1;
BA_ "GenSigSendType" SG_ 1169 CstmzRsp_Contents_VRsp02 1;
BA_ "GenSigSendType" SG_ 1169 CstmzRsp_Init_ALL_ADAS 1;
BA_ "GenSigSendType" SG_ 1169 CstmzRsp_LDW_ELK_Warn 1;
BA_ "GenSigSendType" SG_ 1169 CstmzRsp_BSM_Sens 1;
BA_ "GenSigSendType" SG_ 1169 CstmzRsp_BSM_ONOFF 1;
BA_ "GenSigSendType" SG_ 1169 CstmzRsp_LDW_ONOFF 1;
BA_ "GenSigSendType" SG_ 1169 CstmzRsp_RCTA_ONOFF 1;
BA_ "GenSigSendType" SG_ 1169 CstmzRsp_FCTA_Sens 1;
BA_ "GenSigSendType" SG_ 1169 CstmzRsp_FCTA_ONOFF 1;
BA_ "GenSigSendType" SG_ 1169 CstmzRsp_TSRWarnThres 1;
BA_ "GenSigSendType" SG_ 1169 CstmzRsp_TSR_Warn 1;
BA_ "GenSigSendType" SG_ 1169 CstmzRsp_TSR_Change 1;
BA_ "GenSigSendType" SG_ 1169 CstmzRsp_TSR_NextInfo 1;
BA_ "GenSigSendType" SG_ 1169 CstmzRsp_TSR_ONOFF 1;
BA_ "GenSigSendType" SG_ 1169 CstmzRsp_ISA_TSR_ADJST 1;
BA_ "GenSigSendType" SG_ 1169 CstmzRsp_IACC_TSR_ADJST 1;
BA_ "GenSigSendType" SG_ 1169 CstmzRsp_MRCC_TSR_Mode 1;
BA_ "GenSigSendType" SG_ 1169 CstmzRsp_MRCC_ASC_Mode 1;
BA_ "GenSigSendType" SG_ 1169 CstmzRsp_Status_VRsp01 1;
BA_ "GenSigSendType" SG_ 1169 CstmzRsp_Contents_VRsp01 1;
BA_ "GenSigSendType" SG_ 1168 CstmzRq_RCD_ONOFF 1;
BA_ "GenSigSendType" SG_ 1168 CstmzRq_TAP_ALERT_ONOFF 1;
BA_ "GenSigSendType" SG_ 1168 CstmzRq_APS_RPC_DISTANCE 3;
BA_ "GenSigSendType" SG_ 1168 CstmzRq_PK_TrvB_EndP 1;
BA_ "GenSigSendType" SG_ 1168 CstmzRq_PK_TrvF_EndP 1;
BA_ "GenSigSendType" SG_ 1168 CstmzRq_PK_VehBLen 1;
BA_ "GenSigSendType" SG_ 1168 CstmzRq_PKout_View 1;
BA_ "GenSigSendType" SG_ 1168 CstmzRq_PKin_View 1;
BA_ "GenSigSendType" SG_ 1168 CstmzRq_PKout_PallalelDir 1;
BA_ "GenSigSendType" SG_ 1168 CstmzRq_PKout_CrossDir 1;
BA_ "GenSigSendType" SG_ 1168 CstmzRq_PK_Rd_Wid 1;
BA_ "GenSigSendType" SG_ 1168 CstmzRq_PK_Trv_Line 1;
BA_ "GenSigSendType" SG_ 1168 CstmzRq_PK_Veh_Dir 1;
BA_ "GenSigSendType" SG_ 1168 CstmzRq_APVSPD_LVL 1;
BA_ "GenSigSendType" SG_ 1168 CstmzRq_GUIDE_ONOFF 1;
BA_ "GenSigSendType" SG_ 1168 CstmzRq_RPC_ONOFF 1;
BA_ "GenSigSendType" SG_ 1168 CstmzRq_Contents_VRq04 1;
BA_ "GenSigSendType" SG_ 1168 CstmzRq_ACC_GCR_ONOFF 1;
BA_ "GenSigSendType" SG_ 1168 CstmzRq_ACC_ACCL_Sens 1;
BA_ "GenSigSendType" SG_ 1168 CstmzRq_ACC_CURVE_Sens 1;
BA_ "GenSigSendType" SG_ 1168 CstmzRq_ACC_OVTK_ONOFF 1;
BA_ "GenSigSendType" SG_ 1168 CstmzRq_TMN_LV_Sens 1;
BA_ "GenSigSendType" SG_ 1168 CstmzRq_TMN_TS_Sens 1;
BA_ "GenSigSendType" SG_ 1168 CstmzRq_LCA_ONOFF 1;
BA_ "GenSigSendType" SG_ 1168 CstmzRq_HOF_REC_ONOFF 1;
BA_ "GenSigSendType" SG_ 1168 CstmzRq_HOF_ONOFF 1;
BA_ "GenSigSendType" SG_ 1168 CstmzRq_ESA_AES_ONOFF 1;
BA_ "GenSigSendType" SG_ 1168 CstmzRq_PDA_Sens 1;
BA_ "GenSigSendType" SG_ 1168 CstmzRq_PDA_ONOFF 1;
BA_ "GenSigSendType" SG_ 1168 CstmzRq_TVM_MOAAuto_ONOFF 1;
BA_ "GenSigSendType" SG_ 1168 CstmzRq_TVM_MOA_ONOFF 1;
BA_ "GenSigSendType" SG_ 1168 CstmzRq_TVM_AutoOFF_ONOFF 1;
BA_ "GenSigSendType" SG_ 1168 CstmzRq_TVM_PASRear_Sens 1;
BA_ "GenSigSendType" SG_ 1168 CstmzRq_TVM_PASFront_Sens 1;
BA_ "GenSigSendType" SG_ 1168 CstmzRq_TVM_PAS_ONOFF 1;
BA_ "GenSigSendType" SG_ 1168 CstmzRq_Contents_VRq03 1;
BA_ "GenSigSendType" SG_ 1168 CstmzRq_Init_ALL_ADAS_Prsnl 1;
BA_ "GenSigSendType" SG_ 1168 CstmzRq_PAS_Vol 1;
BA_ "GenSigSendType" SG_ 1168 CstmzRq_PAS_ONOFF 1;
BA_ "GenSigSendType" SG_ 1168 CstmzRq_EDA_ONOFF 1;
BA_ "GenSigSendType" SG_ 1168 CstmzRq_EDA_Sleep_ONOFF 1;
BA_ "GenSigSendType" SG_ 1168 CstmzRq_DM_ONOFF 1;
BA_ "GenSigSendType" SG_ 1168 CstmzRq_OCP_ONOFF 1;
BA_ "GenSigSendType" SG_ 1168 CstmzRq_BSP_ONOFF 1;
BA_ "GenSigSendType" SG_ 1168 CstmzRq_RDP_ONOFF 1;
BA_ "GenSigSendType" SG_ 1168 CstmzRq_ELK_ONOFF 1;
BA_ "GenSigSendType" SG_ 1168 CstmzRq_RAEB_ONOFF 1;
BA_ "GenSigSendType" SG_ 1168 CstmzRq_HeadOn_ONOFF 1;
BA_ "GenSigSendType" SG_ 1168 CstmzRq_TAP_ONOFF 1;
BA_ "GenSigSendType" SG_ 1168 CstmzRq_CTB_ONOFF 1;
BA_ "GenSigSendType" SG_ 1168 CstmzRq_AEB_Vol 1;
BA_ "GenSigSendType" SG_ 1168 CstmzRq_FAEB_ONOFF 1;
BA_ "GenSigSendType" SG_ 1168 CstmzRq_LDP_ONOFF 1;
BA_ "GenSigSendType" SG_ 1168 CstmzRq_CBDA_Sens 1;
BA_ "GenSigSendType" SG_ 1168 CstmzRq_CBDA_ONOFF 1;
BA_ "GenSigSendType" SG_ 1168 CstmzRq_Contents_VRq02 1;
BA_ "GenSigSendType" SG_ 1168 CstmzRq_Init_ALL_ADAS 1;
BA_ "GenSigSendType" SG_ 1168 CstmzRq_LDW_ELK_Warn 1;
BA_ "GenSigSendType" SG_ 1168 CstmzRq_BSM_Sens 1;
BA_ "GenSigSendType" SG_ 1168 CstmzRq_BSM_ONOFF 1;
BA_ "GenSigSendType" SG_ 1168 CstmzRq_LDW_ONOFF 1;
BA_ "GenSigSendType" SG_ 1168 CstmzRq_RCTA_ONOFF 1;
BA_ "GenSigSendType" SG_ 1168 CstmzRq_FCTA_Sens 1;
BA_ "GenSigSendType" SG_ 1168 CstmzRq_FCTA_ONOFF 1;
BA_ "GenSigSendType" SG_ 1168 CstmzRq_TSRWarnThres 1;
BA_ "GenSigSendType" SG_ 1168 CstmzRq_TSR_Warn 1;
BA_ "GenSigSendType" SG_ 1168 CstmzRq_TSR_Change 1;
BA_ "GenSigSendType" SG_ 1168 CstmzRq_TSR_NextInfo 1;
BA_ "GenSigSendType" SG_ 1168 CstmzRq_TSR_ONOFF 1;
BA_ "GenSigSendType" SG_ 1168 CstmzRq_ISA_TSR_ADJST 1;
BA_ "GenSigSendType" SG_ 1168 CstmzRq_IACC_TSR_ADJST 1;
BA_ "GenSigSendType" SG_ 1168 CstmzRq_MRCC_TSR_Mode 1;
BA_ "GenSigSendType" SG_ 1168 CstmzRq_MRCC_ASC_Mode 1;
BA_ "GenSigSendType" SG_ 1168 CstmzRq_Contents_VRq01 1;
BA_ "GenSigSendType" SG_ 1166 Delete_KeyfobDpos_State 3;
BA_ "GenSigSendType" SG_ 1166 Record_KeyfobDpos_State 3;
BA_ "GenSigSendType" SG_ 1166 PrsnlDpos_StorageState 3;
BA_ "GenSigSendType" SG_ 1166 KeyfobDpos_StorageState 3;
BA_ "GenSigSendType" SG_ 1166 Mem2Dpos_StorageState 3;
BA_ "GenSigSendType" SG_ 1166 Mem1Dpos_StorageState 3;
BA_ "GenSigSendType" SG_ 1166 PrsnlSys_Switch_ID_ADU_Req 3;
BA_ "GenSigSendType" SG_ 1166 PrsnlSys_State3 3;
BA_ "GenSigSendType" SG_ 1166 PrsnlSys_IDDB_State 3;
BA_ "GenSigSendType" SG_ 1166 Recall_Dpos_State 3;
BA_ "GenSigSendType" SG_ 1166 AutoDpos_State 3;
BA_ "GenSigSendType" SG_ 1166 Key_Variants 3;
BA_ "GenSigSendType" SG_ 1166 PrsnlSys_Transition_Prohibit 3;
BA_ "GenSigSendType" SG_ 1166 PrsnlSys_Switch_ID_CDC_Req 3;
BA_ "GenSigSendType" SG_ 1166 PrsnlSys_ID_State 3;
BA_ "GenSigSendType" SG_ 1166 PrsnlSys_ID6_Regist_State 3;
BA_ "GenSigSendType" SG_ 1166 PrsnlSys_ID5_Regist_State 3;
BA_ "GenSigSendType" SG_ 1166 PrsnlSys_ID4_Regist_State 3;
BA_ "GenSigSendType" SG_ 1166 PrsnlSys_ID3_Regist_State 3;
BA_ "GenSigSendType" SG_ 1166 PrsnlSys_ID2_Regist_State 3;
BA_ "GenSigSendType" SG_ 1166 PrsnlSys_ID1_Regist_State 3;
BA_ "GenSigSendType" SG_ 1166 PrsnlSys_State2 3;
BA_ "GenSigSendType" SG_ 1166 PrsnlSys_State1 3;
BA_ "GenSigSendType" SG_ 1157 TotalISTime 3;
BA_ "GenSigSendType" SG_ 1157 Drv1IstpTm 3;
BA_ "GenSigSendType" SG_ 1157 Set_Prsnl_DriverNo 3;
BA_ "GenSigSendType" SG_ 1157 Set_Prsnl_Enable 3;
BA_ "GenSigSendType" SG_ 1157 Set_TPMSUnit 3;
BA_ "GenSigSendType" SG_ 1157 Set_FuelUnit 3;
BA_ "GenSigSendType" SG_ 1157 Set_DistncUnit 3;
BA_ "GenSigTimeoutTime_ADU" SG_ 1157 Set_DistncUnit 1500;
BA_ "GenSigSendType" SG_ 1157 Set_TempUnit 3;
BA_ "GenSigSendType" SG_ 1157 Set_DispChrt 3;
BA_ "GenSigSendType" SG_ 1154 CstmzStat_Facial_Iden_OnOff 3;
BA_ "GenSigSendType" SG_ 1154 CstmzStat_Towing_Wt 3;
BA_ "GenSigSendType" SG_ 1154 CstmzStat_AirCon_Auto_AImode_CO2 3;
BA_ "GenSigSendType" SG_ 1154 CstmzStat_AirCon_Auto_AImode 3;
BA_ "GenSigSendType" SG_ 1154 CstmzStat_AirCon_Auto_BlwLv 3;
BA_ "GenSigSendType" SG_ 1154 CstmzStat_AC_Auto_wStrHeatLv 3;
BA_ "GenSigSendType" SG_ 1154 CstmzStat_AC_Auto_wSeatVentLv_Ps 3;
BA_ "GenSigSendType" SG_ 1154 CstmzStat_AC_Auto_wSeatHeatLv_Ps 3;
BA_ "GenSigSendType" SG_ 1154 CstmzStat_AC_Auto_wSeatVentLv_Dr 3;
BA_ "GenSigSendType" SG_ 1154 CstmzStat_AC_Auto_wSeatHeatLv_Dr 3;
BA_ "GenSigSendType" SG_ 1154 CstmzStat_RSRmid_GUI_InandEx 3;
BA_ "GenSigSendType" SG_ 1154 CstmzStat_RSRmid_GUI_In 3;
BA_ "GenSigSendType" SG_ 1154 CstmzStat_RSRmid_GUI_Off 3;
BA_ "GenSigSendType" SG_ 1154 CstmzStat_RSRmid 3;
BA_ "GenSigSendType" SG_ 1154 CstmzStat_Regen_Select_Rq 3;
BA_ "GenSigSendType" SG_ 1154 CstmzStat_Charge_TgtSoc_Rq 3;
BA_ "GenSigSendType" SG_ 1154 CstmzStat_Ev_Default_Rq 3;
BA_ "GenSigSendType" SG_ 1154 CstmzStat_FullSOC_AC 3;
BA_ "GenSigSendType" SG_ 1154 CstmzStat_FullSOC_QBC 3;
BA_ "GenSigSendType" SG_ 1154 CstmzStat_SupplyStopSOC 3;
BA_ "GenSigSendType" SG_ 1154 CstmzStat_ConnectorLockReq 3;
BA_ "GenSigSendType" SG_ 1154 CstmzStat_BatHeat_AutoSW 3;
BA_ "GenSigSendType" SG_ 1154 CstmzStat_AirCon_Auto_wStrHeat 3;
BA_ "GenSigSendType" SG_ 1154 CstmzStat_AirCon_Auto_wSeat_Ps 3;
BA_ "GenSigSendType" SG_ 1154 CstmzStat_AirCon_Auto_wSeat_Dr 3;
BA_ "GenSigSendType" SG_ 1154 CstmzStat_Prsnl_OnOff 3;
BA_ "GenSigSendType" SG_ 1154 CstmzStat_CHG_W_FreqShiftOnOff 3;
BA_ "GenSigSendType" SG_ 1154 CstmzStat_CHG_W_OnOff 3;
BA_ "GenSigSendType" SG_ 1154 CstmzStat_Hud_RotatLvl 3;
BA_ "GenSigSendType" SG_ 1154 CstmzStat_Hud_TiltLvl 3;
BA_ "GenSigSendType" SG_ 1154 CstmzStat_Hud_OnOff 3;
BA_ "GenSigSendType" SG_ 1154 CstmzStat_ALH_ONOFF_GUI_ON_w_M 3;
BA_ "GenSigSendType" SG_ 1154 CstmzStat_Paddle_Mde 3;
BA_ "GenSigSendType" SG_ 1154 CstmzStat_PLG_Handsfree_OnOff 3;
BA_ "GenSigSendType" SG_ 1154 CstmzStat_PLG_Open_Keylock_Mde 3;
BA_ "GenSigSendType" SG_ 1154 CstmzStat_FuelLckDelay_T 3;
BA_ "GenSigSendType" SG_ 1154 CstmzStat_Ind_Clr_OnOff 3;
BA_ "GenSigSendType" SG_ 1154 CstmzStat_Trip_Rst_Mde 3;
BA_ "GenSigSendType" SG_ 1154 CstmzStat_PedalWarning 3;
BA_ "GenSigSendType" SG_ 1154 CstmzStat_RidePos_Lvl 3;
BA_ "GenSigSendType" SG_ 1154 CstmzStat_DrvPos_OnOff 3;
BA_ "GenSigSendType" SG_ 1154 CstmzStat_Indrctillmntin_Lvl 3;
BA_ "GenSigSendType" SG_ 1154 CstmzStat_RmLmpOffDrClose_T 3;
BA_ "GenSigSendType" SG_ 1154 CstmzStat_LHL_OnOff 3;
BA_ "GenSigSendType" SG_ 1154 CstmzStat_CHL_T 3;
BA_ "GenSigSendType" SG_ 1154 CstmzStat_LightLeveling 3;
BA_ "GenSigSendType" SG_ 1154 CstmzStat_AFS_ONOFF 3;
BA_ "GenSigSendType" SG_ 1154 CstmzStat_HBC_ONOFF 3;
BA_ "GenSigSendType" SG_ 1154 CstmzStat_ALH_ONOFF 3;
BA_ "GenSigSendType" SG_ 1154 CstmzStat_DRL_OnOff 3;
BA_ "GenSigSendType" SG_ 1154 CstmzStat_AtLtOff_T 3;
BA_ "GenSigSendType" SG_ 1154 CstmzStat_AutoLight_Sens 3;
BA_ "GenSigSendType" SG_ 1154 CstmzStat_AB_R_OnOff 3;
BA_ "GenSigSendType" SG_ 1154 CstmzStat_AB_P_OnOff 3;
BA_ "GenSigSendType" SG_ 1154 CstmzStat_AirCon_Cooperation 3;
BA_ "GenSigSendType" SG_ 1154 CstmzStat_RearDef_T 3;
BA_ "GenSigSendType" SG_ 1154 CstmzStat_SmtTrn_OnOff 3;
BA_ "GenSigSendType" SG_ 1154 CstmzStat_AtStorageMirror_OnOff 3;
BA_ "GenSigSendType" SG_ 1154 CstmzStat_AtWpr_OnOff 3;
BA_ "GenSigSendType" SG_ 1154 CstmzStat_KylssChm_Vol 3;
BA_ "GenSigSendType" SG_ 1154 CstmzStat_KylssWal_OnOff 3;
BA_ "GenSigSendType" SG_ 1154 CstmzStat_KylssUnlck_Mde 3;
BA_ "GenSigSendType" SG_ 1154 CstmzStat_KylssAtLck_T 3;
BA_ "GenSigSendType" SG_ 1154 CstmzStat_AtDrLck_Mde_MT 3;
BA_ "GenSigSendType" SG_ 1154 CstmzStat_AtDrLck_Mde_AT 3;
BA_ "GenSigSendType" SG_ 1154 CstmzStat_Prsnl_DriverNo 3;
BA_ "GenSigSendType" SG_ 1154 CstmzStat_Prsnl_Enable 3;
BA_ "GenSigSendType" SG_ 1154 CstmzStat_TPMSUnit 3;
BA_ "GenSigSendType" SG_ 1154 CstmzStat_FuelUnit 3;
BA_ "GenSigSendType" SG_ 1154 CstmzStat_DistncUnit 3;
BA_ "GenSigSendType" SG_ 1154 CstmzStat_TempUnit 3;
BA_ "GenSigSendType" SG_ 1154 CstmzStat_DispChrt 3;
BA_ "GenSigSendType" SG_ 1148 ID47C_No_Cs 3;
BA_ "GenSigSendType" SG_ 1148 ID47C_No_Cnt 3;
BA_ "GenSigSendType" SG_ 1148 NEMIN_AP 3;
BA_ "GenSigSendType" SG_ 1148 APPME 3;
BA_ "GenSigSendType" SG_ 1148 IPAVOICE 3;
BA_ "GenSigSendType" SG_ 1148 APWNKON 3;
BA_ "GenSigSendType" SG_ 1148 AP_HRNRQ 3;
BA_ "GenSigSendType" SG_ 1148 VNUSGAPP 3;
BA_ "GenSigSendType" SG_ 1148 IPAV_EXT 3;
BA_ "GenSigSendType" SG_ 1148 IPAVSYNC 3;
BA_ "GenSigSendType" SG_ 1148 IPAR_EXT 3;
BA_ "GenSigSendType" SG_ 1148 IPARSYNC 3;
BA_ "GenSigStartValue" SG_ 1148 IPARSYNC 1;
BA_ "GenSigSendType" SG_ 1148 IPAINFO2 3;
BA_ "GenSigSendType" SG_ 1148 IPA_DIST 3;
BA_ "GenSigSendType" SG_ 1148 CAREQ_AP 3;
BA_ "GenSigSendType" SG_ 1148 IPA_BZ2 3;
BA_ "GenSigSendType" SG_ 1147 PMARAVBL 3;
BA_ "GenSigSendType" SG_ 1147 VOT3 3;
BA_ "GenSigSendType" SG_ 1147 PMARVNEX 3;
BA_ "GenSigSendType" SG_ 1147 PMARVNRQ 3;
BA_ "GenSigSendType" SG_ 1147 PMARDISP 3;
BA_ "GenSigSendType" SG_ 1147 VNUSGCSR 3;
BA_ "GenSigSendType" SG_ 1147 WACSPMID 3;
BA_ "GenSigSendType" SG_ 1147 WACS_BUZ 3;
BA_ "GenSigSendType" SG_ 1147 ICSINFO 3;
BA_ "GenSigSendType" SG_ 1147 ICSLAMP 3;
BA_ "GenSigSendType" SG_ 1147 ICSEXIST 3;
BA_ "GenSigSendType" SG_ 1146 C_AHB 3;
BA_ "GenSigSendType" SG_ 1146 F_AHB 3;
BA_ "GenSigSendType" SG_ 1146 AHB_DUTY 3;
BA_ "GenSigSendType" SG_ 1146 HL_SYINF 3;
BA_ "GenSigSendType" SG_ 1146 HEDH_AZB 3;
BA_ "GenSigSendType" SG_ 1145 LTABZR 3;
BA_ "GenSigSendType" SG_ 1145 STRCTLD 3;
BA_ "GenSigSendType" SG_ 1145 HOFSMSG 3;
BA_ "GenSigSendType" SG_ 1145 LKAWLSR 3;
BA_ "GenSigSendType" SG_ 1145 LKAWLSL 3;
BA_ "GenSigSendType" SG_ 1145 LKACB 3;
BA_ "GenSigSendType" SG_ 1145 LDWBUZ 3;
BA_ "GenSigSendType" SG_ 1145 CSFBUZ 3;
BA_ "GenSigSendType" SG_ 1145 LTAMSG 3;
BA_ "GenSigSendType" SG_ 1145 LDAMSG 3;
BA_ "GenSigSendType" SG_ 1145 LDOFINDI 3;
BA_ "GenSigSendType" SG_ 1145 LTAINDI 3;
BA_ "GenSigSendType" SG_ 1145 LDAINDI 3;
BA_ "GenSigSendType" SG_ 1144 FSSINFO 3;
BA_ "GenSigSendType" SG_ 1144 PCSPWUCT 3;
BA_ "GenSigSendType" SG_ 1144 PCSCAUST 3;
BA_ "GenSigSendType" SG_ 1144 TSS_TS 3;
BA_ "GenSigSendType" SG_ 1144 PCSTUNA2 3;
BA_ "GenSigSendType" SG_ 1144 PCSDUST2 3;
BA_ "GenSigSendType" SG_ 1144 PCTEMP2 3;
BA_ "GenSigSendType" SG_ 1144 PCSLCCK 3;
BA_ "GenSigSendType" SG_ 1144 PCSDUST 3;
BA_ "GenSigSendType" SG_ 1144 PCSTEMP 3;
BA_ "GenSigSendType" SG_ 1144 PCSDSRF 3;
BA_ "GenSigSendType" SG_ 1144 PCSDW 3;
BA_ "GenSigSendType" SG_ 1144 PCSMTBZ2 3;
BA_ "GenSigSendType" SG_ 1144 PCSWD 3;
BA_ "GenSigSendType" SG_ 1144 PCSWDUCT 3;
BA_ "GenSigSendType" SG_ 1144 PCSTUNA 3;
BA_ "GenSigSendType" SG_ 1144 PBTUCT 3;
BA_ "GenSigSendType" SG_ 1144 DS1LCCK 3;
BA_ "GenSigSendType" SG_ 1144 PCSTUCT 3;
BA_ "GenSigSendType" SG_ 1144 PCSFCT 3;
BA_ "GenSigSendType" SG_ 1144 PCSWM 3;
BA_ "GenSigSendType" SG_ 1144 PCSINDI 3;
BA_ "GenSigStartValue" SG_ 1125 GMT_Second_ByGPS 255;
BA_ "GenSigInvalidValue" SG_ 1125 GMT_Second_ByGPS 255;
BA_ "GenSigStartValue" SG_ 1125 GMT_Minutes_ByGPS 255;
BA_ "GenSigInvalidValue" SG_ 1125 GMT_Minutes_ByGPS 255;
BA_ "GenSigStartValue" SG_ 1125 GMT_Hour_ByGPS 255;
BA_ "GenSigInvalidValue" SG_ 1125 GMT_Hour_ByGPS 255;
BA_ "GenSigStartValue" SG_ 1125 GMT_Date_ByGPS 255;
BA_ "GenSigInvalidValue" SG_ 1125 GMT_Date_ByGPS 255;
BA_ "GenSigStartValue" SG_ 1125 GMT_Month_ByGPS 255;
BA_ "GenSigInvalidValue" SG_ 1125 GMT_Month_ByGPS 255;
BA_ "GenSigStartValue" SG_ 1125 GMT_Year_ByGPS 255;
BA_ "GenSigInvalidValue" SG_ 1125 GMT_Year_ByGPS 255;
BA_ "GenSigStartValue" SG_ 1125 HorizonByGPS 4294967295;
BA_ "GenSigInvalidValue" SG_ 1125 HorizonByGPS 4294967295;
BA_ "GenSigStartValue" SG_ 1125 Curnt_Second_ByGPS 255;
BA_ "GenSigInvalidValue" SG_ 1125 Curnt_Second_ByGPS 255;
BA_ "GenSigStartValue" SG_ 1125 Curnt_Minutes_ByGPS 255;
BA_ "GenSigInvalidValue" SG_ 1125 Curnt_Minutes_ByGPS 255;
BA_ "GenSigStartValue" SG_ 1125 Curnt_Hour_ByGPS 255;
BA_ "GenSigInvalidValue" SG_ 1125 Curnt_Hour_ByGPS 255;
BA_ "GenSigStartValue" SG_ 1125 LongitudeByGPS 4294967295;
BA_ "GenSigInvalidValue" SG_ 1125 LongitudeByGPS 4294967295;
BA_ "GenSigStartValue" SG_ 1125 Curnt_Date_ByGPS 255;
BA_ "GenSigInvalidValue" SG_ 1125 Curnt_Date_ByGPS 255;
BA_ "GenSigStartValue" SG_ 1125 Curnt_Month_ByGPS 255;
BA_ "GenSigInvalidValue" SG_ 1125 Curnt_Month_ByGPS 255;
BA_ "GenSigStartValue" SG_ 1125 Curnt_Year_ByGPS 255;
BA_ "GenSigInvalidValue" SG_ 1125 Curnt_Year_ByGPS 255;
BA_ "GenSigStartValue" SG_ 1125 LatitudeByGPS 4294967295;
BA_ "GenSigInvalidValue" SG_ 1125 LatitudeByGPS 4294967295;
BA_ "GenSigInvalidValue" SG_ 1120 BackupBatteryMid_U_Actl 1023;
BA_ "GenSigSendType" SG_ 1120 DrLock_Message_R_Rsp 4;
BA_ "GenSigSendType" SG_ 1120 DrStatRl_B_Actl 4;
BA_ "GenSigTimeoutTime_ADU" SG_ 1120 DrStatRl_B_Actl 1500;
BA_ "GenSigSendType" SG_ 1120 DrStatR_D_Qf 4;
BA_ "GenSigStartValue" SG_ 1120 DrStatR_D_Qf 1;
BA_ "GenSigTimeoutTime_ADU" SG_ 1120 DrStatR_D_Qf 1500;
BA_ "GenSigSendType" SG_ 1120 TrnkLg_Motor_Stat 4;
BA_ "GenSigSendType" SG_ 1120 Fuel_Lid_Open_Status 4;
BA_ "GenSigSendType" SG_ 1120 StopLampCon_Status 4;
BA_ "GenSigTimeoutTime_ADU" SG_ 1120 StopLampCon_Status 1500;
BA_ "GenSigStartValue" SG_ 1120 SeatBeltStat_D_Actl 128;
BA_ "GenSigSendType" SG_ 1120 DrStatTrnkLg_B_Actl 4;
BA_ "GenSigTimeoutTime_ADU" SG_ 1120 DrStatTrnkLg_B_Actl 1500;
BA_ "GenSigSendType" SG_ 1120 ParkBrkActv_D_Actl2 4;
BA_ "GenSigSendType" SG_ 1120 AutoHoldSw_B_Actl 4;
BA_ "GenSigSendType" SG_ 1112 DrvrID_Request_Target 3;
BA_ "GenSigInvalidValue" SG_ 1112 DrvrID_Request_Target 15;
BA_ "GenSigSendType" SG_ 1112 Deletion_Cancel_Request 3;
BA_ "GenSigSendType" SG_ 1112 Deletion_Start_Request 3;
BA_ "GenSigSendType" SG_ 1112 Registration_Cancel_Request 3;
BA_ "GenSigSendType" SG_ 1112 Registration_Start_Request 3;
BA_ "GenSigSendType" SG_ 1112 Identification_Cancel_Request 3;
BA_ "GenSigSendType" SG_ 1112 Identification_Start_Request 3;
BA_ "GenSigSendType" SG_ 1109 VCU_rear 3;
BA_ "GenSigSendType" SG_ 1109 VCU_rearside 3;
BA_ "GenSigSendType" SG_ 1109 VCU_side 3;
BA_ "GenSigSendType" SG_ 1109 VCU_frontside 3;
BA_ "GenSigSendType" SG_ 1109 VCU_front 3;
BA_ "GenSigSendType" SG_ 1109 VCU_state 3;
BA_ "GenSigSendType" SG_ 1109 VCU_mute_State 3;
BA_ "GenSigSendType" SG_ 1109 DAS_state 3;
BA_ "GenSigSendType" SG_ 1109 OMC_Sensing_State 3;
BA_ "GenSigSendType" SG_ 1109 OMC_state 3;
BA_ "GenSigSendType" SG_ 1109 AMAP_state 3;
BA_ "GenSigSendType" SG_ 1109 V2X_state 3;
BA_ "GenSigSendType" SG_ 1109 VMC_state 3;
BA_ "GenSigSendType" SG_ 1109 SONAR_state12 3;
BA_ "GenSigSendType" SG_ 1109 SONAR_state11 3;
BA_ "GenSigSendType" SG_ 1109 SONAR_state10 3;
BA_ "GenSigSendType" SG_ 1109 SONAR_state9 3;
BA_ "GenSigSendType" SG_ 1109 SONAR_state8 3;
BA_ "GenSigSendType" SG_ 1109 SONAR_state7 3;
BA_ "GenSigSendType" SG_ 1109 SONAR_state6 3;
BA_ "GenSigSendType" SG_ 1109 SONAR_state5 3;
BA_ "GenSigSendType" SG_ 1109 SONAR_state4 3;
BA_ "GenSigSendType" SG_ 1109 SONAR_state3 3;
BA_ "GenSigSendType" SG_ 1109 SONAR_state2 3;
BA_ "GenSigSendType" SG_ 1109 SONAR_state1 3;
BA_ "GenSigSendType" SG_ 1109 SONAR_state 3;
BA_ "GenSigSendType" SG_ 1109 RSRDR_state 3;
BA_ "GenSigSendType" SG_ 1109 FSRDR_state 3;
BA_ "GenSigSendType" SG_ 1109 FRDR_state 3;
BA_ "GenSigSendType" SG_ 1109 FSC_state 3;
BA_ "GenSigSendType" SG_ 1109 REDKEY_state 3;
BA_ "GenSigSendType" SG_ 1108 LKA_handsfree 3;
BA_ "GenSigSendType" SG_ 1108 RMF_CMU_disp_select 3;
BA_ "GenSigSendType" SG_ 1108 EDA_cancel_timer 3;
BA_ "GenSigSendType" SG_ 1108 LKA_EV_RMF_cancel 3;
BA_ "GenSigSendType" SG_ 1108 EDA_EV_cancel 3;
BA_ "GenSigSendType" SG_ 1108 EDA_state 3;
BA_ "GenSigSendType" SG_ 1108 TVM_state 3;
BA_ "GenSigSendType" SG_ 1108 APS_RPC_state 3;
BA_ "GenSigSendType" SG_ 1108 HBC_high 3;
BA_ "GenSigSendType" SG_ 1108 HBC_state 3;
BA_ "GenSigSendType" SG_ 1108 ALH_high 3;
BA_ "GenSigSendType" SG_ 1108 ALH_state 3;
BA_ "GenSigSendType" SG_ 1108 DAA_state 3;
BA_ "GenSigSendType" SG_ 1108 DM_EV_time_intrvl_drowsy 3;
BA_ "GenSigSendType" SG_ 1108 DM_EV_engage_awake 3;
BA_ "GenSigSendType" SG_ 1108 DM_state 3;
BA_ "GenSigSendType" SG_ 1108 PAOBJ_BSM_rear_R_side_rel 3;
BA_ "GenSigSendType" SG_ 1108 PAOBJ_BSM_rear_R_side_Y 3;
BA_ "GenSigSendType" SG_ 1108 PAOBJ_BSM_rear_R_side_X 3;
BA_ "GenSigSendType" SG_ 1108 PAOBJ_BSM_R_side_rel 3;
BA_ "GenSigSendType" SG_ 1108 PAOBJ_BSM_R_side_Y 3;
BA_ "GenSigSendType" SG_ 1108 PAOBJ_BSM_R_side_X 3;
BA_ "GenSigSendType" SG_ 1108 PAOBJ_BSM_rear_L_side_rel 3;
BA_ "GenSigSendType" SG_ 1108 PAOBJ_BSM_rear_L_side_Y 3;
BA_ "GenSigSendType" SG_ 1108 PAOBJ_BSM_rear_L_side_X 3;
BA_ "GenSigSendType" SG_ 1108 PAOBJ_BSM_L_side_rel 3;
BA_ "GenSigSendType" SG_ 1108 PAOBJ_BSM_L_side_Y 3;
BA_ "GenSigSendType" SG_ 1108 PAOBJ_BSM_L_side_X 3;
BA_ "GenSigSendType" SG_ 1107 PAOBJ_LCA_rear_R_side_rel 3;
BA_ "GenSigSendType" SG_ 1107 PAOBJ_LCA_rear_R_side_Y 3;
BA_ "GenSigSendType" SG_ 1107 PAOBJ_LCA_rear_R_side_X 3;
BA_ "GenSigSendType" SG_ 1107 PAOBJ_LCA_R_side_rel 3;
BA_ "GenSigSendType" SG_ 1107 PAOBJ_LCA_R_side_Y 3;
BA_ "GenSigSendType" SG_ 1107 PAOBJ_LCA_R_side_X 3;
BA_ "GenSigSendType" SG_ 1107 PAOBJ_LCA_rear_L_side_rel 3;
BA_ "GenSigSendType" SG_ 1107 PAOBJ_LCA_rear_L_side_Y 3;
BA_ "GenSigSendType" SG_ 1107 PAOBJ_LCA_rear_L_side_X 3;
BA_ "GenSigSendType" SG_ 1107 PAOBJ_LCA_L_side_rel 3;
BA_ "GenSigSendType" SG_ 1107 PAOBJ_LCA_L_side_Y 3;
BA_ "GenSigSendType" SG_ 1107 PAOBJ_LCA_L_side_X 3;
BA_ "GenSigSendType" SG_ 1107 PAOBJ_LCA_rear_rel 3;
BA_ "GenSigSendType" SG_ 1107 PAOBJ_LCA_rear_Y 3;
BA_ "GenSigSendType" SG_ 1107 PAOBJ_LCA_rear_X 3;
BA_ "GenSigSendType" SG_ 1107 PAOBJ_LCA_front_rel 3;
BA_ "GenSigSendType" SG_ 1107 PAOBJ_LCA_front_Y 3;
BA_ "GenSigSendType" SG_ 1107 PAOBJ_LCA_front_X 3;
BA_ "GenSigSendType" SG_ 1106 PALNMID2 3;
BA_ "GenSigStartValue" SG_ 1106 PALNMID2 3;
BA_ "GenSigSendType" SG_ 1106 PALDAL 3;
BA_ "GenSigSendType" SG_ 1106 PALNTYL 3;
BA_ "GenSigSendType" SG_ 1106 PALN2Y7 3;
BA_ "GenSigSendType" SG_ 1106 PALN2Y6 3;
BA_ "GenSigSendType" SG_ 1106 PALN2Y5 3;
BA_ "GenSigSendType" SG_ 1106 PALN2Y4 3;
BA_ "GenSigSendType" SG_ 1106 PALN2Y3 3;
BA_ "GenSigSendType" SG_ 1106 PALN2Y2 3;
BA_ "GenSigSendType" SG_ 1106 PALN2Y1 3;
BA_ "GenSigSendType" SG_ 1106 PALNMID1 3;
BA_ "GenSigStartValue" SG_ 1106 PALNMID1 3;
BA_ "GenSigSendType" SG_ 1106 PALDAR 3;
BA_ "GenSigSendType" SG_ 1106 PALNTYR 3;
BA_ "GenSigSendType" SG_ 1106 PALN1Y7 3;
BA_ "GenSigSendType" SG_ 1106 PALN1Y6 3;
BA_ "GenSigSendType" SG_ 1106 PALN1Y5 3;
BA_ "GenSigSendType" SG_ 1106 PALN1Y4 3;
BA_ "GenSigSendType" SG_ 1106 PALN1Y3 3;
BA_ "GenSigSendType" SG_ 1106 PALN1Y2 3;
BA_ "GenSigSendType" SG_ 1106 PALN1Y1 3;
BA_ "GenSigSendType" SG_ 1106 PALDAY 3;
BA_ "GenSigSendType" SG_ 1106 PALNMKST 3;
BA_ "GenSigSendType" SG_ 1106 PATGTST 3;
BA_ "GenSigSendType" SG_ 1106 PATGTYA 3;
BA_ "GenSigSendType" SG_ 1106 PATGTY 3;
BA_ "GenSigSendType" SG_ 1106 PATGTX 3;
BA_ "GenSigSendType" SG_ 1106 PATRJY 3;
BA_ "GenSigSendType" SG_ 1106 PATRJX 3;
BA_ "GenSigSendType" SG_ 1106 PATRJSPD 3;
BA_ "GenSigSendType" SG_ 1106 PARSRCGR 3;
BA_ "GenSigSendType" SG_ 1106 PARSRCGL 3;
BA_ "GenSigSendType" SG_ 1106 PAVLOST 3;
BA_ "GenSigSendType" SG_ 1106 PAMODE 3;
BA_ "GenSigSendType" SG_ 1106 PARDSTL 3;
BA_ "GenSigSendType" SG_ 1106 PARDSTR 3;
BA_ "GenSigSendType" SG_ 1106 PAALNTYL 3;
BA_ "GenSigSendType" SG_ 1106 PAALNTYR 3;
BA_ "GenSigSendType" SG_ 1106 PAAMBST 3;
BA_ "GenSigSendType" SG_ 1106 PALCY3 3;
BA_ "GenSigSendType" SG_ 1106 PALCY2 3;
BA_ "GenSigSendType" SG_ 1106 PALCY1 3;
BA_ "GenSigSendType" SG_ 1106 PALCTRJ 3;
BA_ "GenSigSendType" SG_ 1106 PALCSP 3;
BA_ "GenSigSendType" SG_ 1106 PABSML 3;
BA_ "GenSigSendType" SG_ 1106 PABSMR 3;
BA_ "GenSigSendType" SG_ 1105 PAOBJST6 3;
BA_ "GenSigSendType" SG_ 1105 PAOBJTY6 3;
BA_ "GenSigSendType" SG_ 1105 PAOBJYA6 3;
BA_ "GenSigSendType" SG_ 1105 PAOBJY6 3;
BA_ "GenSigSendType" SG_ 1105 PAOBJX6 3;
BA_ "GenSigSendType" SG_ 1105 PAOBJID6 3;
BA_ "GenSigSendType" SG_ 1105 PAOBJST5 3;
BA_ "GenSigSendType" SG_ 1105 PAOBJTY5 3;
BA_ "GenSigSendType" SG_ 1105 PAOBJYA5 3;
BA_ "GenSigSendType" SG_ 1105 PAOBJY5 3;
BA_ "GenSigSendType" SG_ 1105 PAOBJX5 3;
BA_ "GenSigSendType" SG_ 1105 PAOBJID5 3;
BA_ "GenSigSendType" SG_ 1105 PAOBJST4 3;
BA_ "GenSigSendType" SG_ 1105 PAOBJTY4 3;
BA_ "GenSigSendType" SG_ 1105 PAOBJYA4 3;
BA_ "GenSigSendType" SG_ 1105 PAOBJY4 3;
BA_ "GenSigSendType" SG_ 1105 PAOBJX4 3;
BA_ "GenSigSendType" SG_ 1105 PAOBJID4 3;
BA_ "GenSigSendType" SG_ 1105 PAOBJST3 3;
BA_ "GenSigSendType" SG_ 1105 PAOBJTY3 3;
BA_ "GenSigSendType" SG_ 1105 PAOBJYA3 3;
BA_ "GenSigSendType" SG_ 1105 PAOBJY3 3;
BA_ "GenSigSendType" SG_ 1105 PAOBJX3 3;
BA_ "GenSigSendType" SG_ 1105 PAOBJID3 3;
BA_ "GenSigSendType" SG_ 1105 PAOBJST2 3;
BA_ "GenSigSendType" SG_ 1105 PAOBJTY2 3;
BA_ "GenSigSendType" SG_ 1105 PAOBJYA2 3;
BA_ "GenSigSendType" SG_ 1105 PAOBJY2 3;
BA_ "NWM-WakeupAllowed" SG_ 1105 PAOBJY2 1;
BA_ "GenSigSendType" SG_ 1105 PAOBJX2 3;
BA_ "GenSigSendType" SG_ 1105 PAOBJID2 3;
BA_ "GenSigSendType" SG_ 1105 PAOBJST1 3;
BA_ "GenSigSendType" SG_ 1105 PAOBJTY1 3;
BA_ "GenSigSendType" SG_ 1105 PAOBJYA1 3;
BA_ "GenSigSendType" SG_ 1105 PAOBJY1 3;
BA_ "GenSigSendType" SG_ 1105 PAOBJX1 3;
BA_ "GenSigSendType" SG_ 1105 PAOBJID1 3;
BA_ "GenSigSendType" SG_ 1104 FRC_WRN 3;
BA_ "GenSigSendType" SG_ 1104 FLC_WRN 3;
BA_ "GenSigSendType" SG_ 1104 FR_WRN 3;
BA_ "GenSigSendType" SG_ 1104 FL_WRN 3;
BA_ "GenSigSendType" SG_ 1104 FRC_POS 3;
BA_ "GenSigSendType" SG_ 1104 FLC_POS 3;
BA_ "GenSigSendType" SG_ 1104 FR_POS 3;
BA_ "GenSigSendType" SG_ 1104 FL_POS 3;
BA_ "GenSigSendType" SG_ 1104 RRC_WRN 3;
BA_ "GenSigSendType" SG_ 1104 RLC_WRN 3;
BA_ "GenSigSendType" SG_ 1104 RR_WRN 3;
BA_ "GenSigSendType" SG_ 1104 RL_WRN 3;
BA_ "GenSigSendType" SG_ 1104 RRC_POS 3;
BA_ "GenSigSendType" SG_ 1104 RLC_POS 3;
BA_ "GenSigSendType" SG_ 1104 RR_POS 3;
BA_ "GenSigSendType" SG_ 1104 RL_POS 3;
BA_ "GenSigSendType" SG_ 1104 CSRDISP1 3;
BA_ "GenSigSendType" SG_ 1104 CSMUTESW 3;
BA_ "GenSigSendType" SG_ 1104 PAS_EV_silent 3;
BA_ "GenSigSendType" SG_ 1104 PAS_state 3;
BA_ "GenSigSendType" SG_ 1104 TSR_gray 3;
BA_ "GenSigSendType" SG_ 1104 TSR_sub_sup_value 3;
BA_ "GenSigSendType" SG_ 1104 TSR_sub_value 3;
BA_ "GenSigSendType" SG_ 1104 TSR_sub_speed 3;
BA_ "GenSigInvalidValue" SG_ 1104 TSR_sub_speed 63;
BA_ "GenSigSendType" SG_ 1104 TSR_EV_tmp_failure 3;
BA_ "GenSigSendType" SG_ 1104 TSR_EV_fallback 3;
BA_ "GenSigSendType" SG_ 1104 TSR_fallback 3;
BA_ "GenSigSendType" SG_ 1104 TSR_next_distance 3;
BA_ "GenSigSendType" SG_ 1104 TSR_next_value 3;
BA_ "GenSigSendType" SG_ 1104 TSR_sound 3;
BA_ "GenSigSendType" SG_ 1104 TSR_EV_change 3;
BA_ "GenSigSendType" SG_ 1104 TSR_main_sup_value 3;
BA_ "GenSigSendType" SG_ 1104 TSR_main_value 3;
BA_ "GenSigSendType" SG_ 1104 TSR_next_speed 3;
BA_ "GenSigInvalidValue" SG_ 1104 TSR_next_speed 63;
BA_ "GenSigSendType" SG_ 1104 TSR_main_speed 3;
BA_ "GenSigInvalidValue" SG_ 1104 TSR_main_speed 63;
BA_ "GenSigSendType" SG_ 1104 TSR_EV_failure 3;
BA_ "GenSigSendType" SG_ 1104 TSR_EV_notification 3;
BA_ "GenSigSendType" SG_ 1104 TSR_warning 3;
BA_ "GenSigSendType" SG_ 1104 TSR_state 3;
BA_ "GenSigSendType" SG_ 1104 LCA_EV_warn_approach_rh 3;
BA_ "GenSigSendType" SG_ 1104 LCA_EV_warn_approach_lh 3;
BA_ "GenSigSendType" SG_ 1104 LCA_EV_auto_standby 3;
BA_ "GenSigSendType" SG_ 1104 LCA_EV_calcel_lka_off 3;
BA_ "GenSigSendType" SG_ 1104 LCA_EV_calcel_lka_on 3;
BA_ "GenSigSendType" SG_ 1104 LCA_state_lh 3;
BA_ "GenSigSendType" SG_ 1104 LCA_state_rh 3;
BA_ "GenSigSendType" SG_ 1104 LCA_state 3;
BA_ "GenSigSendType" SG_ 1104 HoF_handson_request_mute 3;
BA_ "GenSigSendType" SG_ 1104 HOF_approval_rec_state 3;
BA_ "GenSigSendType" SG_ 1104 HOF_rec_state 3;
BA_ "GenSigSendType" SG_ 1104 HOF_state 3;
BA_ "GenSigSendType" SG_ 1104 LKA_controllimit 3;
BA_ "GenSigSendType" SG_ 1104 LKA_state 3;
VAL_ 1409 CGW_NM_RptMsgRequest 0 "RepeatMessageState_not_request" 1 "RepeatMessageState_request" ;
VAL_ 1340 TrigReq_53C 0 "No" 1 "Yes" ;
VAL_ 1340 DiagCom_Protcol_53C 0 "NotSupported Any" 1 "Supported by CAN" 2 "Supported by CANFD" 3 "Supported by Ethernet" 4 "Reserved" 5 "Reserved" 6 "Reserved" 7 "Reserved" ;
VAL_ 1340 DiagSupt_Status_53C 0 "NotSupported_Diagnosis" 1 "SupportedGGDS with DTC" 2 "SupportedGGDS without DTC" 3 "SupportedMADRAS with DTC" 4 "SupportedMADRAS without DTC" 5 "Reserved" 6 "Reserved" 7 "Reserved" ;
VAL_ 1339 TrigReq_53B 0 "No" 1 "Yes" ;
VAL_ 1339 DiagCom_Protcol_53B 0 "NotSupported Any" 1 "Supported by CAN" 2 "Supported by CANFD" 3 "Supported by Ethernet" 4 "Reserved" 5 "Reserved" 6 "Reserved" 7 "Reserved" ;
VAL_ 1339 DiagSupt_Status_53B 0 "NotSupported_Diagnosis" 1 "SupportedGGDS with DTC" 2 "SupportedGGDS without DTC" 3 "SupportedMADRAS with DTC" 4 "SupportedMADRAS without DTC" 5 "Reserved" 6 "Reserved" 7 "Reserved" ;
VAL_ 1338 TrigReq_53A 0 "No" 1 "Yes" ;
VAL_ 1338 DiagCom_Protcol_53A 0 "NotSupported Any" 1 "Supported by CAN" 2 "Supported by CANFD" 3 "Supported by Ethernet" 4 "Reserved" 5 "Reserved" 6 "Reserved" 7 "Reserved" ;
VAL_ 1338 DiagSupt_Status_53A 0 "NotSupported_Diagnosis" 1 "SupportedGGDS with DTC" 2 "SupportedGGDS without DTC" 3 "SupportedMADRAS with DTC" 4 "SupportedMADRAS without DTC" 5 "Reserved" 6 "Reserved" 7 "Reserved" ;
VAL_ 1337 TrigReq_539 0 "No" 1 "Yes" ;
VAL_ 1337 DiagCom_Protcol_539 0 "NotSupported Any" 1 "Supported by CAN" 2 "Supported by CANFD" 3 "Supported by Ethernet" 4 "Reserved" 5 "Reserved" 6 "Reserved" 7 "Reserved" ;
VAL_ 1337 DiagSupt_Status_539 0 "NotSupported_Diagnosis" 1 "SupportedGGDS with DTC" 2 "SupportedGGDS without DTC" 3 "SupportedMADRAS with DTC" 4 "SupportedMADRAS without DTC" 5 "Reserved" 6 "Reserved" 7 "Reserved" ;
VAL_ 1336 TrigReq_538 0 "No" 1 "Yes" ;
VAL_ 1336 DiagCom_Protcol_538 0 "NotSupported Any" 1 "Supported by CAN" 2 "Supported by CANFD" 3 "Supported by Ethernet" 4 "Reserved" 5 "Reserved" 6 "Reserved" 7 "Reserved" ;
VAL_ 1336 DiagSupt_Status_538 0 "NotSupported_Diagnosis" 1 "SupportedGGDS with DTC" 2 "SupportedGGDS without DTC" 3 "SupportedMADRAS with DTC" 4 "SupportedMADRAS without DTC" 5 "Reserved" 6 "Reserved" 7 "Reserved" ;
VAL_ 1321 TrigReq_529 0 "No" 1 "Yes" ;
VAL_ 1321 DiagCom_Protcol_529 0 "NotSupported Any" 1 "Supported by CAN" 2 "Supported by CANFD" 3 "Supported by Ethernet" 4 "Reserved" 5 "Reserved" 6 "Reserved" 7 "Reserved" ;
VAL_ 1321 DiagSupt_Status_529 0 "NotSupported_Diagnosis" 1 "SupportedGGDS with DTC" 2 "SupportedGGDS without DTC" 3 "SupportedMADRAS with DTC" 4 "SupportedMADRAS without DTC" 5 "Reserved" 6 "Reserved" 7 "Reserved" ;
VAL_ 1276 V_IDASEN 0 "No indication" 1 "Earlier" 2 "Default" 3 "Later" ;
VAL_ 1276 V_IDAOPE 0 "Not operated (IDA status ON)" 1 "Central display" 2 "Left display" 3 "Right display" 4 "Left and right display" 5 "Steering override" 6 "Deceleration override" 7 "IDA function status OFF" ;
VAL_ 1276 USMRTL 0 "Not Right-turn lane" 1 "Right-turn lane" ;
VAL_ 1276 USMSTL 0 "Not Straight-running lane" 1 "Straight-running lane" ;
VAL_ 1276 USMLTL 0 "Not Left-turn lane" 1 "Left-turn lane" ;
VAL_ 1275 USMRCGTL 0 "indefinite," 1 "Green ON," 2 "Yellow ON," 3 "Red ON," 4 "Red w Arrow sig(dir unk)" 5 "Red w Arrow sig(dir not allow)" 6 "Red w Arrow sig(dir allow)" 7 "Reserved" ;
VAL_ 1275 USMTGTPV 0 "Not exist URSM preceding vehicle" 1 "Exist URSM preceding vehicle" ;
VAL_ 1272 USMTSTYP 0 "None" 1 "Traffic Light" 2 "Stop Sign" 3 "State3" ;
VAL_ 1272 USMACTFG 0 "URSM Not decelerating" 1 "URSM decelerating" ;
VAL_ 1272 USMSENS 0 "Low" 1 "Mid" 2 "High" 3 "State3" ;
VAL_ 1272 USMFUNC 0 "OFF for Traffic Light/Stop Sign" 1 "ON for Traffic Light/Stop Sign" ;
VAL_ 1272 USMCNTST 0 "OFF" 1 "Ready" 2 "SET" 3 "Fail" ;
VAL_ 1267 DimmerCancel_Stat 0 "unknown" 1 "Off" 2 "On" 3 "Reserved" ;
VAL_ 1267 Disp_Status_B_Actl 0 "Off" 1 "Short Push" 2 "Long Push" 3 "Reserved" ;
VAL_ 1267 TVMOfSw_B_Actl 0 "Off" 1 "On" ;
VAL_ 1267 DimmerCancel_Rq 0 "Off" 1 "On" ;
VAL_ 1267 Drive_Mode_SW_ErrSts_Touch 0 "Normal" 1 "Error" ;
VAL_ 1267 Drive_Mode_SW_ErrSts_Strg 0 "Normal" 1 "Error" ;
VAL_ 1267 Drive_Mode_Req_CDC 0 "No Request" 1 "Normal mode" 2 "Sport mode" 3 "Off-Road mode" 4 "Towing mode" 5 "EV mode" 6 "Long Range mode" 7 "Reserved" 8 "Reserved" 9 "Reserved" 10 "Reserved" 11 "Reserved" 12 "Reserved" 13 "Reserved" 14 "Not_Determind" 15 "Invalid" ;
VAL_ 1267 AEB_HEC_Fail_Flag 0 "Off" 1 "On" ;
VAL_ 1267 AvgFuelEco_Rst_HEC 0 "Not Request" 1 "Request Set" ;
VAL_ 1267 Veh_speed_Fault 0 "Good Value" 1 "Faulty Value" ;
VAL_ 1267 Veh_speed_Unit 0 "km/h" 1 "mph" ;
VAL_ 1267 RSRmid_TmpOffReq 0 "Not Request" 1 "Request Set" ;
VAL_ 1258 HELPREQ 0 "No request" 1 "On request" ;
VAL_ 1182 CstmzStat_RCD_ONOFF_GUI 0 "Normal" 1 "Gray" 2 "NoDisplay" ;
VAL_ 1182 CstmzStat_TAP_ALERT_ONOFF_GUI 0 "Normal" 1 "Gray" 2 "NoDisplay" ;
VAL_ 1182 CstmzStat_APS_RPC_DISTANCE_GUI 0 "Normal" 1 "Gray" 2 "NoDisplay" ;
VAL_ 1182 CstmzStat_PK_TrvB_EndP_GUI 0 "Normal" 1 "Gray" 2 "NoDisplay" ;
VAL_ 1182 CstmzStat_PK_TrvF_EndP_GUI 0 "Normal" 1 "Gray" 2 "NoDisplay" ;
VAL_ 1182 CstmzStat_PK_VehBLen_GUI 0 "Normal" 1 "Gray" 2 "NoDisplay" ;
VAL_ 1182 CstmzStat_PKout_View_GUI 0 "Normal" 1 "Gray" 2 "NoDisplay" ;
VAL_ 1182 CstmzStat_PKin_View_GUI 0 "Normal" 1 "Gray" 2 "NoDisplay" ;
VAL_ 1182 CstmzStat_PKout_PallalelDir_GUI 0 "Normal" 1 "Gray" 2 "NoDisplay" ;
VAL_ 1182 CstmzStat_PKout_CrossDir_GUI 0 "Normal" 1 "Gray" 2 "NoDisplay" ;
VAL_ 1182 CstmzStat_PK_Rd_Wid_GUI 0 "Normal" 1 "Gray" 2 "NoDisplay" ;
VAL_ 1182 CstmzStat_PK_Trv_Line_GUI 0 "Normal" 1 "Gray" 2 "NoDisplay" ;
VAL_ 1182 CstmzStat_PK_Veh_Dir_GUI 0 "Normal" 1 "Gray" 2 "NoDisplay" ;
VAL_ 1182 CstmzStat_APVSPD_LVL_GUI 0 "Normal" 1 "Gray" 2 "NoDisplay" ;
VAL_ 1182 CstmzStat_GUIDE_ONOFF_GUI 0 "Normal" 1 "Gray" 2 "NoDisplay" ;
VAL_ 1182 CstmzStat_RPC_ONOFF_GUI 0 "Normal" 1 "Gray" 2 "NoDisplay" ;
VAL_ 1182 CstmzStat_ACC_GDMS_ONOFF_GUI 0 "Normal" 1 "Gray" 2 "NoDisplay" ;
VAL_ 1182 CstmzStat_ACC_ACCL_Sens_GUI 0 "Normal" 1 "Gray" 2 "NoDisplay" ;
VAL_ 1182 CstmzStat_ACC_CURVE_Sens_GUI 0 "Normal" 1 "Gray" 2 "NoDisplay" ;
VAL_ 1182 CstmzStat_ACC_OVTK_ONOFF_GUI 0 "Normal" 1 "Gray" 2 "NoDisplay" ;
VAL_ 1182 CstmzStat_TMN_LV_Sens_GUI 0 "Normal" 1 "Gray" 2 "NoDisplay" ;
VAL_ 1182 CstmzStat_TMN_TS_Sens_GUI 0 "Normal" 1 "Gray" 2 "NoDisplay" ;
VAL_ 1182 CstmzStat_LCA_ONOFF_GUI 0 "Normal" 1 "Gray" 2 "NoDisplay" ;
VAL_ 1182 CstmzStat_HOF_REC_ONOFF_GUI 0 "Normal" 1 "Gray" 2 "NoDisplay" ;
VAL_ 1182 CstmzStat_HOF_ONOFF_GUI 0 "Normal" 1 "Gray" 2 "NoDisplay" ;
VAL_ 1182 CstmzStat_ESA_AES_ONOFF_GUI 0 "Normal" 1 "Gray" 2 "NoDisplay" ;
VAL_ 1182 CstmzStat_PDA_Sens_GUI 0 "Normal" 1 "Gray" 2 "NoDisplay" ;
VAL_ 1182 CstmzStat_PDA_ONOFF_GUI 0 "Normal" 1 "Gray" 2 "NoDisplay" ;
VAL_ 1182 CstmzStat_TVM_MOAAuto_ONOFF_GUI 0 "Normal" 1 "Gray" 2 "NoDisplay" ;
VAL_ 1182 CstmzStat_TVM_MOA_ONOFF_GUI 0 "Normal" 1 "Gray" 2 "NoDisplay" ;
VAL_ 1182 CstmzStat_TVM_AutoOFF_ONOFF_GUI 0 "Normal" 1 "Gray" 2 "NoDisplay" ;
VAL_ 1182 CstmzStat_TVM_PASRear_Sens_GUI 0 "Normal" 1 "Gray" 2 "NoDisplay" ;
VAL_ 1182 CstmzStat_TVM_PASFront_Sens_GUI 0 "Normal" 1 "Gray" 2 "NoDisplay" ;
VAL_ 1182 CstmzStat_TVM_PAS_ONOFF_GUI 0 "Normal" 1 "Gray" 2 "NoDisplay" ;
VAL_ 1182 CstmzStat_PAS_Vol_GUI 0 "Normal" 1 "Gray" 2 "NoDisplay" ;
VAL_ 1182 CstmzStat_PAS_ONOFF_GUI 0 "Normal" 1 "Gray" 2 "NoDisplay" ;
VAL_ 1182 CstmzStat_EDA_ONOFF_GUI 0 "Normal" 1 "Gray" 2 "NoDisplay" ;
VAL_ 1182 CstmzStat_EDA_Sleep_ONOFF_GUI 0 "Normal" 1 "Gray" 2 "NoDisplay" ;
VAL_ 1182 CstmzStat_DM_ONOFF_GUI 0 "Normal" 1 "Gray" 2 "NoDisplay" ;
VAL_ 1182 CstmzStat_OCP_ONOFF_GUI 0 "Normal" 1 "Gray" 2 "NoDisplay" ;
VAL_ 1182 CstmzStat_BSP_ONOFF_GUI 0 "Normal" 1 "Gray" 2 "NoDisplay" ;
VAL_ 1182 CstmzStat_RDP_ONOFF_GUI 0 "Normal" 1 "Gray" 2 "NoDisplay" ;
VAL_ 1182 CstmzStat_ELK_ONOFF_GUI 0 "Normal" 1 "Gray" 2 "NoDisplay" ;
VAL_ 1182 CstmzStat_RAEB_ONOFF_GUI 0 "Normal" 1 "Gray" 2 "NoDisplay" ;
VAL_ 1182 CstmzStat_HeadOn_ONOFF_GUI 0 "Normal" 1 "Gray" 2 "NoDisplay" ;
VAL_ 1182 CstmzStat_TAP_ONOFF_GUI 0 "Normal" 1 "Gray" 2 "NoDisplay" ;
VAL_ 1182 CstmzStat_CTB_ONOFF_GUI 0 "Normal" 1 "Gray" 2 "NoDisplay" ;
VAL_ 1182 CstmzStat_AEB_Vol_GUI 0 "Normal" 1 "Gray" 2 "NoDisplay" ;
VAL_ 1182 CstmzStat_FAEB_ONOFF_GUI 0 "Normal" 1 "Gray" 2 "NoDisplay" ;
VAL_ 1182 CstmzStat_LDP_ONOFF_GUI 0 "Normal" 1 "Gray" 2 "NoDisplay" ;
VAL_ 1182 CstmzStat_CBDA_Sens_GUI 0 "Normal" 1 "Gray" 2 "NoDisplay" ;
VAL_ 1182 CstmzStat_CBDA_ONOFF_GUI 0 "Normal" 1 "Gray" 2 "NoDisplay" ;
VAL_ 1182 CstmzStat_TSR_Warn_GUI_SignBz 0 "Normal" 1 "Gray" 2 "NoDisplay" ;
VAL_ 1182 CstmzStat_TSR_Warn_GUI_Sign 0 "Normal" 1 "Gray" 2 "NoDisplay" ;
VAL_ 1182 CstmzStat_TSR_Warn_GUI_OFF 0 "Normal" 1 "Gray" 2 "NoDisplay" ;
VAL_ 1182 CstmzStat_LDW_ELK_Warn_GUI 0 "Normal" 1 "Gray" 2 "NoDisplay" ;
VAL_ 1182 CstmzStat_BSM_Sens_GUI 0 "Normal" 1 "Gray" 2 "NoDisplay" ;
VAL_ 1182 CstmzStat_BSM_ONOFF_GUI 0 "Normal" 1 "Gray" 2 "NoDisplay" ;
VAL_ 1182 CstmzStat_LDW_ONOFF_GUI 0 "Normal" 1 "Gray" 2 "NoDisplay" ;
VAL_ 1182 CstmzStat_RCTA_ONOFF_GUI 0 "Normal" 1 "Gray" 2 "NoDisplay" ;
VAL_ 1182 CstmzStat_FCTA_Sens_GUI 0 "Normal" 1 "Gray" 2 "NoDisplay" ;
VAL_ 1182 CstmzStat_FCTA_ONOFF_GUI 0 "Normal" 1 "Gray" 2 "NoDisplay" ;
VAL_ 1182 CstmzStat_TSRWarnThres_GUI_10 0 "Normal" 1 "Gray" 2 "NoDisplay" ;
VAL_ 1182 CstmzStat_TSRWarnThres_GUI_5 0 "Normal" 1 "Gray" 2 "NoDisplay" ;
VAL_ 1182 CstmzStat_TSRWarnThres_GUI_3 0 "Normal" 1 "Gray" 2 "NoDisplay" ;
VAL_ 1182 CstmzStat_TSRWarnThres_GUI_0 0 "Normal" 1 "Gray" 2 "NoDisplay" ;
VAL_ 1182 CstmzStat_TSR_Change_GUI 0 "Normal" 1 "Gray" 2 "NoDisplay" ;
VAL_ 1182 CstmzStat_TSR_NextInfo_GUI 0 "Normal" 1 "Gray" 2 "NoDisplay" ;
VAL_ 1182 CstmzStat_TSR_ONOFF_GUI 0 "Normal" 1 "Gray" 2 "NoDisplay" ;
VAL_ 1182 CstmzStat_ISA_TSR_ADJST_GUI 0 "Normal" 1 "Gray" 2 "NoDisplay" ;
VAL_ 1182 CstmzStat_IACC_TSR_ADJST_GUI 0 "Normal" 1 "Gray" 2 "NoDisplay" ;
VAL_ 1182 CstmzStat_MRCC_TSR_Mode_GUI 0 "Normal" 1 "Gray" 2 "NoDisplay" ;
VAL_ 1182 CstmzStat_MRCC_ASC_Mode_GUI 0 "Normal" 1 "Gray" 2 "NoDisplay" ;
VAL_ 1170 CstmzStat_RCD_ONOFF 0 "Not Adopted" 1 "OFF" 2 "ON" ;
VAL_ 1170 CstmzStat_TAP_ALERT_ONOFF 0 "Not Adopted" 1 "OFF" 2 "ON" ;
VAL_ 1170 CstmzStat_APS_RPC_DISTANCE 0 "Not Adopted" 1 "Normal" 2 "Wide" ;
VAL_ 1170 CstmzStat_PK_TrvB_EndP 0 "Not Adopted" 1 "Back Lv3" 2 "Back Lv2" 3 "Back Lv1" 4 "Normal" 5 "Front Lv1" 6 "Front Lv2" 7 "Front Lv3" ;
VAL_ 1170 CstmzStat_PK_TrvF_EndP 0 "Not Adopted" 1 "Back Lv3" 2 "Back Lv2" 3 "Back Lv1" 4 "Normal" 5 "Front Lv1" 6 "Front Lv2" 7 "Front Lv3" ;
VAL_ 1170 CstmzStat_PK_VehBLen 0 "Not Adopted" 1 "Normal" 2 "Length Lv1" 3 "Length Lv2" 4 "Length Lv3" 5 "Length Lv4" ;
VAL_ 1170 CstmzStat_PKout_View 0 "Not Adopted" 1 "Narrow" 2 "Wide" ;
VAL_ 1170 CstmzStat_PKin_View 0 "Not Adopted" 1 "Narrow" 2 "Wide" ;
VAL_ 1170 CstmzStat_PKout_PallalelDir 0 "Not Adopted" 1 "Left" 2 "Right" ;
VAL_ 1170 CstmzStat_PKout_CrossDir 0 "Not Adopted" 1 "Left" 2 "Right" ;
VAL_ 1170 CstmzStat_PK_Rd_Wid 0 "Not Adopted" 1 "Narrow" 2 "Wide" ;
VAL_ 1170 CstmzStat_PK_Trv_Line 0 "Not Adopted" 1 "Inside Lv3" 2 "Inside Lv2" 3 "Inside Lv1" 4 "Normal" 5 "Outside Lv1" 6 "Outside Lv2" 7 "Outside Lv3" ;
VAL_ 1170 CstmzStat_PK_Veh_Dir 0 "Not Adopted" 1 "Forward" 2 "Backward" ;
VAL_ 1170 CstmzStat_APVSPD_LVL 0 "Not Adopted" 1 "Normal speed" 2 "Low speed" 3 "High speed" ;
VAL_ 1170 CstmzStat_GUIDE_ONOFF 0 "Not Adopted" 1 "OFF" 2 "Partical ON" 3 "ON" ;
VAL_ 1170 CstmzStat_RPC_ONOFF 0 "Not Adopted" 1 "ON" 2 "OFF" ;
VAL_ 1170 CstmzStat_ACC_GCR_ONOFF 0 "Not Adopted" 1 "OFF" 2 "ON" ;
VAL_ 1170 CstmzStat_ACC_ACCL_Sens 0 "Not Adopted" 1 "OFF" 2 "Lo" 3 "Mid" 4 "Hi" 5 "Reserve" 6 "Reserve" 7 "Reserve" ;
VAL_ 1170 CstmzStat_ACC_CURVE_Sens 0 "Not Adopted" 1 "OFF" 2 "Lo" 3 "Mid" 4 "Hi" 5 "Reserve" 6 "Reserve" 7 "Reserve" ;
VAL_ 1170 CstmzStat_ACC_OVTK_ONOFF 0 "Not Adopted" 1 "OFF" 2 "ON" ;
VAL_ 1170 CstmzStat_TMN_LV_Sens 0 "Not Adopted" 1 "Sensitivity_1(Early)" 2 "Sensitivity_2(Mid)" 3 "Sensitivity_3(Late)" 4 "OFF" 5 "Reserve" 6 "Reserve" 7 "Reserve" ;
VAL_ 1170 CstmzStat_TMN_TS_Sens 0 "Not Adopted" 1 "Sensitivity_1(Early)" 2 "Sensitivity_2(Mid)" 3 "Sensitivity_3(Late)" 4 "OFF" 5 "Reserve" 6 "Reserve" 7 "Reserve" ;
VAL_ 1170 CstmzStat_LCA_ONOFF 0 "Not Adopted" 1 "OFF" 2 "ON" ;
VAL_ 1170 CstmzStat_HOF_REC_ONOFF 0 "Not Adopted" 1 "OFF" 2 "ON" ;
VAL_ 1170 CstmzStat_HOF_ONOFF 0 "Not Adopted" 1 "OFF" 2 "ON" ;
VAL_ 1170 CstmzStat_ESA_AES_ONOFF 0 "Not Adopted" 1 "OFF" 2 "ON" ;
VAL_ 1170 CstmzStat_PDA_Sens 0 "Not Adopted" 1 "Sensitivity_1" 2 "Sensitivity_2" 3 "Sensitivity_3" 4 "Reserve" 5 "Reserve" 6 "Reserve" 7 "Reserve" ;
VAL_ 1170 CstmzStat_PDA_ONOFF 0 "Not Adopted" 1 "OFF" 2 "ON" ;
VAL_ 1170 CstmzStat_TVM_MOAAuto_ONOFF 0 "Not Adopted" 1 "OFF" 2 "ON" ;
VAL_ 1170 CstmzStat_TVM_MOA_ONOFF 0 "Not Adopted" 1 "OFF" 2 "ON" ;
VAL_ 1170 CstmzStat_TVM_AutoOFF_ONOFF 0 "Not Adopted" 1 "OFF" 2 "ON" ;
VAL_ 1170 CstmzStat_TVM_PASRear_Sens 0 "Not Adopted" 1 "Middle" 2 "Near" ;
VAL_ 1170 CstmzStat_TVM_PASFront_Sens 0 "Not Adopted" 1 "Middle" 2 "Near" ;
VAL_ 1170 CstmzStat_TVM_PAS_ONOFF 0 "Not Adopted" 1 "OFF" 2 "ON" ;
VAL_ 1170 PrsnlSys_Switch_ID_ADU_Res 0 "No Action" 1 "Complete" ;
VAL_ 1170 CstmzStat_PAS_Vol 0 "Not Adopted" 1 "Volume 1" 2 "Volume 2" 3 "Volume 3" ;
VAL_ 1170 CstmzStat_PAS_ONOFF 0 "Not Adopted" 1 "OFF" 2 "ON" ;
VAL_ 1170 CstmzStat_EDA_ONOFF 0 "Not Adopted" 1 "OFF" 2 "ON" ;
VAL_ 1170 CstmzStat_EDA_Sleep_ONOFF 0 "Not Adopted" 1 "OFF" 2 "ON" ;
VAL_ 1170 CstmzStat_DM_ONOFF 0 "Not Adopted" 1 "OFF" 2 "ON" ;
VAL_ 1170 CstmzStat_OCP_ONOFF 0 "Not Adopted" 1 "OFF" 2 "ON" ;
VAL_ 1170 CstmzStat_BSP_ONOFF 0 "Not Adopted" 1 "OFF" 2 "ON" ;
VAL_ 1170 CstmzStat_RDP_ONOFF 0 "Not Adopted" 1 "OFF" 2 "ON" ;
VAL_ 1170 CstmzStat_ELK_ONOFF 0 "Not Adopted" 1 "OFF" 2 "ON" ;
VAL_ 1170 CstmzStat_RAEB_ONOFF 0 "Not Adopted" 1 "OFF" 2 "ON" ;
VAL_ 1170 CstmzStat_HeadOn_ONOFF 0 "Not Adopted" 1 "OFF" 2 "ON" ;
VAL_ 1170 CstmzStat_TAP_ONOFF 0 "Not Adopted" 1 "OFF" 2 "ON" ;
VAL_ 1170 CstmzStat_CTB_ONOFF 0 "Not Adopted" 1 "OFF" 2 "ON" ;
VAL_ 1170 CstmzStat_AEB_Vol 0 "Not Adopted" 1 "OFF" 2 "ON" ;
VAL_ 1170 CstmzStat_FAEB_ONOFF 0 "Not Adopted" 1 "OFF" 2 "ON" ;
VAL_ 1170 CstmzStat_LDP_ONOFF 0 "Not Adopted" 1 "OFF" 2 "ON" ;
VAL_ 1170 CstmzStat_CBDA_Sens 0 "Not Adopted" 1 "Sensitivity_1(HI)" 2 "Sensitivity_2(Mid)" 3 "Sensitivity_3(LO)" ;
VAL_ 1170 CstmzStat_CBDA_ONOFF 0 "Not Adopted" 1 "OFF" 2 "Sign only" 3 "Sign + Buzzer" ;
VAL_ 1170 CstmzStat_LDW_ELK_Warn 0 "Not Adopted" 1 "OFF" 2 "Vibration" 3 "Buzzer" 4 "Vibration + Buzzer" ;
VAL_ 1170 CstmzStat_BSM_Sens 0 "Not Adopted" 1 "Sensitivity_1(HI)" 2 "Sensitivity_2(Mid)" 3 "Sensitivity_3(LO)" ;
VAL_ 1170 CstmzStat_BSM_ONOFF 0 "Not Adopted" 1 "OFF" 2 "Sign only" 3 "Sign + Warning" 4 "Sign + Vibration" ;
VAL_ 1170 CstmzStat_LDW_ONOFF 0 "Not Adopted" 1 "OFF" 2 "ON" ;
VAL_ 1170 CstmzStat_RCTA_ONOFF 0 "Not Adopted" 1 "OFF" 2 "Sign only" 3 "Sign + Buzzer" ;
VAL_ 1170 CstmzStat_FCTA_Sens 0 "Not Adopted" 1 "Sensitivity_1(HI)" 2 "Sensitivity_2(Mid)" 3 "Sensitivity_3(LO)" ;
VAL_ 1170 CstmzStat_FCTA_ONOFF 0 "Not Adopted" 1 "OFF" 2 "Sign only" 3 "Sign + Buzzer" ;
VAL_ 1170 CstmzStat_TSRWarnThres 0 "Not Adopted" 1 "0kph_0mph" 2 "3kph_3mph" 3 "5kph_5mph" 4 "10kph_10mph" ;
VAL_ 1170 CstmzStat_TSR_Warn 0 "Not Adopted" 1 "OFF" 2 "Sign only" 3 "Sign + Buzzer" ;
VAL_ 1170 CstmzStat_TSR_Change 0 "Not Adopted" 1 "OFF" 2 "ON" ;
VAL_ 1170 CstmzStat_TSR_NextInfo 0 "Not Adopted" 1 "OFF" 2 "ON" ;
VAL_ 1170 CstmzStat_TSR_ONOFF 0 "Not Adopted" 1 "OFF" 2 "ON" ;
VAL_ 1170 CstmzStat_ISA_TSR_ADJST 0 "Not Adopted" 1 "-10kph_-10mph" 2 "-9kph_-9mph" 3 "-8kph_-8mph" 4 "-7kph_-7mph" 5 "-6kph_-6mph" 6 "-5kph_-5mph" 7 "-4kph_-4mph" 8 "-3kph_-3mph" 9 "-2kph_-2mph" 10 "-1kph_-1mph" 11 "0kph_0mph" 12 "1kph_1mph" 13 "2kph_2mph" 14 "3kph_3mph" 15 "4kph_4mph" 16 "5kph_5mph" 17 "6kph_6mph" 18 "7kph_7mph" 19 "8kph_8mph" 20 "9kph_9mph" 21 "10kph_10mph" ;
VAL_ 1170 CstmzStat_IACC_TSR_ADJST 0 "Not Adopted" 1 "-10kph_-10mph" 2 "-9kph_-9mph" 3 "-8kph_-8mph" 4 "-7kph_-7mph" 5 "-6kph_-6mph" 6 "-5kph_-5mph" 7 "-4kph_-4mph" 8 "-3kph_-3mph" 9 "-2kph_-2mph" 10 "-1kph_-1mph" 11 "0kph_0mph" 12 "1kph_1mph" 13 "2kph_2mph" 14 "3kph_3mph" 15 "4kph_4mph" 16 "5kph_5mph" 17 "6kph_6mph" 18 "7kph_7mph" 19 "8kph_8mph" 20 "9kph_9mph" 21 "10kph_10mph" ;
VAL_ 1170 CstmzStat_MRCC_TSR_Mode 0 "Not Adopted" 1 "OFF" 2 "ON" ;
VAL_ 1170 CstmzStat_MRCC_ASC_Mode 0 "Not Adopted" 1 "OFF(MRCC)" 2 "ON(ASC)" ;
VAL_ 1169 CstmzRsp_RCD_ONOFF 0 "Not Change" 1 "OFF" 2 "ON" ;
VAL_ 1169 CstmzRsp_TAP_ALERT_ONOFF 0 "Not Change" 1 "OFF" 2 "ON" ;
VAL_ 1169 CstmzRsp_APS_RPC_DISTANCE 0 "Not Change" 1 "Normal" 2 "Wide" ;
VAL_ 1169 CstmzRsp_PK_TrvB_EndP 0 "Not Change" 1 "Back Lv3" 2 "Back Lv2" 3 "Back Lv1" 4 "Normal" 5 "Front Lv1" 6 "Front Lv2" 7 "Front Lv3" ;
VAL_ 1169 CstmzRsp_PK_TrvF_EndP 0 "Not Change" 1 "Back Lv3" 2 "Back Lv2" 3 "Back Lv1" 4 "Normal" 5 "Front Lv1" 6 "Front Lv2" 7 "Front Lv3" ;
VAL_ 1169 CstmzRsp_PK_VehBLen 0 "Not Change" 1 "Normal" 2 "Length Lv1" 3 "Length Lv2" 4 "Length Lv3" 5 "Length Lv4" ;
VAL_ 1169 CstmzRsp_PKout_View 0 "Not Change" 1 "Narrow" 2 "Wide" ;
VAL_ 1169 CstmzRsp_PKin_View 0 "Not Change" 1 "Narrow" 2 "Wide" ;
VAL_ 1169 CstmzRsp_PKout_PallalelDir 0 "Not Change" 1 "Left" 2 "Right" ;
VAL_ 1169 CstmzRsp_PKout_CrossDir 0 "Not Change" 1 "Left" 2 "Right" ;
VAL_ 1169 CstmzRsp_PK_Rd_Wid 0 "Not Change" 1 "Narrow" 2 "Wide" ;
VAL_ 1169 CstmzRsp_PK_Trv_Line 0 "Not Change" 1 "Inside Lv3" 2 "Inside Lv2" 3 "Inside Lv1" 4 "Normal" 5 "Outside Lv1" 6 "Outside Lv2" 7 "Outside Lv3" ;
VAL_ 1169 CstmzRsp_PK_Veh_Dir 0 "Not Change" 1 "Forward" 2 "Backward" ;
VAL_ 1169 CstmzRsp_APVSPD_LVL 0 "Not Change" 1 "Normal speed" 2 "Low speed" 3 "High speed" ;
VAL_ 1169 CstmzRsp_GUIDE_ONOFF 0 "Not Change" 1 "OFF" 2 "Partical ON" 3 "ON" ;
VAL_ 1169 CstmzRsp_RPC_ONOFF 0 "Not Change" 1 "ON" 2 "OFF" ;
VAL_ 1169 CstmzRsp_Status_VRsp04 0 "Unknown" 1 "Customize Rejected" 2 "Customize Complete" ;
VAL_ 1169 CstmzRsp_Contents_VRsp04 0 "No Action" 1 "Customize Response" 2 "Initialize Response" ;
VAL_ 1169 CstmzRsp_ACC_GCR_ONOFF 0 "Not Change" 1 "OFF" 2 "ON" ;
VAL_ 1169 CstmzRsp_ACC_ACCL_Sens 0 "Not Change" 1 "OFF" 2 "Lo" 3 "Mid" 4 "Hi" 5 "Reserve" 6 "Reserve" 7 "Reserve" ;
VAL_ 1169 CstmzRsp_ACC_CURVE_Sens 0 "Not Change" 1 "OFF" 2 "Lo" 3 "Mid" 4 "Hi" 5 "Reserve" 6 "Reserve" 7 "Reserve" ;
VAL_ 1169 CstmzRsp_ACC_OVTK_ONOFF 0 "Not Change" 1 "OFF" 2 "ON" ;
VAL_ 1169 CstmzRsp_TMN_LV_Sens 0 "Not Change" 1 "Sensitivity_1(Early)" 2 "Sensitivity_2(Mid)" 3 "Sensitivity_3(Late)" 4 "OFF" 5 "Reserve" 6 "Reserve" 7 "Reserve" ;
VAL_ 1169 CstmzRsp_TMN_TS_Sens 0 "Not Change" 1 "Sensitivity_1(Early)" 2 "Sensitivity_2(Mid)" 3 "Sensitivity_3(Late)" 4 "OFF" 5 "Reserve" 6 "Reserve" 7 "Reserve" ;
VAL_ 1169 CstmzRsp_LCA_ONOFF 0 "Not Change" 1 "OFF" 2 "ON" ;
VAL_ 1169 CstmzRsp_HOF_REC_ONOFF 0 "Not Change" 1 "OFF" 2 "ON" ;
VAL_ 1169 CstmzRsp_HOF_ONOFF 0 "Not Change" 1 "OFF" 2 "ON" ;
VAL_ 1169 CstmzRsp_ESA_AES_ONOFF 0 "Not Change" 1 "OFF" 2 "ON" ;
VAL_ 1169 CstmzRsp_PDA_Sens 0 "Not Change" 1 "Sensitivity_1" 2 "Sensitivity_2" 3 "Sensitivity_3" 4 "Reserve" 5 "Reserve" 6 "Reserve" 7 "Reserve" ;
VAL_ 1169 CstmzRsp_PDA_ONOFF 0 "Not Change" 1 "OFF" 2 "ON" ;
VAL_ 1169 CstmzRsp_TVM_MOAAuto_ONOFF 0 "Not Change" 1 "OFF" 2 "ON" ;
VAL_ 1169 CstmzRsp_TVM_MOA_ONOFF 0 "Not Change" 1 "OFF" 2 "ON" ;
VAL_ 1169 CstmzRsp_TVM_AutoOFF_ONOFF 0 "Not Change" 1 "OFF" 2 "ON" ;
VAL_ 1169 CstmzRsp_TVM_PASRear_Sens 0 "Not Change" 1 "Middle" 2 "Near" ;
VAL_ 1169 CstmzRsp_TVM_PASFront_Sens 0 "Not Change" 1 "Middle" 2 "Near" ;
VAL_ 1169 CstmzRsp_TVM_PAS_ONOFF 0 "Not Change" 1 "OFF" 2 "ON" ;
VAL_ 1169 CstmzRsp_Status_VRsp03 0 "Unknown" 1 "Customize Rejected" 2 "Customize Complete" ;
VAL_ 1169 CstmzRsp_Contents_VRsp03 0 "No Action" 1 "Customize Response" 2 "Initialize Response" ;
VAL_ 1169 CstmzRsp_Init_ALL_ADAS_Prsnl 0 "No Action" 1 "Initialize ALL Data Complete_ID1" 2 "Initialize ALL Data Reject_ID1" 3 "Initialize ALL Data Complete_ID2" 4 "Initialize ALL Data Reject_ID2" 5 "Initialize ALL Data Complete_ID3" 6 "Initialize ALL Data Reject_ID3" 7 "Initialize ALL Data Complete_ID4" 8 "Initialize ALL Data Reject_ID4" 9 "Initialize ALL Data Complete_ID5" 10 "Initialize ALL Data Reject_ID5" 11 "Initialize ALL Data Complete_ID6" 12 "Initialize ALL Data Reject_ID6" 13 "Initialize ALL Data Complete_Gue" 14 "Initialize ALL Data Reject_Guest" 15 "Initialize ALL Data Complete_ALL" 16 "Initialize ALL Data Reject_ALL" 17 "Reserved" 18 "Reserved" 19 "Reserved" 20 "Reserved" 21 "Reserved" 22 "Reserved" 23 "Reserved" 24 "Reserved" 25 "Reserved" 26 "Reserved" 27 "Reserved" 28 "Reserved" 29 "Reserved" 30 "Reserved" 31 "Reserved" ;
VAL_ 1169 CstmzRsp_PAS_Vol 0 "Not Change" 1 "Volume 1" 2 "Volume 2" 3 "Volume 3" ;
VAL_ 1169 CstmzRsp_PAS_ONOFF 0 "Not Change" 1 "OFF" 2 "ON" ;
VAL_ 1169 CstmzRsp_EDA_ONOFF 0 "Not Change" 1 "OFF" 2 "ON" ;
VAL_ 1169 CstmzRsp_EDA_Sleep_ONOFF 0 "Not Change" 1 "OFF" 2 "ON" ;
VAL_ 1169 CstmzRsp_DM_ONOFF 0 "Not Change" 1 "OFF" 2 "ON" ;
VAL_ 1169 CstmzRsp_OCP_ONOFF 0 "Not Change" 1 "OFF" 2 "ON" ;
VAL_ 1169 CstmzRsp_BSP_ONOFF 0 "Not Change" 1 "OFF" 2 "ON" ;
VAL_ 1169 CstmzRsp_RDP_ONOFF 0 "Not Change" 1 "OFF" 2 "ON" ;
VAL_ 1169 CstmzRsp_ELK_ONOFF 0 "Not Change" 1 "OFF" 2 "ON" ;
VAL_ 1169 CstmzRsp_RAEB_ONOFF 0 "Not Change" 1 "OFF" 2 "ON" ;
VAL_ 1169 CstmzRsp_HeadOn_ONOFF 0 "Not Change" 1 "OFF" 2 "ON" ;
VAL_ 1169 CstmzRsp_TAP_ONOFF 0 "Not Change" 1 "OFF" 2 "ON" ;
VAL_ 1169 CstmzRsp_CTB_ONOFF 0 "Not Change" 1 "OFF" 2 "ON" ;
VAL_ 1169 CstmzRsp_AEB_Vol 0 "Not Change" 1 "OFF" 2 "ON" ;
VAL_ 1169 CstmzRsp_FAEB_ONOFF 0 "Not Change" 1 "OFF" 2 "ON" ;
VAL_ 1169 CstmzRsp_LDP_ONOFF 0 "Not Change" 1 "OFF" 2 "ON" ;
VAL_ 1169 CstmzRsp_CBDA_Sens 0 "Not Change" 1 "Sensitivity_1(HI)" 2 "Sensitivity_2(Mid)" 3 "Sensitivity_3(LO)" ;
VAL_ 1169 CstmzRsp_CBDA_ONOFF 0 "Not Change" 1 "OFF" 2 "Sign only" 3 "Sign + Buzzer" ;
VAL_ 1169 CstmzRsp_Status_VRsp02 0 "Unknown" 1 "Customize Rejected" 2 "Customize Complete" ;
VAL_ 1169 CstmzRsp_Contents_VRsp02 0 "No Action" 1 "Customize Response" 2 "Initialize Response" ;
VAL_ 1169 CstmzRsp_Init_ALL_ADAS 0 "No Action" 1 "Initialize ALL Data Complete" 2 "Initialize ALL Data Reject" ;
VAL_ 1169 CstmzRsp_LDW_ELK_Warn 0 "Not Change" 1 "OFF" 2 "Vibration" 3 "Buzzer" 4 "Vibration + Buzzer" ;
VAL_ 1169 CstmzRsp_BSM_Sens 0 "Not Change" 1 "Sensitivity_1(HI)" 2 "Sensitivity_2(Mid)" 3 "Sensitivity_3(LO)" ;
VAL_ 1169 CstmzRsp_BSM_ONOFF 0 "Not Change" 1 "OFF" 2 "Sign only" 3 "Sign + Warning" 4 "Sign + Vibration" ;
VAL_ 1169 CstmzRsp_LDW_ONOFF 0 "Not Change" 1 "OFF" 2 "ON" ;
VAL_ 1169 CstmzRsp_RCTA_ONOFF 0 "Not Change" 1 "OFF" 2 "Sign only" 3 "Sign + Buzzer" ;
VAL_ 1169 CstmzRsp_FCTA_Sens 0 "Not Change" 1 "Sensitivity_1(HI)" 2 "Sensitivity_2(Mid)" 3 "Sensitivity_3(LO)" ;
VAL_ 1169 CstmzRsp_FCTA_ONOFF 0 "Not Change" 1 "OFF" 2 "Sign only" 3 "Sign + Buzzer" ;
VAL_ 1169 CstmzRsp_TSRWarnThres 0 "Not Change" 1 "0kph_0mph" 2 "3kph_3mph" 3 "5kph_5mph" 4 "10kph_10mph" ;
VAL_ 1169 CstmzRsp_TSR_Warn 0 "Not Change" 1 "OFF" 2 "Sign only" 3 "Sign + Buzzer" ;
VAL_ 1169 CstmzRsp_TSR_Change 0 "Not Change" 1 "OFF" 2 "ON" ;
VAL_ 1169 CstmzRsp_TSR_NextInfo 0 "Not Change" 1 "OFF" 2 "ON" ;
VAL_ 1169 CstmzRsp_TSR_ONOFF 0 "Not Change" 1 "OFF" 2 "ON" ;
VAL_ 1169 CstmzRsp_ISA_TSR_ADJST 0 "Not Change" 1 "Plus" 2 "Minus" ;
VAL_ 1169 CstmzRsp_IACC_TSR_ADJST 0 "Not Change" 1 "Plus" 2 "Minus" ;
VAL_ 1169 CstmzRsp_MRCC_TSR_Mode 0 "Not Change" 1 "OFF" 2 "ON" ;
VAL_ 1169 CstmzRsp_MRCC_ASC_Mode 0 "Not Change" 1 "OFF(MRCC)" 2 "ON(ASC)" ;
VAL_ 1169 CstmzRsp_Status_VRsp01 0 "Unknown" 1 "Customize Rejected" 2 "Customize Complete" ;
VAL_ 1169 CstmzRsp_Contents_VRsp01 0 "No Action" 1 "Customize Response" 2 "Initialize Response" ;
VAL_ 1168 CstmzRq_RCD_ONOFF 0 "Not Change(InitAllowed)" 1 "OFF" 2 "ON" ;
VAL_ 1168 CstmzRq_TAP_ALERT_ONOFF 0 "Not Change(InitAllowed)" 1 "OFF" 2 "ON" ;
VAL_ 1168 CstmzRq_APS_RPC_DISTANCE 0 "Not Change(InitAllowed)" 1 "Normal" 2 "Wide" ;
VAL_ 1168 CstmzRq_PK_TrvB_EndP 0 "Not Change(InitAllowed)" 1 "Back Lv3" 2 "Back Lv2" 3 "Back Lv1" 4 "Normal" 5 "Front Lv1" 6 "Front Lv2" 7 "Front Lv3" ;
VAL_ 1168 CstmzRq_PK_TrvF_EndP 0 "Not Change(InitAllowed)" 1 "Back Lv3" 2 "Back Lv2" 3 "Back Lv1" 4 "Normal" 5 "Front Lv1" 6 "Front Lv2" 7 "Front Lv3" ;
VAL_ 1168 CstmzRq_PK_VehBLen 0 "Not Change(InitAllowed)" 1 "Normal" 2 "Length Lv1" 3 "Length Lv2" 4 "Length Lv3" 5 "Length Lv4" ;
VAL_ 1168 CstmzRq_PKout_View 0 "Not Change(InitAllowed)" 1 "Narrow" 2 "Wide" ;
VAL_ 1168 CstmzRq_PKin_View 0 "Not Change(InitAllowed)" 1 "Narrow" 2 "Wide" ;
VAL_ 1168 CstmzRq_PKout_PallalelDir 0 "Not Change(InitAllowed)" 1 "Left" 2 "Right" ;
VAL_ 1168 CstmzRq_PKout_CrossDir 0 "Not Change(InitAllowed)" 1 "Left" 2 "Right" ;
VAL_ 1168 CstmzRq_PK_Rd_Wid 0 "Not Change(InitAllowed)" 1 "Narrow" 2 "Wide" ;
VAL_ 1168 CstmzRq_PK_Trv_Line 0 "No Changed" 1 "Inside Lv3" 2 "Inside Lv2" 3 "Inside Lv1" 4 "Normal" 5 "Outside Lv1" 6 "Outside Lv2" 7 "Outside Lv3" ;
VAL_ 1168 CstmzRq_PK_Veh_Dir 0 "Not Change(InitAllowed)" 1 "Forward" 2 "Backward" ;
VAL_ 1168 CstmzRq_APVSPD_LVL 0 "Not Change(InitAllowed)" 1 "Normal speed" 2 "Low speed" 3 "High speed" ;
VAL_ 1168 CstmzRq_GUIDE_ONOFF 0 "Not Change(InitAllowed)" 1 "OFF" 2 "Partical ON" 3 "ON" ;
VAL_ 1168 CstmzRq_RPC_ONOFF 0 "Not Change(InitAllowed)" 1 "ON" 2 "OFF" ;
VAL_ 1168 CstmzRq_Contents_VRq04 0 "No Action" 1 "Customize Request" 2 "Initialize Request" ;
VAL_ 1168 CstmzRq_ACC_GCR_ONOFF 0 "Not Change(InitAllowed)" 1 "OFF" 2 "ON" ;
VAL_ 1168 CstmzRq_ACC_ACCL_Sens 0 "Not Change(InitAllowed)" 1 "OFF" 2 "Lo" 3 "Mid" 4 "Hi" 5 "Reserve" 6 "Reserve" 7 "Reserve" ;
VAL_ 1168 CstmzRq_ACC_CURVE_Sens 0 "Not Change(InitAllowed)" 1 "OFF" 2 "Lo" 3 "Mid" 4 "Hi" 5 "Reserve" 6 "Reserve" 7 "Reserve" ;
VAL_ 1168 CstmzRq_ACC_OVTK_ONOFF 0 "Not Change(InitAllowed)" 1 "OFF" 2 "ON" ;
VAL_ 1168 CstmzRq_TMN_LV_Sens 0 "Not Change(InitAllowed)" 1 "Sensitivity_1(Early)" 2 "Sensitivity_2(Mid)" 3 "Sensitivity_3(Late)" 4 "OFF" 5 "Reserve" 6 "Reserve" 7 "Reserve" ;
VAL_ 1168 CstmzRq_TMN_TS_Sens 0 "Not Change(InitAllowed)" 1 "Sensitivity_1(Early)" 2 "Sensitivity_2(Mid)" 3 "Sensitivity_3(Late)" 4 "OFF" 5 "Reserve" 6 "Reserve" 7 "Reserve" ;
VAL_ 1168 CstmzRq_LCA_ONOFF 0 "Not Change(InitAllowed)" 1 "OFF" 2 "ON" ;
VAL_ 1168 CstmzRq_HOF_REC_ONOFF 0 "Not Change(InitAllowed)" 1 "OFF" 2 "ON" ;
VAL_ 1168 CstmzRq_HOF_ONOFF 0 "Not Change(InitAllowed)" 1 "OFF" 2 "ON" ;
VAL_ 1168 CstmzRq_ESA_AES_ONOFF 0 "Not Change(InitAllowed)" 1 "OFF" 2 "ON" ;
VAL_ 1168 CstmzRq_PDA_Sens 0 "Not Change(InitAllowed)" 1 "Sensitivity_1" 2 "Sensitivity_2" 3 "Sensitivity_3" 4 "Reserve" 5 "Reserve" 6 "Reserve" 7 "Reserve" ;
VAL_ 1168 CstmzRq_PDA_ONOFF 0 "Not Change(InitAllowed)" 1 "OFF" 2 "ON" ;
VAL_ 1168 CstmzRq_TVM_MOAAuto_ONOFF 0 "Not Change(InitAllowed)" 1 "OFF" 2 "ON" ;
VAL_ 1168 CstmzRq_TVM_MOA_ONOFF 0 "Not Change(InitAllowed)" 1 "OFF" 2 "ON" ;
VAL_ 1168 CstmzRq_TVM_AutoOFF_ONOFF 0 "Not Change(InitAllowed)" 1 "OFF" 2 "ON" ;
VAL_ 1168 CstmzRq_TVM_PASRear_Sens 0 "Not Change(InitAllowed)" 1 "Middle" 2 "Near" ;
VAL_ 1168 CstmzRq_TVM_PASFront_Sens 0 "Not Change(InitAllowed)" 1 "Middle" 2 "Near" ;
VAL_ 1168 CstmzRq_TVM_PAS_ONOFF 0 "Not Change(InitAllowed)" 1 "OFF" 2 "ON" ;
VAL_ 1168 CstmzRq_Contents_VRq03 0 "No Action" 1 "Customize Request" 2 "Initialize Request" ;
VAL_ 1168 CstmzRq_Init_ALL_ADAS_Prsnl 0 "No Action" 1 "Initialize ALL Data_ID1" 2 "Initialize ALL Data_ID2" 3 "Initialize ALL Data_ID3" 4 "Initialize ALL Data_ID4" 5 "Initialize ALL Data_ID5" 6 "Initialize ALL Data_ID6" 7 "Initialize ALL Data_ALL_ID" 8 "Initialize ALL Data_Guest" 9 "Reserved" 16 "Reserved" 17 "Reserved" 18 "Reserved" 19 "Reserved" 20 "Reserved" 21 "Reserved" 22 "Reserved" 23 "Reserved" 24 "Reserved" 25 "Reserved" 26 "Reserved" 27 "Reserved" 28 "Reserved" 29 "Reserved" 30 "Reserved" 31 "Reserved" ;
VAL_ 1168 CstmzRq_PAS_Vol 0 "Not Change(InitAllowed)" 1 "Volume 1" 2 "Volume 2" 3 "Volume 3" ;
VAL_ 1168 CstmzRq_PAS_ONOFF 0 "Not Change(InitAllowed)" 1 "OFF" 2 "ON" ;
VAL_ 1168 CstmzRq_EDA_ONOFF 0 "Not Change(InitAllowed)" 1 "OFF" 2 "ON" ;
VAL_ 1168 CstmzRq_EDA_Sleep_ONOFF 0 "Not Change(InitAllowed)" 1 "OFF" 2 "ON" ;
VAL_ 1168 CstmzRq_DM_ONOFF 0 "Not Change(InitAllowed)" 1 "OFF" 2 "ON" ;
VAL_ 1168 CstmzRq_OCP_ONOFF 0 "Not Change(InitAllowed)" 1 "OFF" 2 "ON" ;
VAL_ 1168 CstmzRq_BSP_ONOFF 0 "Not Change(InitAllowed)" 1 "OFF" 2 "ON" ;
VAL_ 1168 CstmzRq_RDP_ONOFF 0 "Not Change(InitAllowed)" 1 "OFF" 2 "ON" ;
VAL_ 1168 CstmzRq_ELK_ONOFF 0 "Not Change(InitAllowed)" 1 "OFF" 2 "ON" ;
VAL_ 1168 CstmzRq_RAEB_ONOFF 0 "Not Change(InitAllowed)" 1 "OFF" 2 "ON" ;
VAL_ 1168 CstmzRq_HeadOn_ONOFF 0 "Not Change(InitAllowed)" 1 "OFF" 2 "ON" ;
VAL_ 1168 CstmzRq_TAP_ONOFF 0 "Not Change(InitAllowed)" 1 "OFF" 2 "ON" ;
VAL_ 1168 CstmzRq_CTB_ONOFF 0 "Not Change(InitAllowed)" 1 "OFF" 2 "ON" ;
VAL_ 1168 CstmzRq_AEB_Vol 0 "Not Change(InitAllowed)" 1 "OFF" 2 "ON" ;
VAL_ 1168 CstmzRq_FAEB_ONOFF 0 "Not Change(InitAllowed)" 1 "OFF" 2 "ON" ;
VAL_ 1168 CstmzRq_LDP_ONOFF 0 "Not Change(InitAllowed)" 1 "OFF" 2 "ON" ;
VAL_ 1168 CstmzRq_CBDA_Sens 0 "Not Change(InitAllowed)" 1 "Sensitivity_1(HI)" 2 "Sensitivity_2(Mid)" 3 "Sensitivity_3(LO)" ;
VAL_ 1168 CstmzRq_CBDA_ONOFF 0 "Not Change(InitAllowed)" 1 "OFF" 2 "Sign only" 3 "Sign + Buzzer" ;
VAL_ 1168 CstmzRq_Contents_VRq02 0 "No Action" 1 "Customize Request" 2 "Initialize Request" ;
VAL_ 1168 CstmzRq_Init_ALL_ADAS 0 "No Action" 1 "Initialize ALL Data" ;
VAL_ 1168 CstmzRq_LDW_ELK_Warn 0 "Not Change(InitAllowed)" 1 "OFF" 2 "Vibration" 3 "Buzzer" 4 "Vibration + Buzzer" ;
VAL_ 1168 CstmzRq_BSM_Sens 0 "Not Change(InitAllowed)" 1 "Sensitivity_1(HI)" 2 "Sensitivity_2(Mid)" 3 "Sensitivity_3(LO)" ;
VAL_ 1168 CstmzRq_BSM_ONOFF 0 "Not Change(InitAllowed)" 1 "OFF" 2 "Sign only" 3 "Sign + Warning" 4 "Sign + Vibration" ;
VAL_ 1168 CstmzRq_LDW_ONOFF 0 "Not Change(InitAllowed)" 1 "OFF" 2 "ON" ;
VAL_ 1168 CstmzRq_RCTA_ONOFF 0 "Not Change(InitAllowed)" 1 "OFF" 2 "Sign only" 3 "Sign + Buzzer" ;
VAL_ 1168 CstmzRq_FCTA_Sens 0 "Not Change(InitAllowed)" 1 "Sensitivity_1(HI)" 2 "Sensitivity_2(Mid)" 3 "Sensitivity_3(LO)" ;
VAL_ 1168 CstmzRq_FCTA_ONOFF 0 "Not Change(InitAllowed)" 1 "OFF" 2 "Sign only" 3 "Sign + Buzzer" ;
VAL_ 1168 CstmzRq_TSRWarnThres 0 "Not Change(InitAllowed)" 1 "0kph_0mph" 2 "3kph_3mph" 3 "5kph_5mph" 4 "10kph_10mph" ;
VAL_ 1168 CstmzRq_TSR_Warn 0 "Not Change(InitAllowed)" 1 "OFF" 2 "Sign only" 3 "Sign + Buzzer" ;
VAL_ 1168 CstmzRq_TSR_Change 0 "Not Change(InitAllowed)" 1 "OFF" 2 "ON" ;
VAL_ 1168 CstmzRq_TSR_NextInfo 0 "Not Change(InitAllowed)" 1 "OFF" 2 "ON" ;
VAL_ 1168 CstmzRq_TSR_ONOFF 0 "Not Change(InitAllowed)" 1 "OFF" 2 "ON" ;
VAL_ 1168 CstmzRq_ISA_TSR_ADJST 0 "Not Change(InitAllowed)" 1 "Plus" 2 "Minus" ;
VAL_ 1168 CstmzRq_IACC_TSR_ADJST 0 "Not Change(InitAllowed)" 1 "Plus" 2 "Minus" ;
VAL_ 1168 CstmzRq_MRCC_TSR_Mode 0 "Not Change(InitAllowed)" 1 "OFF" 2 "ON" ;
VAL_ 1168 CstmzRq_MRCC_ASC_Mode 0 "Not Change(InitAllowed)" 1 "OFF(MRCC)" 2 "ON(ASC)" ;
VAL_ 1168 CstmzRq_Contents_VRq01 0 "No Action" 1 "Customize Request" 2 "Initialize Request" ;
VAL_ 1166 Delete_KeyfobDpos_State 0 "No Action" 1 "Waiting for keyless lock" 2 "Complete" 3 "Fail" ;
VAL_ 1166 Record_KeyfobDpos_State 0 "No Action" 1 "Waiting for keyless unlock" 2 "Complete" 3 "Fail" ;
VAL_ 1166 PrsnlDpos_StorageState 0 "Not stored" 1 "stored" ;
VAL_ 1166 KeyfobDpos_StorageState 0 "Not stored" 1 "stored" ;
VAL_ 1166 Mem2Dpos_StorageState 0 "Not stored" 1 "stored" ;
VAL_ 1166 Mem1Dpos_StorageState 0 "Not stored" 1 "stored" ;
VAL_ 1166 PrsnlSys_Switch_ID_ADU_Req 0 "No Action" 1 "Request" ;
VAL_ 1166 PrsnlSys_State3 0 "No Request" 1 "Switch ID" 2 "Identfy ID" 3 "Regist ID" 4 "Erase ID" 5 "Notice Regist ID result" 6 "Initialize Cstmz Data" 7 "Regist Face Data" 8 "Status2" 9 "Reserved" 10 "Reserved" 11 "Reserved" 12 "Reserved" 13 "Reserved" 14 "Reserved" 15 "Reserved" ;
VAL_ 1166 PrsnlSys_IDDB_State 0 "Unknown" 1 "Not registered Cam1/Cam2" 2 "Registered Cam1/Not Cam2" 3 "Registered Cam1/Cam2" 4 "Reserved" 5 "Reserved" 6 "Reserved" 7 "Reserved" ;
VAL_ 1166 Recall_Dpos_State 0 "No Action" 1 "Adjusting (MemSW1)" 2 "Adjusting (MemSW2)" 3 "Adjusting (Prsnl)" 4 "Complete" 5 "Reject" 6 "Reserved" 7 "Reserved" ;
VAL_ 1166 AutoDpos_State 0 "No Action" 1 "Adjusting" 2 "Complete" 3 "Reject" 4 "Reserved" 5 "Reserved" 6 "Reserved" 7 "Reserved" ;
VAL_ 1166 Key_Variants 0 "Unknown" 1 "Normal Key" 2 "Senior Key" 3 "Youth Key" 4 "Reserved" 5 "Reserved" 6 "Reserved" 7 "Reserved" ;
VAL_ 1166 PrsnlSys_Transition_Prohibit 0 "Not prohibit" 1 "Prohibit" ;
VAL_ 1166 PrsnlSys_Switch_ID_CDC_Req 0 "No Action" 1 "Request" ;
VAL_ 1166 PrsnlSys_ID_State 0 "Initial value" 1 "ID1" 2 "ID2" 3 "ID3" 4 "ID4" 5 "ID5" 6 "ID6" 7 "Guest" 8 "Reserved" 9 "Reserved" 10 "Reserved" 11 "Reserved" 12 "Reserved" 13 "Reserved" 14 "Reserved" 15 "Reserved" ;
VAL_ 1166 PrsnlSys_ID6_Regist_State 0 "ID6 not registered" 1 "ID6 registered without Camera" 2 "ID6 registered with Cam1" 3 "ID6 registered with Cam1/Cam2" 4 "Reserved" 5 "Reserved" 6 "Reserved" 7 "Reserved" ;
VAL_ 1166 PrsnlSys_ID5_Regist_State 0 "ID5 not registered" 1 "ID5 registered without Camera" 2 "ID5 registered with Cam1" 3 "ID5 registered with Cam1/Cam2" 4 "Reserved" 5 "Reserved" 6 "Reserved" 7 "Reserved" ;
VAL_ 1166 PrsnlSys_ID4_Regist_State 0 "ID4 not registered" 1 "ID4 registered without Camera" 2 "ID4 registered with Cam1" 3 "ID4 registered with Cam1/Cam2" 4 "Reserved" 5 "Reserved" 6 "Reserved" 7 "Reserved" ;
VAL_ 1166 PrsnlSys_ID3_Regist_State 0 "ID3 not registered" 1 "ID3 registered without Camera" 2 "ID3 registered with Cam1" 3 "ID3 registered with Cam1/Cam2" 4 "Reserved" 5 "Reserved" 6 "Reserved" 7 "Reserved" ;
VAL_ 1166 PrsnlSys_ID2_Regist_State 0 "ID2 not registered" 1 "ID2 registered without Camera" 2 "ID2 registered with Cam1" 3 "ID2 registered with Cam1/Cam2" 4 "Reserved" 5 "Reserved" 6 "Reserved" 7 "Reserved" ;
VAL_ 1166 PrsnlSys_ID1_Regist_State 0 "ID1 not registered" 1 "ID1 registered without Camera" 2 "ID1 registered with Cam1" 3 "ID1 registered with Cam1/Cam2" 4 "Reserved" 5 "Reserved" 6 "Reserved" 7 "Reserved" ;
VAL_ 1166 PrsnlSys_State2 0 "No Category" 1 "Camera1" 2 "Camera2" 3 "Camera1/Camera2" 4 "Reserved" 5 "Reserved" 6 "Reserved" 7 "Reserved" ;
VAL_ 1166 PrsnlSys_State1 0 "No action/Initial value" 1 "Start /On going" 2 "Complete" 3 "Failure" 4 "Suspension" 5 "Time out" 6 "Cancel" 7 "ReStart /On going" ;
VAL_ 1157 Set_Prsnl_DriverNo 0 "Not Used" 1 "Driver 1" 2 "Driver 2" 3 "Driver 3" 4 "Driver 4" 5 "Driver 5" 6 "Driver 6" 7 "Unknown" ;
VAL_ 1157 Set_Prsnl_Enable 0 "Not Used" 1 "Disable" 2 "Enable" ;
VAL_ 1157 Set_TPMSUnit 0 "Not Used" 1 "psi" 2 "kPa" 3 "bar" 4 "kg/cm^2" ;
VAL_ 1157 Set_FuelUnit 0 "Not Used" 1 "Km/L" 2 "L/100km" 3 "Km/gallon_us" 4 "mpg_us" 5 "mpg_uk" ;
VAL_ 1157 Set_DistncUnit 0 "Not Used" 1 "Km-Km/h" 2 "mile-mph" ;
VAL_ 1157 Set_TempUnit 0 "Not Used" 1 "degreeC" 2 "degreeF" ;
VAL_ 1157 Set_DispChrt 0 "Not Used" 1 "Japanese" 2 "ADR_English" 3 "UK_English" 4 "US_English" 5 "CanadianFrench" 6 "MexicanSpanish" 7 "EU_English" 8 "French" 9 "German" 10 "Italian" 11 "Spanish" 12 "Russian" 13 "Portuguese" 14 "Dutch" 15 "Swedish" 16 "Danish" 17 "Norwegian" 18 "Finnish" 19 "Czech" 20 "Slovakian" 21 "Hungarian" 22 "Turkish" 23 "Polish" 24 "Chinese_Mandarin" 25 "Chinese_Cantonese" 26 "Arbic(Gulf)" 27 "Estonian" 28 "Latvian" 29 "Lithuanian" 30 "Greek" 31 "Croatian" 32 "Hebrew" 33 "BahasaMalaysia" 34 "Thai" 35 "Indonesia" 36 "Romanian" 37 "Taiwanese" 38 "Ukrainian" 39 "Vietnamese" 40 "Korea" 41 "Bulgarian" 42 "Serbian" 43 "Slovenian" ;
VAL_ 1154 CstmzStat_DimmerCancel 0 "Not Adopted" 1 "Off" 2 "On" 3 "Reserved" ;
VAL_ 1154 CstmzStat_PanelBrightLevel 0 "Not Adopted" 1 "10" 2 "20" 3 "30" 4 "40" 5 "50" 6 "60" 7 "70" 8 "80" 9 "90" 10 "100" 11 "Reserved" 12 "Reserved" 13 "Reserved" 14 "Reserved" 15 "Reserved" ;
VAL_ 1154 CstmzStat_Facial_Iden_OnOff 0 "Not Adopted" 1 "Off" 2 "On" 3 "Reserved" ;
VAL_ 1154 CstmzStat_Towing_Wt 0 "Not Adopted" 1 "Light" 2 "Mid" 3 "Heavy" 4 "Auto" 5 "Off" ;
VAL_ 1154 CstmzStat_AirCon_Auto_AImode_CO2 0 "Not Adopted" 1 "Off" 2 "On" ;
VAL_ 1154 CstmzStat_AirCon_Auto_AImode 0 "Not Adopted" 1 "Off" 2 "On" ;
VAL_ 1154 CstmzStat_AirCon_Auto_BlwLv 0 "Not Adopted" 1 "Low" 2 "Mid" 3 "High" ;
VAL_ 1154 CstmzStat_AC_Auto_wStrHeatLv 0 "Not Adopted" 1 "Low" 2 "Mid" 3 "High" ;
VAL_ 1154 CstmzStat_AC_Auto_wSeatVentLv_Ps 0 "Not Adopted" 1 "Low" 2 "Mid" 3 "High" ;
VAL_ 1154 CstmzStat_AC_Auto_wSeatHeatLv_Ps 0 "Not Adopted" 1 "Low" 2 "Mid" 3 "High" ;
VAL_ 1154 CstmzStat_AC_Auto_wSeatVentLv_Dr 0 "Not Adopted" 1 "Low" 2 "Mid" 3 "High" ;
VAL_ 1154 CstmzStat_AC_Auto_wSeatHeatLv_Dr 0 "Not Adopted" 1 "Low" 2 "Mid" 3 "High" ;
VAL_ 1154 CstmzStat_RSRmid_GUI_InandEx 0 "Normal" 1 "Gray" 2 "NoDisplay" ;
VAL_ 1154 CstmzStat_RSRmid_GUI_In 0 "Normal" 1 "Gray" 2 "NoDisplay" ;
VAL_ 1154 CstmzStat_RSRmid_GUI_Off 0 "Normal" 1 "Gray" 2 "NoDisplay" ;
VAL_ 1154 CstmzStat_RSRmid 0 "NotAdopted" 1 "Off" 2 "Interior" 3 "Interior and Exterior" ;
VAL_ 1154 CstmzStat_Regen_Select_Rq 0 "Not Adopted" 1 "Normal" 2 "Strong" ;
VAL_ 1154 CstmzStat_Charge_TgtSoc_Rq 0 "Not Adopted" 1 "0%" 2 "10%" 3 "20%" 4 "30%" 5 "40%" 6 "50%" 7 "60%" 8 "70%" 9 "80%" 10 "90%" 11 "100%" 12 "reserved" ;
VAL_ 1154 CstmzStat_Ev_Default_Rq 0 "NotAdopted" 1 "Off" 2 "On" ;
VAL_ 1154 CstmzStat_FullSOC_AC 0 "Not Adopted" 1 "0%" 2 "10%" 3 "20%" 4 "30%" 5 "40%" 6 "50%" 7 "60%" 8 "70%" 9 "80%" 10 "90%" 11 "100%" ;
VAL_ 1154 CstmzStat_FullSOC_QBC 0 "Not Adopted" 1 "0%" 2 "10%" 3 "20%" 4 "30%" 5 "40%" 6 "50%" 7 "60%" 8 "70%" 9 "80%" 10 "90%" 11 "100%" ;
VAL_ 1154 CstmzStat_SupplyStopSOC 0 "Not Adopted" 1 "0%" 2 "10%" 3 "20%" 4 "30%" 5 "40%" 6 "50%" 7 "60%" 8 "70%" 9 "80%" 10 "90%" 11 "100%" ;
VAL_ 1154 CstmzStat_ConnectorLockReq 0 "Not Adopted" 1 "Auto" 2 "Lock" 3 "OFF" ;
VAL_ 1154 CstmzStat_BatHeat_AutoSW 0 "Not Adopted" 1 "Auto" 2 "Off" ;
VAL_ 1154 CstmzStat_AirCon_Auto_wStrHeat 0 "NotAdopted" 1 "Off" 2 "On" ;
VAL_ 1154 CstmzStat_AirCon_Auto_wSeat_Ps 0 "NotAdopted" 1 "Off" 2 "On" ;
VAL_ 1154 CstmzStat_AirCon_Auto_wSeat_Dr 0 "NotAdopted" 1 "Off" 2 "On" ;
VAL_ 1154 CstmzStat_Prsnl_OnOff 0 "Not Adopted" 1 "OFF" 2 "ON" ;
VAL_ 1154 CstmzStat_CHG_W_FreqShiftOnOff 0 "Not Adopted" 1 "OFF" 2 "ON" ;
VAL_ 1154 CstmzStat_CHG_W_OnOff 0 "Not Adopted" 1 "OFF" 2 "ON" ;
VAL_ 1154 CstmzStat_Hud_RotatLvl 0 "Not Adopted" 1 "level - 10" 2 "level - 9" 3 "level - 8" 4 "level - 7" 5 "level - 6" 6 "level - 5" 7 "level - 4" 8 "level - 3" 9 "level - 2" 10 "level - 1" 11 "level 0" 12 "level +1" 13 "level +2" 14 "level +3" 15 "level +4" 16 "level +5" 17 "level +6" 18 "level +7" 19 "level +8" 20 "level +9" 21 "level +10" 22 "Reserved" 23 "Reserved" 24 "Reserved" 25 "Reserved" 26 "Reserved" 27 "Reserved" 28 "Reserved" 29 "Reserved" 31 "Reserved" ;
VAL_ 1154 CstmzStat_Hud_TiltLvl 0 "Not Adopted" 1 "level - 15" 2 "level - 14" 3 "level - 13" 4 "level - 12" 5 "level - 11" 6 "level - 10" 7 "level - 9" 8 "level - 8" 9 "level - 7" 10 "level - 6" 11 "level - 5" 12 "level - 4" 13 "level - 3" 14 "level - 2" 15 "level - 1" 16 "level 0" 17 "level + 1" 18 "level + 2" 19 "level + 3" 20 "level + 4" 21 "level + 5" 22 "level + 6" 23 "level + 7" 24 "level + 8" 25 "level + 9" 26 "level + 10" 27 "level + 11" 28 "level + 12" 29 "level + 13" 30 "level + 14" 31 "level + 15" ;
VAL_ 1154 CstmzStat_Hud_OnOff 0 "Not Adopted" 1 "OFF" 2 "ON" ;
VAL_ 1154 CstmzStat_ALH_ONOFF_GUI_ON_w_M 0 "Normal" 1 "Gray" 2 "NoDisplay" 3 "Reserved" ;
VAL_ 1154 CstmzStat_Paddle_Mde 0 "Not Adopted" 1 "DM" 2 "M" 3 "M_Fix" 4 "DM_M" 5 "DM_M_Fix" ;
VAL_ 1154 CstmzStat_PLG_Handsfree_OnOff 0 "Not Adopted" 1 "OFF" 2 "ON" 3 "Reserve" ;
VAL_ 1154 CstmzStat_PLG_Open_Keylock_Mde 0 "Not Adopted" 1 "Always" 2 "Door unlock only" ;
VAL_ 1154 CstmzStat_FuelLckDelay_T 0 "Not Adopted" 1 "Off" 2 "30sec" 3 "60sec" 4 "90sec" 5 "120sec" ;
VAL_ 1154 CstmzStat_Ind_Clr_OnOff 0 "Not Adopted" 1 "OFF" 2 "ON" ;
VAL_ 1154 CstmzStat_Trip_Rst_Mde 0 "Not Adopted" 1 "A_Type" 2 "B_Type" ;
VAL_ 1154 CstmzStat_PedalWarning 0 "Not Adopted" 1 "OFF" 2 "ON" ;
VAL_ 1154 CstmzStat_RidePos_Lvl 0 "Not Adopted" 1 "Off" 2 "Standard" 3 "Few" ;
VAL_ 1154 CstmzStat_DrvPos_OnOff 0 "Not Adopted" 1 "Off" 2 "On" ;
VAL_ 1154 CstmzStat_Indrctillmntin_Lvl 0 "Not Adopted" 1 "Off" 2 "Dark" 3 "Medium" 4 "Bright" ;
VAL_ 1154 CstmzStat_RmLmpOffDrClose_T 0 "Not Adopted" 1 "7.5sec" 2 "15sec" 3 "30sec" 4 "60sec" ;
VAL_ 1154 CstmzStat_LHL_OnOff 0 "Not Adopted" 1 "Off" 2 "On" ;
VAL_ 1154 CstmzStat_CHL_T 0 "Not Adopted" 1 "Off" 2 "30sec" 3 "60sec" 4 "90sec" 5 "120sec" ;
VAL_ 1154 CstmzStat_LightLeveling 0 "Not Adopted" 1 "0.0" 2 "0.5" 3 "1.0" 4 "1.5" 5 "2.0" 6 "2.5" 7 "3.0" 8 "3.5" 9 "4.0" 10 "4.5" 11 "5.0" ;
VAL_ 1154 CstmzStat_AFS_ONOFF 0 "Not Adopted" 1 "OFF" 2 "ON" ;
VAL_ 1154 CstmzStat_HBC_ONOFF 0 "Not Adopted" 1 "OFF" 2 "ON" ;
VAL_ 1154 CstmzStat_ALH_ONOFF 0 "Not Adopted" 1 "OFF" 2 "ON_wo_M" 3 "ON_w_M" ;
VAL_ 1154 CstmzStat_DRL_OnOff 0 "Not Adopted" 1 "Off" 2 "On" ;
VAL_ 1154 CstmzStat_AtLtOff_T 0 "Not Adopted" 1 "OFF" 2 "30sec" 3 "60sec" 4 "90sec" 5 "120sec" ;
VAL_ 1154 CstmzStat_AutoLight_Sens 0 "Not Adopted" 1 "Extra Lo" 2 "Lo" 3 "Standard" 4 "High" 5 "Extra High" ;
VAL_ 1154 CstmzStat_AB_R_OnOff 0 "Not Adopted" 1 "Off" 2 "On" ;
VAL_ 1154 CstmzStat_AB_P_OnOff 0 "Not Adopted" 1 "Off" 2 "On" ;
VAL_ 1154 CstmzStat_AirCon_Cooperation 0 "Not Adopted" 1 "Off" 2 "On" ;
VAL_ 1154 CstmzStat_RearDef_T 0 "Not Adopted" 1 "15min" 2 "Continuation" ;
VAL_ 1154 CstmzStat_SmtTrn_OnOff 0 "Not Adopted" 1 "Off" 2 "On" ;
VAL_ 1154 CstmzStat_AtStorageMirror_OnOff 0 "Not Adopted" 1 "Off" 2 "On" ;
VAL_ 1154 CstmzStat_AtWpr_OnOff 0 "Not Adopted" 1 "Off" 2 "On" ;
VAL_ 1154 CstmzStat_KylssChm_Vol 0 "Not Adopted" 1 "Off" 2 "Small" 3 "Middle" 4 "Big" ;
VAL_ 1154 CstmzStat_KylssWal_OnOff 0 "Not Adopted" 1 "Off" 2 "On" ;
VAL_ 1154 CstmzStat_KylssUnlck_Mde 0 "Not Adopted" 1 "All seat" 2 "Driver seat only" 3 "Other" ;
VAL_ 1154 CstmzStat_KylssAtLck_T 0 "Not Adopted" 1 "30 sec" 2 "60 sec" 3 "90 sec" ;
VAL_ 1154 CstmzStat_AtDrLck_Mde_MT 0 "Not Adopted" 1 "Mode1_Off" 2 "Mode2_LockDriving" 3 "Mode3_LockDriving_UnlockIGOff" ;
VAL_ 1154 CstmzStat_AtDrLck_Mde_AT 0 "Not Adopted" 1 "Mode1_Off" 2 "Mode2_LockDriving" 3 "Mode3_LockDriving_UnlockIGOff" 4 "Mode4_LockShift" 5 "Mode5_LockUnlockShift" 6 "Mode6_LockDriving_UnlockShift" ;
VAL_ 1154 CstmzStat_Prsnl_DriverNo 0 "Not Adopted" 1 "Driver 1" 2 "Driver 2" 3 "Driver 3" 4 "Driver 4" 5 "Driver 5" 6 "Driver 6" 7 "Unknown" ;
VAL_ 1154 CstmzStat_Prsnl_Enable 0 "Not Adopted" 1 "Disable" 2 "Enable" ;
VAL_ 1154 CstmzStat_TPMSUnit 0 "Not Adopted" 1 "psi" 2 "kPa" 3 "bar" 4 "kg/cm^2" ;
VAL_ 1154 CstmzStat_FuelUnit 0 "NotAdopted" 1 "Km/L" 2 "L/100km" 3 "Km/gallon_us" 4 "mpg_us" 5 "mpg_uk" ;
VAL_ 1154 CstmzStat_DistncUnit 0 "Not Adopted" 1 "Km-Km/h" 2 "mile-mph" ;
VAL_ 1154 CstmzStat_TempUnit 0 "Not Adopted" 1 "degreeC" 2 "degreeF" ;
VAL_ 1154 CstmzStat_DispChrt 0 "Not Adopted" 1 "Japanese" 2 "ADR_English" 3 "UK_English" 4 "US_English" 5 "CanadianFrench" 6 "MexicanSpanish" 7 "EU_English" 8 "French" 9 "German" 10 "Italian" 11 "Spanish" 12 "Russian" 13 "Portuguese" 14 "Dutch" 15 "Swedish" 16 "Danish" 17 "Norwegian" 18 "Finnish" 19 "Czech" 20 "Slovakian" 21 "Hungarian" 22 "Turkish" 23 "Polish" 24 "Chinese_Mandarin" 25 "Chinese_Cantonese" 26 "Arbic(Gulf)" 27 "Estonian" 28 "Latvian" 29 "Lithuanian" 30 "Greek" 31 "Croatian" 32 "Hebrew" 33 "BahasaMalaysia" 34 "Thai" 35 "Indonesia" 36 "Romanian" 37 "Taiwanese" 38 "Ukrainian" 39 "Vietnamese" 40 "Korea" 41 "Bulgarian" 42 "Serbian" 43 "Slovenian" ;
VAL_ 1148 IPAVOICE 0 "state0" 1 "state1" 2 "state2" 3 "state3" 4 "state4" 5 "state5" 6 "state6" 7 "state7" 8 "state8" 9 "state9" 10 "state10" 11 "state11" 12 "state12" 13 "state13" 14 "state14" 15 "state15" 16 "state16" 17 "state17" 18 "state18" 19 "state19" 20 "state20" 21 "state21" 22 "state22" 23 "state23" 24 "state24" 25 "state25" 26 "state26" 27 "state27" 28 "state28" 29 "state29" 30 "state30" 31 "state31" 32 "state32" 33 "state33" 34 "state34" 35 "state35" 36 "state36" 37 "state37" 38 "state38" 39 "state39" 40 "state40" 41 "state41" 42 "state42" 43 "state43" 44 "state44" 45 "state45" 46 "state46" 47 "state47" 48 "state48" 49 "state49" 50 "state50" 51 "state51" 52 "state52" 53 "state53" 54 "state54" 55 "state55" 56 "state56" 57 "state57" 58 "state58" 59 "state59" 60 "state60" 61 "state61" 62 "state62" 63 "state63" ;
VAL_ 1148 IPAR_EXT 0 "Without Reverse Sync" 1 "With Reverse Sync" ;
VAL_ 1125 LocateTime_Info_Data_Number 0 "Data1" 1 "Data2" 2 "Data3" 3 "Data4" ;
VAL_ 1120 OCS_Stat_D_Actl_3rdL 0 "Unknown" 1 "Vacancy" 2 "Occupied" 3 "Malfunction" ;
VAL_ 1120 OCS_Stat_D_Actl_3rdR 0 "Unknown" 1 "Vacancy" 2 "Occupied" 3 "Malfunction" ;
VAL_ 1120 DrLock_Message_R_Rsp 0 "Unknown" 1 "NG" 2 "OK" ;
VAL_ 1120 RR_OCS_Stat_D_Actl 0 "Unknown" 1 "Vacancy" 2 "Occupied" 3 "Malfunction" ;
VAL_ 1120 RC_OCS_Stat_D_Actl 0 "Unknown" 1 "Vacancy" 2 "Occupied" 3 "Malfunction" ;
VAL_ 1120 RL_OCS_Stat_D_Actl 0 "Unknown" 1 "Vacancy" 2 "Occupied" 3 "Malfunction" ;
VAL_ 1120 DrStatRl_B_Actl 0 "Door Closed" 1 "Door Ajar" ;
VAL_ 1120 DrStatR_D_Qf 0 "Faulty" 1 "Undefined" 2 "Not within specification" 3 "OK" ;
VAL_ 1120 TrnkLg_Motor_Stat 0 "Not Drive" 1 "Drive" ;
VAL_ 1120 Fuel_Lid_Open_Status 0 "Door Closed" 1 "Door Ajar" ;
VAL_ 1120 StopLampCon_Status 0 "StopLampOff" 1 "StopLampOn" 2 "Hard_Failure" 3 "Communication_Failure" ;
VAL_ 1120 DrStatTrnkLg_B_Actl 0 "Door Closed" 1 "Door Ajar" ;
VAL_ 1120 ParkBrkActv_D_Actl2 0 "Off" 1 "ON" 2 "Reserved" 3 "Unknown" ;
VAL_ 1120 AutoHoldSw_B_Actl 0 "Off" 1 "On" ;
VAL_ 1112 DrvrID_Request_Target 0 "Initial value" 1 "DrvrID1" 2 "DrvrID2" 3 "DrvrID3" 4 "DrvrID4" 5 "DrvrID5" 6 "DrvrID6" 7 "DrvrID7" 8 "DrvrID8" 9 "DrvrID9" 10 "DrvrID10" 11 "DrvrID11" 12 "DrvrID12" 13 "All" 14 "Reserved" 15 "Reserved" ;
VAL_ 1112 Deletion_Cancel_Request 0 "No request" 1 "Request" ;
VAL_ 1112 Deletion_Start_Request 0 "No request" 1 "Request" ;
VAL_ 1112 Registration_Cancel_Request 0 "No request" 1 "Request" ;
VAL_ 1112 Registration_Start_Request 0 "No request" 1 "Request" ;
VAL_ 1112 Identification_Cancel_Request 0 "No request" 1 "Request" ;
VAL_ 1112 Identification_Start_Request 0 "No request" 1 "Request" ;
VAL_ 1109 VCU_rear 0 "not adopted" 1 "CMU All OFF" 2 "CMU Part OFF" 3 "SW OFF" 4 "Active" 5 "Inactive_tmp failure" 6 "failure" ;
VAL_ 1109 VCU_rearside 0 "not adopted" 1 "CMU All OFF" 2 "CMU Part OFF" 3 "SW OFF" 4 "Active" 5 "Inactive_tmp failure" 6 "failure" ;
VAL_ 1109 VCU_side 0 "not adopted" 1 "CMU All OFF" 2 "CMU Part OFF" 3 "SW OFF" 4 "Active" 5 "Inactive_tmp failure" 6 "failure" ;
VAL_ 1109 VCU_frontside 0 "not adopted" 1 "CMU All OFF" 2 "CMU Part OFF" 3 "SW OFF" 4 "Active" 5 "Inactive_tmp failure" 6 "failure" ;
VAL_ 1109 VCU_front 0 "not adopted" 1 "CMU All OFF" 2 "CMU Part OFF" 3 "SW OFF" 4 "Active" 5 "Inactive_tmp failure" 6 "failure" ;
VAL_ 1109 VCU_state 0 "normal" 1 "towing_mode" 2 "towing_mode_rear" 3 "reserved" 4 "reserved" 5 "reserved" 6 "reserved" 7 "reserved" 8 "reserved" 9 "reserved" 10 "reserved" 11 "reserved" 12 "reserved" 13 "reserved" 14 "reserved" 15 "failure" ;
VAL_ 1109 VCU_mute_State 0 "NOT Mute State" 1 "Mute State" ;
VAL_ 1109 DAS_state 0 "not adopted" 1 "off" 2 "inactive" 3 "active" 4 "control" 5 "notification" 12 "towing off" 13 "temporary failure" 14 "initialization" 15 "failure" ;
VAL_ 1109 OMC_Sensing_State 0 "not adopted" 1 "off" 2 "nomal" 3 "degradation" 4 "reserved" 5 "reserved" 6 "reserved" 7 "reserved" ;
VAL_ 1109 OMC_state 0 "normal" 1 "blockage" 2 "degradation" 3 "backlit" 4 "high_temperature" 5 "low sun" 6 "not_aligned" 7 "calibration" 8 "reserved" 9 "reserved" 10 "system_failure" 11 "cam_failure" 12 "led_failure" 13 "test" 14 "init" 15 "failure" ;
VAL_ 1109 AMAP_state 0 "normal" 1 "limited" 2 "reserved" 3 "reserved" 4 "reserved" 5 "reserved" 6 "reserved" 7 "reserved" 8 "reserved" 9 "reserved" 10 "reserved" 11 "reserved" 12 "reserved" 13 "reserved" 14 "gpsant_failure" 15 "unit_failure" ;
VAL_ 1109 V2X_state 0 "normal" 1 "normal_v2v" 2 "normal_v2i" 3 "normal_v2vi" 4 "limited" 5 "reserved" 6 "reserved" 7 "reserved" 8 "reserved" 9 "reserved" 10 "reserved" 11 "reserved" 12 "reserved" 13 "reserved" 14 "gpsant_failure" 15 "unit_failure" ;
VAL_ 1109 VMC4_state 0 "normal" 1 "abnormal" ;
VAL_ 1109 VMC3_state 0 "normal" 1 "abnormal" ;
VAL_ 1109 VMC2_state 0 "normal" 1 "abnormal" ;
VAL_ 1109 VMC1_state 0 "normal" 1 "abnormal" ;
VAL_ 1109 VMC_state 0 "normal" 1 "blockage" 2 "degradation" 3 "backlit" 4 "high_temperature" 5 "low sun" 6 "not_aligned" 7 "calibration" 8 "reserved" 9 "reserved" 10 "system_failure" 11 "cam_failure" 12 "led_failure" 13 "test" 14 "init" 15 "failure" ;
VAL_ 1109 SONAR_state12 0 "normal" 1 "abnormal" ;
VAL_ 1109 SONAR_state11 0 "normal" 1 "abnormal" ;
VAL_ 1109 SONAR_state10 0 "normal" 1 "abnormal" ;
VAL_ 1109 SONAR_state9 0 "normal" 1 "abnormal" ;
VAL_ 1109 SONAR_state8 0 "normal" 1 "abnormal" ;
VAL_ 1109 SONAR_state7 0 "normal" 1 "abnormal" ;
VAL_ 1109 SONAR_state6 0 "normal" 1 "abnormal" ;
VAL_ 1109 SONAR_state5 0 "normal" 1 "abnormal" ;
VAL_ 1109 SONAR_state4 0 "normal" 1 "abnormal" ;
VAL_ 1109 SONAR_state3 0 "normal" 1 "abnormal" ;
VAL_ 1109 SONAR_state2 0 "normal" 1 "abnormal" ;
VAL_ 1109 SONAR_state1 0 "normal" 1 "abnormal" ;
VAL_ 1109 SONAR_state 0 "normal" 1 "blockage" 2 "high_temperature" 3 "sensor_failure" 4 "reserved" 5 "reserved" 6 "reserved" 7 "reserved" 8 "reserved" 9 "reserved" 10 "reserved" 11 "reserved" 12 "reserved" 13 "test" 14 "init" 15 "failure" ;
VAL_ 1109 RSRDR_state 0 "normal" 1 "blockage" 2 "vibration" 3 "interference" 4 "high_temperature" 5 "not_aligned" 6 "sensor_failure" 7 "reserved" 8 "reserved" 9 "reserved" 10 "reserved" 11 "reserved" 12 "calibration" 13 "test" 14 "init" 15 "failure" ;
VAL_ 1109 FSRDR_state 0 "normal" 1 "blockage" 2 "vibration" 3 "interference" 4 "high_temperature" 5 "not_aligned" 6 "sensor_failure" 7 "reserved" 8 "reserved" 9 "reserved" 10 "reserved" 11 "reserved" 12 "calibration" 13 "test" 14 "init" 15 "failure" ;
VAL_ 1109 FRDR_state 0 "normal" 1 "blockage" 2 "vibration" 3 "interference" 4 "high_temperature" 5 "not_aligned" 6 "sensor_failure" 7 "reserved" 8 "reserved" 9 "reserved" 10 "reserved" 11 "reserved" 12 "calibration" 13 "test" 14 "init" 15 "failure" ;
VAL_ 1109 FSC_state 0 "normal" 1 "blockage" 2 "degradation" 3 "backlit" 4 "high_temperature" 5 "low sun" 6 "not_aligned" 7 "calibration" 8 "reserved" 9 "reserved" 10 "system_failure" 11 "cam_failure" 12 "led_failure" 13 "test" 14 "init" 15 "failure" ;
VAL_ 1109 REDKEY_state 0 "not adopted" 1 "off" 2 "inactive" 3 "active" 4 "control" 5 "notification" 6 "reserved" 7 "reserved" 8 "reserved" 9 "reserved" 10 "reserved" 11 "reserved" 12 "towing off" 13 "temporary failure" 14 "initialization" 15 "failure" ;
VAL_ 1108 LKA_handsfree 0 "no event" 1 "handsfree1 event" 2 "handsfree2 event" 3 "handsfree3 event" 4 "look off" 5 "haptic brake" 6 "RMF decel" 7 "SOS support" ;
VAL_ 1108 RMF_CMU_disp_select 0 "No disp" 1 "RMF decel w/o hazard" 2 "RMF decel w/ hazard" 3 "RMF evacuation ready left" 4 "RMF evacuation ready right" 5 "RMF evacuation left" 6 "RMF evacuation right" ;
VAL_ 1108 EDA_cancel_timer 0 "No display" 1 "1sec_ago" 2 "2sec_ago" 3 "3sec_ago" 4 "4sec_ago" 5 "5sec_ago" 6 "6sec_ago" 7 "7sec_ago" 8 "8sec_ago" 9 "9sec_ago" 10 "10sec_ago" 11 "11sec_ago" 12 "12sec_ago" 13 "13sec_ago" 14 "14sec_ago" 15 "15sec_ago" 16 "16sec_ago" 17 "17sec_ago" 18 "18sec_ago" 19 "19sec_ago" 20 "20sec_ago" 21 "21sec_ago" 22 "22sec_ago" 23 "23sec_ago" 24 "24sec_ago" 25 "25sec_ago" 26 "26sec_ago" 27 "27sec_ago" 28 "28sec_ago" 29 "29sec_ago" 30 "30sec_ago" 31 "31sec_ago" ;
VAL_ 1108 LKA_EV_RMF_cancel 0 "no event" 1 "event occurrence" ;
VAL_ 1108 EDA_EV_cancel 0 "no event" 1 "event occurrence" ;
VAL_ 1108 EDA_state 0 "not adopted" 1 "off" 2 "inactive" 3 "active" 6 "control3" 7 "control4" 8 "control5" 9 "control6(warning no hazard)" 10 "control7(warning hazard)" 11 "control8(decel)" 12 "control9(road side ready)" 13 "control10(road side)" 14 "control11" 15 "control12" 16 "control13(SOS support)" 17 "control14" 18 "Failure" ;
VAL_ 1108 TVM_state 0 "not adopted" 1 "off" 2 "inactive" 3 "active(PNDM range)" 4 "control" 5 "notification" 6 "reserved" 7 "reserved" 8 "active(R range)" 9 "active(other control)" 10 "reserved" 11 "reserved" 12 "towing off" 13 "temporary failure" 14 "initialization" 15 "failure" ;
VAL_ 1108 APS_RPC_state 0 "not adopted" 1 "off" 2 "inactive" 3 "active" 4 "control" 5 "notification" 6 "reserved" 7 "reserved" 8 "reserved" 9 "reserved" 10 "reserved" 11 "reserved" 12 "towing off" 13 "temporary failure" 14 "initialization" 15 "failure" ;
VAL_ 1108 HBC_high 0 "Off" 1 "On" ;
VAL_ 1108 HBC_state 0 "not adopted" 1 "off" 2 "inactive" 3 "active" 4 "control" 5 "notification" 6 "reserved" 7 "reserved" 8 "reserved" 9 "reserved" 10 "reserved" 11 "reserved" 12 "towing off" 13 "temporary failure" 14 "initialization" 15 "failure" ;
VAL_ 1108 ALH_high 0 "Off" 1 "On" ;
VAL_ 1108 ALH_state 0 "not adopted" 1 "off" 2 "inactive" 3 "active" 4 "control" 5 "notification" 6 "reserved" 7 "reserved" 8 "reserved" 9 "reserved" 10 "reserved" 11 "reserved" 12 "towing off" 13 "temporary failure" 14 "initialization" 15 "failure" ;
VAL_ 1108 DAA_state 0 "not adopted" 1 "off" 2 "inactive" 3 "active" 4 "control" 5 "notification" 6 "reserved" 7 "reserved" 8 "reserved" 9 "reserved" 10 "reserved" 11 "reserved" 12 "towing off" 13 "temporary failure" 14 "initialization" 15 "failure" ;
VAL_ 1108 DM_EV_time_intrvl_drowsy 0 "no event" 1 "event occurrence" ;
VAL_ 1108 DM_EV_engage_awake 0 "no event" 1 "event occurrence" ;
VAL_ 1108 DM_state 0 "not adopted" 1 "off" 2 "inactive" 3 "active" 4 "control" 5 "notification" 6 "reserved" 7 "reserved" 8 "reserved" 9 "reserved" 10 "reserved" 11 "reserved" 12 "towing off" 13 "temporary failure" 14 "initialization" 15 "failure" ;
VAL_ 1106 PALNMID2 0 "on display1" 1 "on display2" 2 "on display3" 3 "no display" ;
VAL_ 1106 PALDAL 0 "OFF" 1 "ON" ;
VAL_ 1106 PALNTYL 0 "none" 1 "solid line" 2 "dots line" 3 "reserved" ;
VAL_ 1106 PALNMID1 0 "on display1" 1 "on display2" 2 "on display3" 3 "no display" ;
VAL_ 1106 PALDAR 0 "OFF" 1 "ON" ;
VAL_ 1106 PALNTYR 0 "none" 1 "solid line" 2 "dots line" 3 "reserved" ;
VAL_ 1106 PALNMKST 0 "off" 1 "gray(lta_on)" 2 "green(lta_control)" 3 "bule(adtja)" ;
VAL_ 1106 PATGTST 0 "gray(acc_off)" 1 "silver(acc_override)" 2 "green(acc_on)" 3 "bule(adtja_on)" 4 "amber_01(acc_approach_warning1)" 5 "amber_02(acc_approach_warning2)" 6 "reserved" 7 "reserved" ;
VAL_ 1106 PATRJSPD 0 "off" 1 "speed1" 2 "speed2" 3 "speed3" 4 "speed4" 5 "reserved" 6 "reserved" 7 "reserved" ;
VAL_ 1106 PARSRCGR 0 "OFF" 1 "ON" ;
VAL_ 1106 PARSRCGL 0 "OFF" 1 "ON" ;
VAL_ 1106 PAVLOST 0 "off" 1 "on_right" 2 "on_left" 3 "reserved" ;
VAL_ 1106 PAMODE 0 "Chauffeur Mode" 1 "Guardian Mode" 2 "Manual Driving Mode" 3 "reserved" ;
VAL_ 1106 PARDSTL 0 "OFF" 1 "ON" ;
VAL_ 1106 PARDSTR 0 "OFF" 1 "ON" ;
VAL_ 1106 PAALNTYL 0 "none" 1 "solid line" 2 "dots line" 3 "reserved" ;
VAL_ 1106 PAALNTYR 0 "none" 1 "solid line" 2 "dots line" 3 "reserved" ;
VAL_ 1106 PAAMBST 0 "gray(acc_off)" 1 "silver(acc_override)" 2 "green(acc_on)" 3 "bule(adtja_on)" 4 "amber_01(acc_approach_warning1)" 5 "amber_02(acc_approach_warning2)" 6 "reserved" 7 "reserved" ;
VAL_ 1106 PALCTRJ 0 "OFF" 1 "ON" ;
VAL_ 1106 PALCSP 0 "OFF" 1 "ON" ;
VAL_ 1106 PABSML 0 "OFF" 1 "ON" ;
VAL_ 1106 PABSMR 0 "OFF" 1 "ON" ;
VAL_ 1105 PAOBJST6 0 "none" 1 "detection" 2 "control target" 3 "warning1" 4 "warning2" 5 "reserved" 6 "reserved" 7 "reserved" ;
VAL_ 1105 PAOBJTY6 0 "none" 1 "vehicle" 2 "truck" 3 "bike" 4 "pedestrian" 5 "reserved" 6 "reserved" 7 "reserved" ;
VAL_ 1105 PAOBJST5 0 "none" 1 "detection" 2 "control target" 3 "warning1" 4 "warning2" 5 "reserved" 6 "reserved" 7 "reserved" ;
VAL_ 1105 PAOBJTY5 0 "none" 1 "vehicle" 2 "truck" 3 "bike" 4 "pedestrian" 5 "reserved" 6 "reserved" 7 "reserved" ;
VAL_ 1105 PAOBJST4 0 "none" 1 "detection" 2 "control target" 3 "warning1" 4 "warning2" 5 "reserved" 6 "reserved" 7 "reserved" ;
VAL_ 1105 PAOBJTY4 0 "none" 1 "vehicle" 2 "truck" 3 "bike" 4 "pedestrian" 5 "reserved" 6 "reserved" 7 "reserved" ;
VAL_ 1105 PAOBJST3 0 "none" 1 "detection" 2 "control target" 3 "warning1" 4 "warning2" 5 "reserved" 6 "reserved" 7 "reserved" ;
VAL_ 1105 PAOBJTY3 0 "none" 1 "vehicle" 2 "truck" 3 "bike" 4 "pedestrian" 5 "reserved" 6 "reserved" 7 "reserved" ;
VAL_ 1105 PAOBJST2 0 "none" 1 "detection" 2 "control target" 3 "warning1" 4 "warning2" 5 "reserved" 6 "reserved" 7 "reserved" ;
VAL_ 1105 PAOBJTY2 0 "none" 1 "vehicle" 2 "truck" 3 "bike" 4 "pedestrian" 5 "reserved" 6 "reserved" 7 "reserved" ;
VAL_ 1105 PAOBJST1 0 "none" 1 "detection" 2 "control target" 3 "warning1" 4 "warning2" 5 "reserved" 6 "reserved" 7 "reserved" ;
VAL_ 1105 PAOBJTY1 0 "none" 1 "vehicle" 2 "truck" 3 "bike" 4 "pedestrian" 5 "reserved" 6 "reserved" 7 "reserved" ;
VAL_ 1104 FRC_WRN 0 "No Warning" 1 "Very Close Distance" 2 "Close Distance" ;
VAL_ 1104 FLC_WRN 0 "No Warning" 1 "Very Close Distance" 2 "Close Distance" ;
VAL_ 1104 FR_WRN 0 "No Warning" 1 "Very Close Distance" 2 "Close Distance" ;
VAL_ 1104 FL_WRN 0 "No Warning" 1 "Very Close Distance" 2 "Close Distance" ;
VAL_ 1104 FRC_POS 0 "No Disp" 1 "No Detection" 2 "Very Close Distance" 3 "Close Distance" 4 "Middle Distance" 5 "Far Distance" 6 "Very Far Distance" ;
VAL_ 1104 FLC_POS 0 "No Disp" 1 "No Detection" 2 "Very Close Distance" 3 "Close Distance" 4 "Middle Distance" 5 "Far Distance" 6 "Very Far Distance" ;
VAL_ 1104 FR_POS 0 "No Disp" 1 "No Detection" 2 "Very Close Distance" 3 "Close Distance" 4 "Middle Distance" 5 "Far Distance" 6 "Very Far Distance" ;
VAL_ 1104 FL_POS 0 "No Disp" 1 "No Detection" 2 "Very Close Distance" 3 "Close Distance" 4 "Middle Distance" 5 "Far Distance" 6 "Very Far Distance" ;
VAL_ 1104 RRC_WRN 0 "No Warning" 1 "Very Close Distance" 2 "Close Distance" ;
VAL_ 1104 RLC_WRN 0 "No Warning" 1 "Very Close Distance" 2 "Close Distance" ;
VAL_ 1104 RR_WRN 0 "No Warning" 1 "Very Close Distance" 2 "Close Distance" ;
VAL_ 1104 RL_WRN 0 "No Warning" 1 "Very Close Distance" 2 "Close Distance" ;
VAL_ 1104 RRC_POS 0 "No Disp" 1 "No Detection" 2 "Very Close Distance" 3 "Close Distance" 4 "Middle Distance" 5 "Far Distance" 6 "Very Far Distance" ;
VAL_ 1104 RLC_POS 0 "No Disp" 1 "No Detection" 2 "Very Close Distance" 3 "Close Distance" 4 "Middle Distance" 5 "Far Distance" 6 "Very Far Distance" ;
VAL_ 1104 RR_POS 0 "No Disp" 1 "No Detection" 2 "Very Close Distance" 3 "Close Distance" 4 "Middle Distance" 5 "Far Distance" 6 "Very Far Distance" ;
VAL_ 1104 RL_POS 0 "No Disp" 1 "No Detection" 2 "Very Close Distance" 3 "Close Distance" 4 "Middle Distance" 5 "Far Distance" 6 "Very Far Distance" ;
VAL_ 1104 CSRDISP1 0 "no disp" 1 "on disp" ;
VAL_ 1104 CSMUTESW 0 "no disp" 1 "on disp" 2 "mute" ;
VAL_ 1104 PAS_EV_silent 0 "no event" 1 "event occurrence" ;
VAL_ 1104 PAS_state 0 "not adopted" 1 "off" 2 "inactive" 3 "active" 4 "reserved" 5 "reserved" 6 "reserved" 7 "no display(on_invisible)" 8 "active(on_silent)" 9 "reserved" 10 "reserved" 11 "reserved" 12 "towing off" 13 "temporary failure" 14 "initialization" 15 "failure" ;
VAL_ 1104 TSR_EV_tmp_failure 0 "no event" 1 "temporary failure event" ;
VAL_ 1104 TSR_EV_fallback 0 "no event" 1 "fallback event" ;
VAL_ 1104 TSR_fallback 0 "normal range" 1 "fallback1" 2 "fallback2" 3 "reserved" ;
VAL_ 1104 TSR_sound 0 "no sound" 1 "sound" ;
VAL_ 1104 TSR_EV_change 0 "no event" 1 "change event" ;
VAL_ 1104 TSR_EV_failure 0 "no event" 1 "failure event" ;
VAL_ 1104 TSR_EV_notification 0 "no event" 1 "notification event" ;
VAL_ 1104 TSR_warning 0 "nowarning" 1 "warning1" 2 "warning2" 3 "warning3" ;
VAL_ 1104 TSR_state 0 "not adopted" 1 "off" 2 "inactive" 3 "active" 4 "reserved" 5 "reserved" 6 "reserved" 7 "reserved" 8 "reserved" 9 "reserved" 10 "reserved" 11 "reserved" 12 "towing off" 13 "temporary failure" 14 "initialization" 15 "failure" ;
VAL_ 1104 LCA_EV_warn_approach_rh 0 "no event" 1 "event occurrence" ;
VAL_ 1104 LCA_EV_warn_approach_lh 0 "no event" 1 "event occurrence" ;
VAL_ 1104 LCA_EV_auto_standby 0 "no event" 1 "event occurrence" ;
VAL_ 1104 LCA_EV_calcel_lka_off 0 "no event" 1 "event occurrence" ;
VAL_ 1104 LCA_EV_calcel_lka_on 0 "no event" 1 "event occurrence" ;
VAL_ 1104 LCA_state_lh 0 "not adopted" 1 "off" 2 "inactive" 3 "active" 4 "control" 5 "notification" 6 "override" 7 "reserved" 8 "reserved" 9 "reserved" 10 "reserved" 11 "reserved" 12 "towing off" 13 "temporary failure" 14 "initialization" 15 "failure" ;
VAL_ 1104 LCA_state_rh 0 "not adopted" 1 "off" 2 "inactive" 3 "active" 4 "control" 5 "notification" 6 "override" 7 "reserved" 8 "reserved" 9 "reserved" 10 "reserved" 11 "reserved" 12 "towing off" 13 "temporary failure" 14 "initialization" 15 "failure" ;
VAL_ 1104 LCA_state 0 "not adopted" 1 "off" 2 "inactive" 3 "active" 4 "control" 5 "notification" 6 "override" 7 "reserved" 8 "reserved" 9 "reserved" 10 "reserved" 11 "reserved" 12 "towing off" 13 "temporary failure" 14 "initialization" 15 "failure" ;
VAL_ 1104 HoF_handson_request_mute 0 "no mute" 1 "pre TD mote" 2 "pre FADEOUT mote" 3 "reserved" ;
VAL_ 1104 HOF_approval_rec_state 0 "none" 1 "approval rec disp" ;
VAL_ 1104 HOF_rec_state 0 "no rec" 1 "with rec" ;
VAL_ 1104 HOF_state 0 "not adopted" 1 "off" 2 "inactive" 3 "active" 4 "control" 5 "notification" 6 "override" 7 "reserved" 8 "hands on req1" 9 "hands on req2" 10 "hands on req3" 11 "reserved" 12 "towing off" 13 "temporary failure" 14 "initialization" 15 "failure" ;
VAL_ 1104 LKA_controllimit 0 "not adopted" 1 "controllimit" ;
VAL_ 1104 LKA_state 0 "not adopted" 1 "off" 2 "inactive" 3 "active" 4 "control" 5 "notification" 6 "override" 7 "reserved" 8 "reserved" 9 "reserved" 10 "reserved" 11 "reserved" 12 "towing off" 13 "temporary failure" 14 "initialization" 15 "failure" ;
